VERSION "dbc-export 1 2026.26.6.5"

NS_ :

BS_:

BU_: ADSP APB APP APS APSB BB BMS CC CMP CMPD CP DAS DI DIF DIR DPB EPAS3P EPAS3S EPASTP EPASTS EPBL EPBR ESP EVSE FC GTW HCML HCMR HVP IBST ICR IDB LS OCS1P ODIN PARK PCS PCS2 PLG PM PMF PMR PNCD PTC RADC RCM RCM2 RCM3 RCU SCCM SCM SCS SDCR TAS TCU TCU2 TPMS TRCM UDS UI UIS UMC USM V2G VC VCBATT VCBATT0 VCBATT1 VCBATT2 VCCC VCFRONT VCFRONT1 VCFRONT2 VCLEFT VCRIGHT VCSEAT2L VCSEAT2R VCSEC VEH

BO_ 1290 HVP_alertLog: 8 HVP
 SG_ HVP_alertID M : 0|7@1+ (1,0) [0|127] "" Vector__XXX
 SG_ HVP_alertSet : 15|1@1+ (1,0) [0|1] "" Vector__XXX
 SG_ HVP_a005_current m5 : 16|24@1- (0.001,0) [-8388.608|8388.607] "A" Vector__XXX
 SG_ HVP_a006_current m6 : 16|24@1- (0.001,0) [-8388.608|8388.607] "A" Vector__XXX
 SG_ HVP_a007_current m7 : 16|24@1- (0.001,0) [-8388.608|8388.607] "A" Vector__XXX
 SG_ HVP_a008_temperature m8 : 16|16@1- (0.01,0) [-327.68|327.67] "C" Vector__XXX
 SG_ HVP_a008_sensorId m8 : 32|6@1+ (1,1) [1|64] "" Vector__XXX
 SG_ HVP_a008_primaryChainSensor m8 : 38|1@1+ (1,0) [0|1] "" Vector__XXX
 SG_ HVP_a009_brickVoltage m9 : 16|16@1- (0.001,0) [-32.768|32.767] "V" Vector__XXX
 SG_ HVP_a009_brickId m9 : 32|7@1+ (1,1) [1|128] "" Vector__XXX
 SG_ HVP_a009_primaryChainSensor m9 : 39|1@1+ (1,0) [0|1] "" Vector__XXX
 SG_ HVP_a010_brickVoltage m10 : 16|16@1- (0.001,0) [-32.768|32.767] "V" Vector__XXX
 SG_ HVP_a010_brickId m10 : 32|7@1+ (1,1) [1|128] "" Vector__XXX
 SG_ HVP_a010_primaryChainSensor m10 : 39|1@1+ (1,0) [0|1] "" Vector__XXX
 SG_ HVP_a012_breakLocationA m12 : 16|5@1+ (1,0) [0|31] "" Vector__XXX
 SG_ HVP_a012_bmbCommStatusTypeA m12 : 21|2@1+ (1,0) [0|3] "" Vector__XXX
 SG_ HVP_a012_breakLocationB m12 : 24|5@1+ (1,0) [0|31] "" Vector__XXX
 SG_ HVP_a012_bmbCommStatusTypeB m12 : 29|2@1+ (1,0) [0|3] "" Vector__XXX
 SG_ HVP_a013_breakLocationA m13 : 16|5@1+ (1,0) [0|31] "" Vector__XXX
 SG_ HVP_a013_bmbCommStatusTypeA m13 : 21|2@1+ (1,0) [0|3] "" Vector__XXX
 SG_ HVP_a013_breakLocationB m13 : 24|5@1+ (1,0) [0|31] "" Vector__XXX
 SG_ HVP_a013_bmbCommStatusTypeB m13 : 29|2@1+ (1,0) [0|3] "" Vector__XXX
 SG_ HVP_a013_bmbChainBreakType m13 : 32|3@1+ (1,0) [0|7] "" Vector__XXX
 SG_ HVP_a018_dcLinkVoltage m18 : 16|16@1+ (0.01,0) [0|655.35] "V" Vector__XXX
 SG_ HVP_a018_battery12V m18 : 32|12@1+ (0.1,0) [0|409.5] "V" Vector__XXX
 SG_ HVP_a018_remainingPcsPowerCycles m18 : 44|2@1+ (1,0) [0|3] "" Vector__XXX
 SG_ HVP_a018_remainingPcsRecoveriesA m18 : 46|2@1+ (1,0) [0|3] "" Vector__XXX
 SG_ HVP_a018_hvcHardwareSupportsCycl m18 : 48|1@1+ (1,0) [0|1] "" Vector__XXX
 SG_ HVP_a018_pcsHardwareOkToBePowerC m18 : 49|1@1+ (1,0) [0|1] "" Vector__XXX
 SG_ HVP_a018_gpioLogicPowerEnable m18 : 50|1@1+ (1,0) [0|1] "" Vector__XXX
 SG_ HVP_a018_gpioDcDcEnable m18 : 51|1@1+ (1,0) [0|1] "" Vector__XXX
 SG_ HVP_a018_gpioChgEnable m18 : 52|1@1+ (1,0) [0|1] "" Vector__XXX
 SG_ HVP_a020_energyReserveV m20 : 16|16@1+ (0.001,0) [0|65.534] "V" Vector__XXX
 SG_ HVP_a020_shuntCurrentAux m20 : 32|16@1- (0.1,0) [-3276.8|3276.7] "A" Vector__XXX
 SG_ HVP_a020_shuntTemperature m20 : 48|16@1- (0.01,0) [-327.68|327.67] "C" Vector__XXX
 SG_ HVP_a021_pyroStatus m21 : 16|2@1+ (1,0) [0|3] "" Vector__XXX
 SG_ HVP_a021_ErTestFailed m21 : 18|1@1+ (1,0) [0|1] "" Vector__XXX
 SG_ HVP_a021_HighSideSwitchTestFaile m21 : 19|1@1+ (1,0) [0|1] "" Vector__XXX
 SG_ HVP_a021_LowSideSwitchTestFailed m21 : 20|1@1+ (1,0) [0|1] "" Vector__XXX
 SG_ HVP_a021_RefCurrentTestFailed m21 : 21|1@1+ (1,0) [0|1] "" Vector__XXX
 SG_ HVP_a021_PyroLeakTestFailed m21 : 22|1@1+ (1,0) [0|1] "" Vector__XXX
 SG_ HVP_a021_SquibResTestFailed m21 : 23|1@1+ (1,0) [0|1] "" Vector__XXX
 SG_ HVP_a021_VstTestFailed m21 : 24|1@1+ (1,0) [0|1] "" Vector__XXX
 SG_ HVP_a021_SquibResistance m21 : 25|16@1+ (0.001,0) [0|65.534] "Ohm" Vector__XXX
 SG_ HVP_a021_OneShotSequence m21 : 41|1@1+ (1,0) [0|1] "" Vector__XXX
 SG_ HVP_a021_HighSide m21 : 42|1@1+ (1,0) [0|1] "" Vector__XXX
 SG_ HVP_a021_LowSide m21 : 43|1@1+ (1,0) [0|1] "" Vector__XXX
 SG_ HVP_a021_Aout m21 : 44|14@1+ (0.001,0) [0|16.382] "V" Vector__XXX
 SG_ HVP_a022_pyroStatus m22 : 16|2@1+ (1,0) [0|3] "" Vector__XXX
 SG_ HVP_a022_PyroLeakTestFailed m22 : 18|1@1+ (1,0) [0|1] "" Vector__XXX
 SG_ HVP_a022_OneShotSequence m22 : 19|1@1+ (1,0) [0|1] "" Vector__XXX
 SG_ HVP_a022_HighSide m22 : 20|1@1+ (1,0) [0|1] "" Vector__XXX
 SG_ HVP_a022_LowSide m22 : 21|1@1+ (1,0) [0|1] "" Vector__XXX
 SG_ HVP_a022_Aout m22 : 24|14@1+ (0.001,0) [0|16.382] "V" Vector__XXX
 SG_ HVP_a022_SquibResistance m22 : 40|16@1+ (0.001,0) [0|65.534] "Ohm" Vector__XXX
 SG_ HVP_a024_voltage m24 : 16|16@1+ (0.1,0) [0|6553.5] "V" Vector__XXX
 SG_ HVP_a025_voltage1 m25 : 16|16@1+ (0.1,0) [0|6553.5] "V" Vector__XXX
 SG_ HVP_a025_voltage2 m25 : 32|16@1+ (0.1,0) [0|6553.5] "V" Vector__XXX
 SG_ HVP_a025_packVoltage m25 : 48|16@1+ (0.1,0) [0|6553.5] "V" Vector__XXX
 SG_ HVP_a026_hvilStatus m26 : 16|4@1+ (1,0) [0|15] "" Vector__XXX
 SG_ HVP_a026_inputVoltage m26 : 24|8@1+ (0.04,0) [0|10.2] "V" Vector__XXX
 SG_ HVP_a026_outputVoltage m26 : 32|8@1+ (0.04,0) [0|10.2] "V" Vector__XXX
 SG_ HVP_a026_internalVoltage m26 : 40|8@1+ (0.04,0) [0|10.16] "V" Vector__XXX
 SG_ HVP_a026_dirVoltage m26 : 48|8@1+ (0.04,0) [0|10.16] "V" Vector__XXX
 SG_ HVP_a026_difVoltage m26 : 56|8@1+ (0.04,0) [0|10.16] "V" Vector__XXX
 SG_ HVP_a028_packVoltage m28 : 16|16@1+ (0.1,0) [0|6553.5] "V" Vector__XXX
 SG_ HVP_a028_sumOfBrickV m28 : 32|16@1+ (0.1,0) [0|6553.5] "V" Vector__XXX
 SG_ HVP_a030_packPositiveLinkV m30 : 16|16@1- (0.1,0) [-3276.8|3276.7] "V" Vector__XXX
 SG_ HVP_a030_dcPositiveLinkV m30 : 32|16@1- (0.1,0) [-3276.8|3276.7] "V" Vector__XXX
 SG_ HVP_a031_packNegativeLinkV m31 : 16|16@1- (0.1,0) [-3276.8|3276.7] "V" Vector__XXX
 SG_ HVP_a031_dcNegativeLinkV m31 : 32|16@1- (0.1,0) [-3276.8|3276.7] "V" Vector__XXX
 SG_ HVP_a033_contactorPowerV m33 : 16|16@1+ (0.1,0) [0|6553.5] "V" Vector__XXX
 SG_ HVP_a033_coilCurrent m33 : 32|16@1+ (0.1,0) [0|6553.5] "A" Vector__XXX
 SG_ HVP_a033_pwmDutyCylePositive m33 : 48|8@1+ (1,0) [0|255] "Percentage" Vector__XXX
 SG_ HVP_a033_pwmDutyCyleNegative m33 : 56|8@1+ (1,0) [0|255] "Percentage" Vector__XXX
 SG_ HVP_a035_contactorPowerV m35 : 16|16@1+ (0.1,0) [0|6553.5] "V" Vector__XXX
 SG_ HVP_a035_coilCurrent m35 : 32|16@1+ (0.1,0) [0|6553.5] "A" Vector__XXX
 SG_ HVP_a035_pwmDutyCylePositive m35 : 48|8@1+ (1,0) [0|255] "Percentage" Vector__XXX
 SG_ HVP_a035_pwmDutyCyleNegative m35 : 56|8@1+ (1,0) [0|255] "Percentage" Vector__XXX
 SG_ HVP_a036_pyroFiringHandle m36 : 16|4@1+ (1,0) [0|15] "" Vector__XXX
 SG_ HVP_a036_pyroFiringTime m36 : 24|16@1+ (1,0) [0|65535] "" Vector__XXX
 SG_ HVP_a036_pyroFiringAttempt m36 : 40|4@1+ (1,0) [0|15] "" Vector__XXX
 SG_ HVP_a037_pyroFiringHandle m37 : 16|4@1+ (1,0) [0|15] "" Vector__XXX
 SG_ HVP_a039_posContactorFailed m39 : 16|1@1+ (1,0) [0|1] "" Vector__XXX
 SG_ HVP_a039_negContactorFailed m39 : 17|1@1+ (1,0) [0|1] "" Vector__XXX
 SG_ HVP_a040_powerVoltage m40 : 16|8@1+ (0.1,0) [0|25.5] "V" Vector__XXX
 SG_ HVP_a040_coilCurrent m40 : 24|8@1+ (0.1,0) [0|25.5] "A" Vector__XXX
 SG_ HVP_a040_posCtrVoltageDrop m40 : 32|15@1- (0.1,0) [-1638.4|1638.3] "V" Vector__XXX
 SG_ HVP_a040_negCtrVoltageDrop m40 : 47|15@1- (0.1,0) [-1638.4|1638.3] "V" Vector__XXX
 SG_ HVP_a040_posCtrAuxOpen m40 : 62|1@1+ (1,0) [0|1] "" Vector__XXX
 SG_ HVP_a040_negCtrAuxOpen m40 : 63|1@1+ (1,0) [0|1] "" Vector__XXX
 SG_ HVP_a041_overCurrent m41 : 16|1@1+ (1,0) [0|1] "" Vector__XXX
 SG_ HVP_a041_overChargeCurrent m41 : 17|1@1+ (1,0) [0|1] "" Vector__XXX
 SG_ HVP_a041_overDischargeCurrent m41 : 18|1@1+ (1,0) [0|1] "" Vector__XXX
 SG_ HVP_a041_overVoltage m41 : 19|1@1+ (1,0) [0|1] "" Vector__XXX
 SG_ HVP_a041_overTemperature m41 : 20|1@1+ (1,0) [0|1] "" Vector__XXX
 SG_ HVP_a041_underVoltage m41 : 21|1@1+ (1,0) [0|1] "" Vector__XXX
 SG_ HVP_a041_crashEvent m41 : 22|1@1+ (1,0) [0|1] "" Vector__XXX
 SG_ HVP_a041_packContactorHw m41 : 23|1@1+ (1,0) [0|1] "" Vector__XXX
 SG_ HVP_a041_notAllowedtoEnergize m41 : 24|1@1+ (1,0) [0|1] "" Vector__XXX
 SG_ HVP_a041_bmbMia m41 : 25|1@1+ (1,0) [0|1] "" Vector__XXX
 SG_ HVP_a041_hvilFault m41 : 26|1@1+ (1,0) [0|1] "" Vector__XXX
 SG_ HVP_a041_contactorStateWelded m41 : 27|1@1+ (1,0) [0|1] "" Vector__XXX
 SG_ HVP_a041_shuntHwMia m41 : 28|1@1+ (1,0) [0|1] "" Vector__XXX
 SG_ HVP_a041_shuntCurrentMia m41 : 29|1@1+ (1,0) [0|1] "" Vector__XXX
 SG_ HVP_a041_packVoltageMismatch m41 : 30|1@1+ (1,0) [0|1] "" Vector__XXX
 SG_ HVP_a041_gpoRequestActive m41 : 31|1@1+ (1,0) [0|1] "" Vector__XXX
 SG_ HVP_a041_fcContactorClosing m41 : 32|1@1+ (1,0) [0|1] "" Vector__XXX
 SG_ HVP_a041_fcContactorOpening m41 : 33|1@1+ (1,0) [0|1] "" Vector__XXX
 SG_ HVP_a041_resetRequestRequired m41 : 34|1@1+ (1,0) [0|1] "" Vector__XXX
 SG_ HVP_a041_pyroFault m41 : 35|1@1+ (1,0) [0|1] "" Vector__XXX
 SG_ HVP_a041_dcLinkOverVoltage m41 : 36|1@1+ (1,0) [0|1] "" Vector__XXX
 SG_ HVP_a042_overCurrent m42 : 16|1@1+ (1,0) [0|1] "" Vector__XXX
 SG_ HVP_a042_overChargeCurrent m42 : 17|1@1+ (1,0) [0|1] "" Vector__XXX
 SG_ HVP_a042_overDischargeCurrent m42 : 18|1@1+ (1,0) [0|1] "" Vector__XXX
 SG_ HVP_a042_overVoltage m42 : 19|1@1+ (1,0) [0|1] "" Vector__XXX
 SG_ HVP_a042_overTemperature m42 : 20|1@1+ (1,0) [0|1] "" Vector__XXX
 SG_ HVP_a042_crashEvent m42 : 21|1@1+ (1,0) [0|1] "" Vector__XXX
 SG_ HVP_a042_fcContactorHw m42 : 22|1@1+ (1,0) [0|1] "" Vector__XXX
 SG_ HVP_a042_notAllowedtoEnergize m42 : 23|1@1+ (1,0) [0|1] "" Vector__XXX
 SG_ HVP_a042_bmsHvsMia m42 : 24|1@1+ (1,0) [0|1] "" Vector__XXX
 SG_ HVP_a042_cpMia m42 : 25|1@1+ (1,0) [0|1] "" Vector__XXX
 SG_ HVP_a042_cpFault m42 : 26|1@1+ (1,0) [0|1] "" Vector__XXX
 SG_ HVP_a042_supply12V m42 : 27|1@1+ (1,0) [0|1] "" Vector__XXX
 SG_ HVP_a042_supplyVer m42 : 28|1@1+ (1,0) [0|1] "" Vector__XXX
 SG_ HVP_a042_packVoltageMismatch m42 : 29|1@1+ (1,0) [0|1] "" Vector__XXX
 SG_ HVP_a042_hvilFault m42 : 30|1@1+ (1,0) [0|1] "" Vector__XXX
 SG_ HVP_a042_contactorStateWelded m42 : 31|1@1+ (1,0) [0|1] "" Vector__XXX
 SG_ HVP_a042_shuntHwMia m42 : 32|1@1+ (1,0) [0|1] "" Vector__XXX
 SG_ HVP_a042_shuntCurrentMia m42 : 33|1@1+ (1,0) [0|1] "" Vector__XXX
 SG_ HVP_a042_packContactorClosing m42 : 34|1@1+ (1,0) [0|1] "" Vector__XXX
 SG_ HVP_a042_packContactorOpening m42 : 35|1@1+ (1,0) [0|1] "" Vector__XXX
 SG_ HVP_a042_resetRequestRequired m42 : 36|1@1+ (1,0) [0|1] "" Vector__XXX
 SG_ HVP_a042_cpVersionMismatch m42 : 37|1@1+ (1,0) [0|1] "" Vector__XXX
 SG_ HVP_a043_overCurrent m43 : 16|1@1+ (1,0) [0|1] "" Vector__XXX
 SG_ HVP_a043_overChargeCurrent m43 : 17|1@1+ (1,0) [0|1] "" Vector__XXX
 SG_ HVP_a043_overDischargeCurrent m43 : 18|1@1+ (1,0) [0|1] "" Vector__XXX
 SG_ HVP_a043_overVoltage m43 : 19|1@1+ (1,0) [0|1] "" Vector__XXX
 SG_ HVP_a043_overTemperature m43 : 20|1@1+ (1,0) [0|1] "" Vector__XXX
 SG_ HVP_a043_underVoltage m43 : 21|1@1+ (1,0) [0|1] "" Vector__XXX
 SG_ HVP_a043_crashEvent m43 : 22|1@1+ (1,0) [0|1] "" Vector__XXX
 SG_ HVP_a043_packContactorHw m43 : 23|1@1+ (1,0) [0|1] "" Vector__XXX
 SG_ HVP_a043_notAllowedtoEnergize m43 : 24|1@1+ (1,0) [0|1] "" Vector__XXX
 SG_ HVP_a043_bmbMia m43 : 25|1@1+ (1,0) [0|1] "" Vector__XXX
 SG_ HVP_a043_contactorOpened m43 : 26|1@1+ (1,0) [0|1] "" Vector__XXX
 SG_ HVP_a044_overCurrent m44 : 16|1@1+ (1,0) [0|1] "" Vector__XXX
 SG_ HVP_a044_overChargeCurrent m44 : 17|1@1+ (1,0) [0|1] "" Vector__XXX
 SG_ HVP_a044_overDischargeCurrent m44 : 18|1@1+ (1,0) [0|1] "" Vector__XXX
 SG_ HVP_a044_overVoltage m44 : 19|1@1+ (1,0) [0|1] "" Vector__XXX
 SG_ HVP_a044_overTemperature m44 : 20|1@1+ (1,0) [0|1] "" Vector__XXX
 SG_ HVP_a044_crashEvent m44 : 21|1@1+ (1,0) [0|1] "" Vector__XXX
 SG_ HVP_a044_fcContactorHw m44 : 22|1@1+ (1,0) [0|1] "" Vector__XXX
 SG_ HVP_a044_notAllowedtoEnergize m44 : 23|1@1+ (1,0) [0|1] "" Vector__XXX
 SG_ HVP_a044_bmsHvsMia m44 : 24|1@1+ (1,0) [0|1] "" Vector__XXX
 SG_ HVP_a044_cpMia m44 : 25|1@1+ (1,0) [0|1] "" Vector__XXX
 SG_ HVP_a044_cpFault m44 : 26|1@1+ (1,0) [0|1] "" Vector__XXX
 SG_ HVP_a044_supply12V m44 : 27|1@1+ (1,0) [0|1] "" Vector__XXX
 SG_ HVP_a044_supplyVer m44 : 28|1@1+ (1,0) [0|1] "" Vector__XXX
 SG_ HVP_a044_packVoltageMismatch m44 : 29|1@1+ (1,0) [0|1] "" Vector__XXX
 SG_ HVP_a044_contactorOpened m44 : 30|1@1+ (1,0) [0|1] "" Vector__XXX
 SG_ HVP_a044_cpVersionMismatch m44 : 31|1@1+ (1,0) [0|1] "" Vector__XXX
 SG_ HVP_a045_dcLinkVoltage m45 : 16|16@1+ (0.1,0) [0|6553.5] "V" Vector__XXX
 SG_ HVP_a046_shuntCurrent m46 : 16|16@1- (0.1,0) [-3276.8|3276.7] "A" Vector__XXX
 SG_ HVP_a046_shuntTemperature m46 : 32|16@1- (0.01,0) [-327.68|327.67] "C" Vector__XXX
 SG_ HVP_a046_asicTemperature m46 : 48|16@1- (0.01,0) [-327.68|327.67] "C" Vector__XXX
 SG_ HVP_a047_shuntCurrent m47 : 16|16@1- (0.1,0) [-3276.8|3276.7] "A" Vector__XXX
 SG_ HVP_a047_auxCurrent m47 : 32|16@1- (0.1,0) [-3276.8|3276.7] "A" Vector__XXX
 SG_ HVP_a049_contactorPowerV m49 : 16|16@1+ (0.1,0) [0|6553.5] "V" Vector__XXX
 SG_ HVP_a049_coilCurrent m49 : 32|16@1+ (0.1,0) [0|6553.5] "A" Vector__XXX
 SG_ HVP_a049_posCtrState m49 : 48|3@1+ (1,0) [1|7] "" Vector__XXX
 SG_ HVP_a049_negCtrState m49 : 51|3@1+ (1,0) [1|7] "" Vector__XXX
 SG_ HVP_a050_contactorPowerV m50 : 16|16@1+ (0.1,0) [0|6553.5] "V" Vector__XXX
 SG_ HVP_a050_coilCurrent m50 : 32|16@1+ (0.1,0) [0|6553.5] "A" Vector__XXX
 SG_ HVP_a050_posCtrState m50 : 48|3@1+ (1,0) [1|7] "" Vector__XXX
 SG_ HVP_a050_negCtrState m50 : 51|3@1+ (1,0) [1|7] "" Vector__XXX
 SG_ HVP_a051_shuntTemperature m51 : 16|16@1- (0.01,0) [-327.68|327.67] "C" Vector__XXX
 SG_ HVP_a051_shuntCurrent m51 : 32|16@1- (0.1,0) [-3276.8|3276.7] "A" Vector__XXX
 SG_ HVP_a051_energyReserveV m51 : 48|16@1+ (0.001,0) [0|65.534] "V" Vector__XXX
 SG_ HVP_a053_packVoltage m53 : 16|16@1+ (0.01,0) [0|655.35] "V" Vector__XXX
 SG_ HVP_a053_dcLinkVoltage m53 : 32|16@1+ (0.01,0) [0|655.35] "V" Vector__XXX
 SG_ HVP_a056_diagnosis m56 : 16|2@1+ (1,0) [1|3] "" Vector__XXX
 SG_ HVP_a056_shuntCurrent m56 : 24|16@1- (0.1,0) [-3276.8|3276.7] "A" Vector__XXX
 SG_ HVP_a056_posPackContactorState m56 : 40|3@1+ (1,0) [1|7] "" Vector__XXX
 SG_ HVP_a056_negPackContactorState m56 : 43|3@1+ (1,0) [1|7] "" Vector__XXX
 SG_ HVP_a056_posFcContactorState m56 : 48|3@1+ (1,0) [1|7] "" Vector__XXX
 SG_ HVP_a056_negFcContactorState m56 : 51|3@1+ (1,0) [1|7] "" Vector__XXX
 SG_ HVP_a058_VrefSample m58 : 16|16@1+ (0.0001,0) [0|6.5535] "V" Vector__XXX
 SG_ HVP_a058_bmbDeviceId m58 : 32|4@1+ (1,1) [1|16] "" Vector__XXX
 SG_ HVP_a058_VrefStatus m58 : 36|2@1+ (1,0) [0|3] "" Vector__XXX
 SG_ HVP_a058_VrefType m58 : 38|2@1+ (1,0) [0|3] "" Vector__XXX
 SG_ HVP_a060_stackVoltage m60 : 16|16@1+ (0.00128,0) [0|83.8848] "V" Vector__XXX
 SG_ HVP_a060_sumBrickVoltage m60 : 32|16@1+ (0.00128,0) [0|83.8848] "V" Vector__XXX
 SG_ HVP_a060_stackId m60 : 48|8@1+ (1,1) [1|256] "" Vector__XXX
 SG_ HVP_a062_bmbDeviceMask m62 : 16|16@1+ (1,0) [0|65535] "" Vector__XXX
 SG_ HVP_a067_hvilTypeFromHvp m67 : 16|2@1+ (1,0) [0|3] "" Vector__XXX
 SG_ HVP_a067_hvilTypeFromGateway m67 : 18|2@1+ (1,0) [0|3] "" Vector__XXX
 SG_ HVP_a067_hvilTypeIsFromCal m67 : 20|1@1+ (1,0) [0|1] "" Vector__XXX
 SG_ HVP_a068_shuntTemperature m68 : 16|16@1- (0.01,0) [-327.68|327.67] "C" Vector__XXX
 SG_ HVP_a068_shuntCurrent m68 : 32|16@1- (0.1,0) [-3276.8|3276.7] "A" Vector__XXX
 SG_ HVP_a068_energyReserveV m68 : 48|16@1+ (0.001,0) [0|65.534] "V" Vector__XXX

BO_ 938 HVP_alertMatrix: 8 HVP
 SG_ HVP_matrixIndex M : 0|4@1+ (1,0) [0|15] "" Vector__XXX
 SG_ HVP_w001_WatchdogReset m0 : 4|1@1+ (1,0) [0|1] "" Vector__XXX
 SG_ HVP_w002_UnusedAlert2 m0 : 5|1@1+ (1,0) [0|1] "" Vector__XXX
 SG_ HVP_w003_SwAssertion m0 : 6|1@1+ (1,0) [0|1] "" Vector__XXX
 SG_ HVP_w004_CrashEvent m0 : 7|1@1+ (1,0) [0|1] "" Vector__XXX
 SG_ HVP_w005_OverDchgCurrentFault m0 : 8|1@1+ (1,0) [0|1] "" Vector__XXX
 SG_ HVP_w006_OverChargeCurrentFault m0 : 9|1@1+ (1,0) [0|1] "" Vector__XXX
 SG_ HVP_w007_OverCurrentFault m0 : 10|1@1+ (1,0) [0|1] "" Vector__XXX
 SG_ HVP_w008_OverTemperatureFault m0 : 11|1@1+ (1,0) [0|1] "" Vector__XXX
 SG_ HVP_w009_OverVoltageFault m0 : 12|1@1+ (1,0) [0|1] "" Vector__XXX
 SG_ HVP_w010_UnderVoltageFault m0 : 13|1@1+ (1,0) [0|1] "" Vector__XXX
 SG_ HVP_w011_PrimaryBmbMiaFault m0 : 14|1@1+ (1,0) [0|1] "" Vector__XXX
 SG_ HVP_w012_BmbDataIntegrityLoss m0 : 15|1@1+ (1,0) [0|1] "" Vector__XXX
 SG_ HVP_w013_BmbCommunication m0 : 16|1@1+ (1,0) [0|1] "" Vector__XXX
 SG_ HVP_w014_BmsMiaOnHviFault m0 : 17|1@1+ (1,0) [0|1] "" Vector__XXX
 SG_ HVP_w015_CpMiaFault m0 : 18|1@1+ (1,0) [0|1] "" Vector__XXX
 SG_ HVP_w016_PcsMiaFault m0 : 19|1@1+ (1,0) [0|1] "" Vector__XXX
 SG_ HVP_w017_GtwMiaFault m0 : 20|1@1+ (1,0) [0|1] "" Vector__XXX
 SG_ HVP_w018_powerCyclingPcs m0 : 21|1@1+ (1,0) [0|1] "" Vector__XXX
 SG_ HVP_w019_CpFault m0 : 22|1@1+ (1,0) [0|1] "" Vector__XXX
 SG_ HVP_w020_ShuntHwMiaFault m0 : 23|1@1+ (1,0) [0|1] "" Vector__XXX
 SG_ HVP_w021_PyroMiaFault m0 : 24|1@1+ (1,0) [0|1] "" Vector__XXX
 SG_ HVP_w022_PyroMiaWarning m0 : 25|1@1+ (1,0) [0|1] "" Vector__XXX
 SG_ HVP_w023_BmbResetRecovery m0 : 26|1@1+ (1,0) [0|1] "" Vector__XXX
 SG_ HVP_w024_Supply12vFault m0 : 27|1@1+ (1,0) [0|1] "" Vector__XXX
 SG_ HVP_w025_VerSupplyFault m0 : 28|1@1+ (1,0) [0|1] "" Vector__XXX
 SG_ HVP_w026_HvilFault m0 : 29|1@1+ (1,0) [0|1] "" Vector__XXX
 SG_ HVP_w027_BmsMiaOnHvsFault m0 : 30|1@1+ (1,0) [0|1] "" Vector__XXX
 SG_ HVP_w028_PackVoltMismatchFault m0 : 31|1@1+ (1,0) [0|1] "" Vector__XXX
 SG_ HVP_w029_EnsMiaFault m0 : 32|1@1+ (1,0) [0|1] "" Vector__XXX
 SG_ HVP_w030_PackPosCtrArcFault m0 : 33|1@1+ (1,0) [0|1] "" Vector__XXX
 SG_ HVP_w031_packNegCtrArcFault m0 : 34|1@1+ (1,0) [0|1] "" Vector__XXX
 SG_ HVP_w032_ShuntHwAndBmsMiaFault m0 : 35|1@1+ (1,0) [0|1] "" Vector__XXX
 SG_ HVP_w033_fcContHwFault m0 : 36|1@1+ (1,0) [0|1] "" Vector__XXX
 SG_ HVP_w034_cpMismatchFault m0 : 37|1@1+ (1,0) [0|1] "" Vector__XXX
 SG_ HVP_w035_packContHwFault m0 : 38|1@1+ (1,0) [0|1] "" Vector__XXX
 SG_ HVP_w036_pyroFuseBlown m0 : 39|1@1+ (1,0) [0|1] "" Vector__XXX
 SG_ HVP_w037_pyroFuseFailedToBlow m0 : 40|1@1+ (1,0) [0|1] "" Vector__XXX
 SG_ HVP_w038_CpilFault m0 : 41|1@1+ (1,0) [0|1] "" Vector__XXX
 SG_ HVP_w039_PackContactorFellOpen m0 : 42|1@1+ (1,0) [0|1] "" Vector__XXX
 SG_ HVP_w040_FcContactorFellOpen m0 : 43|1@1+ (1,0) [0|1] "" Vector__XXX
 SG_ HVP_w041_packCtrCloseBlocked m0 : 44|1@1+ (1,0) [0|1] "" Vector__XXX
 SG_ HVP_w042_fcCtrCloseBlocked m0 : 45|1@1+ (1,0) [0|1] "" Vector__XXX
 SG_ HVP_w043_packContactorForceOpen m0 : 46|1@1+ (1,0) [0|1] "" Vector__XXX
 SG_ HVP_w044_fcContactorForceOpen m0 : 47|1@1+ (1,0) [0|1] "" Vector__XXX
 SG_ HVP_w045_dcLinkOverVoltage m0 : 48|1@1+ (1,0) [0|1] "" Vector__XXX
 SG_ HVP_w046_shuntOverTemperature m0 : 49|1@1+ (1,0) [0|1] "" Vector__XXX
 SG_ HVP_w047_passivePyroDeploy m0 : 50|1@1+ (1,0) [0|1] "" Vector__XXX
 SG_ HVP_w048_swUnsupportedBmbAsicTyp m0 : 51|1@1+ (1,0) [0|1] "" Vector__XXX
 SG_ HVP_w049_packCtrCloseFailed m0 : 52|1@1+ (1,0) [0|1] "" Vector__XXX
 SG_ HVP_w050_fcCtrCloseFailed m0 : 53|1@1+ (1,0) [0|1] "" Vector__XXX
 SG_ HVP_w051_shuntThermistorMia m0 : 54|1@1+ (1,0) [0|1] "" Vector__XXX
 SG_ HVP_w052_BmbStatusRegError m0 : 55|1@1+ (1,0) [0|1] "" Vector__XXX
 SG_ HVP_w053_hvVoltageSensorRational m0 : 56|1@1+ (1,0) [0|1] "" Vector__XXX
 SG_ HVP_w054_swMissingConfigBlock m0 : 57|1@1+ (1,0) [0|1] "" Vector__XXX
 SG_ HVP_w055_swMissingPartNumber m0 : 58|1@1+ (1,0) [0|1] "" Vector__XXX
 SG_ HVP_w056_contactorFailedToOpen m0 : 59|1@1+ (1,0) [0|1] "" Vector__XXX
 SG_ HVP_w057_BatmanDiagnosticsError m0 : 60|1@1+ (1,0) [0|1] "" Vector__XXX
 SG_ HVP_w058_BmbVrefBad m0 : 61|1@1+ (1,0) [0|1] "" Vector__XXX
 SG_ HVP_w059_BmbVrefWarning m0 : 62|1@1+ (1,0) [0|1] "" Vector__XXX
 SG_ HVP_w060_StackVoltageSense m0 : 63|1@1+ (1,0) [0|1] "" Vector__XXX
 SG_ HVP_w061_ShuntCurrentRationality m1 : 4|1@1+ (1,0) [0|1] "" Vector__XXX
 SG_ HVP_w062_BmbOtpConfigError m1 : 5|1@1+ (1,0) [0|1] "" Vector__XXX
 SG_ HVP_w063_BmbBrickVRationality m1 : 6|1@1+ (1,0) [0|1] "" Vector__XXX
 SG_ HVP_w064_BmbAuxVRationality m1 : 7|1@1+ (1,0) [0|1] "" Vector__XXX
 SG_ HVP_w065_FastOpenVshDetected m1 : 8|1@1+ (1,0) [0|1] "" Vector__XXX
 SG_ HVP_w067_HvilCalNodeMismatch m1 : 10|1@1+ (1,0) [0|1] "" Vector__XXX
 SG_ HVP_w068_shuntUnexpectedThermist m1 : 11|1@1+ (1,0) [0|1] "" Vector__XXX
 SG_ HVP_w069_hviCanFrameRxDropped m1 : 12|1@1+ (1,0) [0|1] "" Vector__XXX
 SG_ HVP_w070_hvsCanFrameRxDropped m1 : 13|1@1+ (1,0) [0|1] "" Vector__XXX
 SG_ HVP_w071_PassivePyroVrefRational m1 : 14|1@1+ (1,0) [0|1] "" Vector__XXX

BO_ 522 HVP_contactorState: 6 HVP
 SG_ HVP_packContNegativeState : 0|3@1+ (1,0) [1|7] "" Vector__XXX
 SG_ HVP_packContPositiveState : 3|3@1+ (1,0) [1|7] "" Vector__XXX
 SG_ HVP_fcContPositiveAuxOpen : 6|1@1+ (1,0) [0|1] "" Vector__XXX
 SG_ HVP_fcContNegativeAuxOpen : 7|1@1+ (1,0) [0|1] "" Vector__XXX
 SG_ HVP_packContactorSetState : 8|4@1+ (1,0) [1|15] "" Vector__XXX
 SG_ HVP_fcContNegativeState : 12|3@1+ (1,0) [1|7] "" Vector__XXX
 SG_ HVP_contactorsBlocked : 15|1@1+ (1,0) [0|1] "" Vector__XXX
 SG_ HVP_fcContPositiveState : 16|3@1+ (1,0) [1|7] "" Vector__XXX
 SG_ HVP_fcContactorSetState : 19|4@1+ (1,0) [1|15] "" Vector__XXX
 SG_ HVP_fcCtrsRequestStatus : 24|2@1+ (1,0) [0|3] "" Vector__XXX
 SG_ HVP_fcCtrsResetRequestRequired : 26|1@1+ (1,0) [0|1] "" Vector__XXX
 SG_ HVP_fcCtrsOpenNowRequested : 27|1@1+ (1,0) [0|1] "" Vector__XXX
 SG_ HVP_fcCtrsOpenRequested : 28|1@1+ (1,0) [0|1] "" Vector__XXX
 SG_ HVP_fcCtrsClosingAllowed : 29|1@1+ (1,0) [0|1] "" Vector__XXX
 SG_ HVP_packCtrsRequestStatus : 30|2@1+ (1,0) [0|3] "" Vector__XXX
 SG_ HVP_packCtrsResetRequestRequired : 32|1@1+ (1,0) [0|1] "" Vector__XXX
 SG_ HVP_packCtrsOpenNowRequested : 33|1@1+ (1,0) [0|1] "" Vector__XXX
 SG_ HVP_packCtrsOpenRequested : 34|1@1+ (1,0) [0|1] "" Vector__XXX
 SG_ HVP_packCtrsClosingAllowed : 35|1@1+ (1,0) [0|1] "" Vector__XXX
 SG_ HVP_dcLinkAllowedToEnergize : 36|1@1+ (1,0) [0|1] "" Vector__XXX
 SG_ HVP_pyroTestInProgress : 37|1@1+ (1,0) [0|1] "" Vector__XXX
 SG_ HVP_hvilDiag : 40|4@1+ (1,0) [0|15] "" Vector__XXX
 SG_ HVP_fcLinkAllowedToEnergize : 44|2@1+ (1,0) [0|3] "" Vector__XXX

BO_ 1962 HVP_debugMessage: 8 HVP
 SG_ HVP_debugMessageMultiplexer M : 0|4@1+ (1,0) [0|15] "" Vector__XXX
 SG_ HVP_ecuLogUploadRequest m1 : 4|2@1+ (1,0) [0|3] "" Vector__XXX
 SG_ HVP_dcLinkVoltage m1 : 8|16@1- (0.1,0) [-3276.8|3276.7] "V" Vector__XXX
 SG_ HVP_packVoltage m1 : 24|16@1- (0.1,0) [-3276.8|3276.7] "V" Vector__XXX
 SG_ HVP_fcLinkVoltage m1 : 40|16@1- (0.1,0) [-3276.8|3276.7] "V" Vector__XXX
 SG_ HVP_10HzTask_stackUsage m1 : 56|7@1+ (1,0) [0|100] "%" Vector__XXX
 SG_ HVP_packContVoltage m2 : 4|12@1+ (0.1,0) [0|30] "V" Vector__XXX
 SG_ HVP_packNegativeV m2 : 16|16@1- (0.1,0) [-550|550] "V" Vector__XXX
 SG_ HVP_packPositiveV m2 : 32|16@1- (0.1,0) [-550|550] "V" Vector__XXX
 SG_ HVP_pyroAnalog m2 : 48|12@1+ (0.1,0) [0|3] "V" Vector__XXX
 SG_ HVP_shuntSetTCRCoeffA m2 : 60|1@1+ (1,0) [0|1] "" Vector__XXX
 SG_ HVP_shuntSetTCRCoeffB m2 : 61|1@1+ (1,0) [0|1] "" Vector__XXX
 SG_ HVP_shuntSetTCRCoeffC m2 : 62|1@1+ (1,0) [0|1] "" Vector__XXX
 SG_ HVP_shuntSetTCRCoeffD m2 : 63|1@1+ (1,0) [0|1] "" Vector__XXX
 SG_ HVP_fcContCoilCurrent m4 : 4|12@1+ (0.1,0) [0|7.5] "A" Vector__XXX
 SG_ HVP_fcContVoltage m4 : 16|12@1+ (0.1,0) [0|30] "V" Vector__XXX
 SG_ HVP_hvilInVoltage m4 : 28|12@1+ (0.1,0) [0|30] "V" Vector__XXX
 SG_ HVP_hvilOutVoltage m4 : 40|12@1+ (0.1,0) [0|30] "V" Vector__XXX
 SG_ HVP_shuntGainInvalidCountDbg m4 : 56|8@1+ (1,0) [0|255] "counts" Vector__XXX
 SG_ HVP_passivePyroRefVoltageMax m5 : 4|10@1+ (0.001,0.7) [0.7|1.722] "V" Vector__XXX
 SG_ HVP_passivePyroRefVoltageMin m5 : 14|10@1+ (0.001,0.7) [0.7|1.722] "V" Vector__XXX
 SG_ HVP_packContCoilCurrent m5 : 24|12@1+ (0.1,0) [0|7.5] "A" Vector__XXX
 SG_ HVP_battery12V m5 : 36|12@1+ (0.1,0) [0|30] "V" Vector__XXX
 SG_ HVP_fcLinkPositiveV m5 : 48|16@1- (0.1,0) [-550|550] "V" Vector__XXX

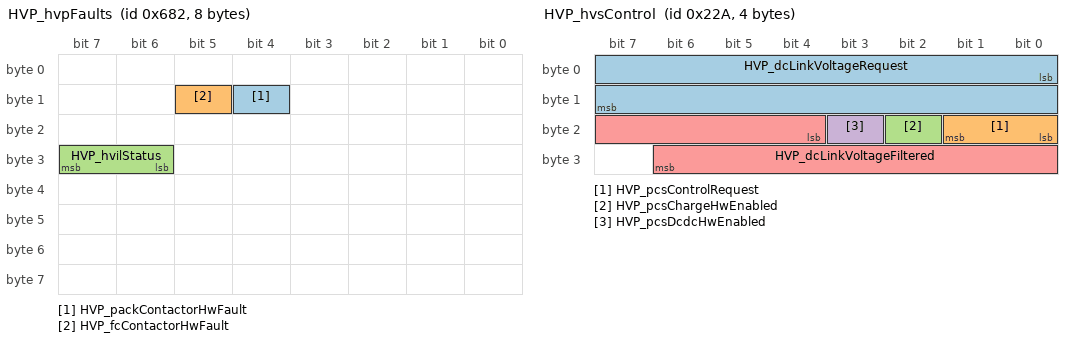
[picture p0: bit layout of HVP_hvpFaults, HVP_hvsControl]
BO_ 1666 HVP_hvpFaults: 8 HVP
 SG_ HVP_packContactorHwFault : 12|1@1+ (1,0) [0|1] "" Vector__XXX
 SG_ HVP_fcContactorHwFault : 13|1@1+ (1,0) [0|1] "" Vector__XXX
 SG_ HVP_hvilStatus : 30|2@1+ (1,0) [0|2] "" Vector__XXX

BO_ 554 HVP_hvsControl: 4 HVP
 SG_ HVP_dcLinkVoltageRequest : 0|16@1- (0.1,0) [-550|550] "V" Vector__XXX
 SG_ HVP_pcsControlRequest : 16|2@1+ (1,0) [0|3] "" Vector__XXX
 SG_ HVP_pcsChargeHwEnabled : 18|1@1+ (1,0) [0|1] "" Vector__XXX
 SG_ HVP_pcsDcdcHwEnabled : 19|1@1+ (1,0) [0|1] "" Vector__XXX
 SG_ HVP_dcLinkVoltageFiltered : 20|11@1- (1,0) [-550|550] "V" Vector__XXX

BO_ 2029 HVP_info: 8 HVP
 SG_ HVP_infoIndex M : 0|8@1+ (1,0) [0|255] "" Vector__XXX
 SG_ HVP_buildType m10 : 8|3@1+ (1,0) [0|7] "" Vector__XXX
 SG_ HVP_buildConfigId m10 : 16|16@1+ (1,0) [0|65535] "" Vector__XXX
 SG_ HVP_hardwareId m10 : 32|16@1+ (1,0) [0|65535] "" Vector__XXX
 SG_ HVP_componentId m10 : 48|16@1+ (1,0) [0|65535] "" Vector__XXX
 SG_ HVP_pcbaId m11 : 16|8@1+ (1,0) [0|255] "" Vector__XXX
 SG_ HVP_assemblyId m11 : 24|8@1+ (1,0) [0|255] "" Vector__XXX
 SG_ HVP_usageId m11 : 32|16@1+ (1,0) [0|65535] "" Vector__XXX
 SG_ HVP_subUsageId m11 : 48|16@1+ (1,0) [0|65535] "" Vector__XXX
 SG_ HVP_platformType m13 : 8|8@1+ (1,0) [0|255] "" Vector__XXX
 SG_ HVP_appCrc m13 : 32|32@1+ (1,0) [0|4294967295] "" Vector__XXX
 SG_ HVP_appGitHash m17 : 8|56@1+ (1,0) [0|7.20575940379e+16] "" Vector__XXX
 SG_ HVP_bootGitHash m18 : 8|56@1+ (1,0) [0|7.20575940379e+16] "" Vector__XXX
 SG_ HVP_bootUdsProtoVersion m20 : 8|8@1+ (1,0) [0|255] "" Vector__XXX
 SG_ HVP_bootCrc m20 : 32|32@1+ (1,0) [0|4294967295] "" Vector__XXX

BO_ 1914 HVP_log1hz: 8 HVP
 SG_ HVP_log1HzIndex M : 0|3@1+ (1,0) [0|7] "" Vector__XXX
 SG_ HVP_bmbAsicType m0 : 3|2@1+ (1,0) [0|3] "" Vector__XXX
 SG_ HVP_shuntCurrentAuxLog m0 : 8|24@1- (0.001,0) [-8388.607|8388.607] "A" Vector__XXX
 SG_ HVP_pyroSquibResistance m0 : 32|16@1+ (0.001,0) [0|65.534] "Ohm" Vector__XXX
 SG_ HVP_shuntAsicChipXCoordinate m0 : 48|8@1+ (1,0) [0|255] "" Vector__XXX
 SG_ HVP_shuntAsicChipYCoordinate m0 : 56|8@1+ (1,0) [0|255] "" Vector__XXX
 SG_ HVP_hvilCalType m1 : 3|2@1+ (1,0) [0|3] "" Vector__XXX
 SG_ HVP_gpioPcsDcdcPwmEnable m1 : 5|1@1+ (1,0) [0|1] "" Vector__XXX
 SG_ HVP_gpioPcsChargePwmEnable m1 : 6|1@1+ (1,0) [0|1] "" Vector__XXX
 SG_ HVP_gpioPcsEnable m1 : 7|1@1+ (1,0) [0|1] "" Vector__XXX
 SG_ HVP_shuntAsicChipWaferNumber m1 : 8|8@1+ (1,0) [0|255] "" Vector__XXX
 SG_ HVP_energyReserveMin m1 : 16|16@1- (0.001,0) [-32.768|32.767] "V" Vector__XXX
 SG_ HVP_energyReserveMax m1 : 32|16@1- (0.001,0) [-32.768|32.767] "V" Vector__XXX
 SG_ HVP_energyReserveAvg m1 : 48|16@1- (0.001,0) [-32.768|32.767] "V" Vector__XXX

BO_ 1553 HVP_udsResponse: 8 HVP
 SG_ HVP_udsResponseData : 7|64@0+ (1,0) [0|1.84467440737e+19] "" Vector__XXX

BO_ 861 IBST_alertMatrix: 8 IBST
 SG_ IBST_matrixIndex M : 0|4@1+ (1,0) [0|15] "" Vector__XXX
 SG_ IBST_a001_microSupplyError m0 : 4|1@1+ (1,0) [0|1] "" Vector__XXX
 SG_ IBST_a002_HWBISTError m0 : 5|1@1+ (1,0) [0|1] "" Vector__XXX
 SG_ IBST_a003_RAMFault m0 : 6|1@1+ (1,0) [0|1] "" Vector__XXX
 SG_ IBST_a004_flashFault m0 : 7|1@1+ (1,0) [0|1] "" Vector__XXX
 SG_ IBST_a005_microSafetyFault m0 : 8|1@1+ (1,0) [0|1] "" Vector__XXX
 SG_ IBST_a006_microSafetyLogicFault m0 : 9|1@1+ (1,0) [0|1] "" Vector__XXX
 SG_ IBST_a007_RBCPUException m0 : 10|1@1+ (1,0) [0|1] "" Vector__XXX
 SG_ IBST_a008_stackOverUnderFlow m0 : 11|1@1+ (1,0) [0|1] "" Vector__XXX
 SG_ IBST_a009_systemErrorHook m0 : 12|1@1+ (1,0) [0|1] "" Vector__XXX
 SG_ IBST_a010_OSErrorHook m0 : 13|1@1+ (1,0) [0|1] "" Vector__XXX
 SG_ IBST_a011_systemTaskOverRun m0 : 14|1@1+ (1,0) [0|1] "" Vector__XXX
 SG_ IBST_a012_OSTaskSchemeError m0 : 15|1@1+ (1,0) [0|1] "" Vector__XXX
 SG_ IBST_a013_systemTaskJitter m0 : 16|1@1+ (1,0) [0|1] "" Vector__XXX
 SG_ IBST_a014_DMATransferError m0 : 17|1@1+ (1,0) [0|1] "" Vector__XXX
 SG_ IBST_a015_asicOscillatorError m0 : 18|1@1+ (1,0) [0|1] "" Vector__XXX
 SG_ IBST_a016_RBBLMShaftShiftError m0 : 19|1@1+ (1,0) [0|1] "" Vector__XXX
 SG_ IBST_a017_assertionFault m0 : 20|1@1+ (1,0) [0|1] "" Vector__XXX
 SG_ IBST_a018_unsupportedHW m0 : 21|1@1+ (1,0) [0|1] "" Vector__XXX
 SG_ IBST_a019_supplyASICInitFault m0 : 22|1@1+ (1,0) [0|1] "" Vector__XXX
 SG_ IBST_a020_VPREU5VOutOfRange m0 : 23|1@1+ (1,0) [0|1] "" Vector__XXX
 SG_ IBST_a021_IREFOutOfRange m0 : 24|1@1+ (1,0) [0|1] "" Vector__XXX
 SG_ IBST_a022_U5VTestFault m0 : 25|1@1+ (1,0) [0|1] "" Vector__XXX
 SG_ IBST_a023_U5VOutOfRange m0 : 26|1@1+ (1,0) [0|1] "" Vector__XXX
 SG_ IBST_a024_chargePumpFault m0 : 27|1@1+ (1,0) [0|1] "" Vector__XXX
 SG_ IBST_a025_ecuClockTestFault m0 : 28|1@1+ (1,0) [0|1] "" Vector__XXX
 SG_ IBST_a026_ecuBistCmdTestFault m0 : 29|1@1+ (1,0) [0|1] "" Vector__XXX
 SG_ IBST_a027_ecuFastWdTestFault m0 : 30|1@1+ (1,0) [0|1] "" Vector__XXX
 SG_ IBST_a028_ecuBistFaultCtrFault m0 : 31|1@1+ (1,0) [0|1] "" Vector__XXX
 SG_ IBST_a029_ecuErrpinCounterFault m0 : 32|1@1+ (1,0) [0|1] "" Vector__XXX
 SG_ IBST_a030_ecuEnableElLowFault m0 : 33|1@1+ (1,0) [0|1] "" Vector__XXX
 SG_ IBST_a031_decoupleBitTestFault m0 : 34|1@1+ (1,0) [0|1] "" Vector__XXX
 SG_ IBST_a032_ecuEnableElHighFault m0 : 35|1@1+ (1,0) [0|1] "" Vector__XXX
 SG_ IBST_a033_ecuWdStartuptestFault m0 : 36|1@1+ (1,0) [0|1] "" Vector__XXX
 SG_ IBST_a034_ecuEnableHyHighFault m0 : 37|1@1+ (1,0) [0|1] "" Vector__XXX
 SG_ IBST_a035_ecuEnableHyLowFault m0 : 38|1@1+ (1,0) [0|1] "" Vector__XXX
 SG_ IBST_a036_MRGPathTestFault m0 : 39|1@1+ (1,0) [0|1] "" Vector__XXX
 SG_ IBST_a037_ecuWdSContinuousError m0 : 40|1@1+ (1,0) [0|1] "" Vector__XXX
 SG_ IBST_a038_ecuEnContinuousError m0 : 41|1@1+ (1,0) [0|1] "" Vector__XXX
 SG_ IBST_a039_GTMRefFrequencyError m0 : 42|1@1+ (1,0) [0|1] "" Vector__XXX
 SG_ IBST_a040_GTMTbuMonError m0 : 43|1@1+ (1,0) [0|1] "" Vector__XXX
 SG_ IBST_a041_micAsicClkInError m0 : 44|1@1+ (1,0) [0|1] "" Vector__XXX
 SG_ IBST_a042_micAsicInitTestError m0 : 45|1@1+ (1,0) [0|1] "" Vector__XXX
 SG_ IBST_a043_micSpiTransferError m0 : 46|1@1+ (1,0) [0|1] "" Vector__XXX
 SG_ IBST_a044_NvMEepromWIP m0 : 47|1@1+ (1,0) [0|1] "" Vector__XXX
 SG_ IBST_a045_WdhAsicWdErrorCntStuck m0 : 48|1@1+ (1,0) [0|1] "" Vector__XXX
 SG_ IBST_a046_WdhAsicWdErrorCntLimit m0 : 49|1@1+ (1,0) [0|1] "" Vector__XXX
 SG_ IBST_a047_WdhAsicWdCmdMissing m0 : 50|1@1+ (1,0) [0|1] "" Vector__XXX
 SG_ IBST_a048_WdhSwBistConCnt m0 : 51|1@1+ (1,0) [0|1] "" Vector__XXX
 SG_ IBST_a049_WdhTaskMonConCnt m0 : 52|1@1+ (1,0) [0|1] "" Vector__XXX
 SG_ IBST_a050_VPreExternalFeeding m0 : 53|1@1+ (1,0) [0|1] "" Vector__XXX
 SG_ IBST_a051_ecuBandgap m0 : 54|1@1+ (1,0) [0|1] "" Vector__XXX
 SG_ IBST_a052_AdcPinTest m0 : 55|1@1+ (1,0) [0|1] "" Vector__XXX
 SG_ IBST_a053_AdcSelftestC5P m0 : 56|1@1+ (1,0) [0|1] "" Vector__XXX
 SG_ IBST_a054_AdcPeripheralFault m0 : 57|1@1+ (1,0) [0|1] "" Vector__XXX
 SG_ IBST_a055_UB6SupplyPathFault m0 : 58|1@1+ (1,0) [0|1] "" Vector__XXX
 SG_ IBST_a056_UB6PlausiMonFault m0 : 59|1@1+ (1,0) [0|1] "" Vector__XXX
 SG_ IBST_a057_microRegisterFault m0 : 60|1@1+ (1,0) [0|1] "" Vector__XXX
 SG_ IBST_a058_NvMWriteCycleExceed m0 : 61|1@1+ (1,0) [0|1] "" Vector__XXX
 SG_ IBST_a059_NvMEepromSize m0 : 62|1@1+ (1,0) [0|1] "" Vector__XXX
 SG_ IBST_a060_NvMMigrationFault m0 : 63|1@1+ (1,0) [0|1] "" Vector__XXX
 SG_ IBST_a061_AswSystemTimeOut m1 : 4|1@1+ (1,0) [0|1] "" Vector__XXX
 SG_ IBST_a062_MICB6TransferError m1 : 5|1@1+ (1,0) [0|1] "" Vector__XXX
 SG_ IBST_a063_tempSens2ShortToSupply m1 : 6|1@1+ (1,0) [0|1] "" Vector__XXX
 SG_ IBST_a064_tempSens1ShortToGround m1 : 7|1@1+ (1,0) [0|1] "" Vector__XXX
 SG_ IBST_a065_tempSens2ShortToGround m1 : 8|1@1+ (1,0) [0|1] "" Vector__XXX
 SG_ IBST_a066_tempSens1ShortToSupply m1 : 9|1@1+ (1,0) [0|1] "" Vector__XXX
 SG_ IBST_a067_tempSensImplausVoltage m1 : 10|1@1+ (1,0) [0|1] "" Vector__XXX
 SG_ IBST_a068_chargePumpUndervoltage m1 : 11|1@1+ (1,0) [0|1] "" Vector__XXX
 SG_ IBST_a069_greasingRoutineFault m1 : 12|1@1+ (1,0) [0|1] "" Vector__XXX
 SG_ IBST_a070_notShutDownNvMWrite m1 : 13|1@1+ (1,0) [0|1] "" Vector__XXX
 SG_ IBST_a071_notShutDownNvMRead m1 : 14|1@1+ (1,0) [0|1] "" Vector__XXX
 SG_ IBST_a072_notShutDownRight m1 : 15|1@1+ (1,0) [0|1] "" Vector__XXX
 SG_ IBST_a073_jumpInAdjustNvMRead m1 : 16|1@1+ (1,0) [0|1] "" Vector__XXX
 SG_ IBST_a074_FindIdleDataNvMWrite m1 : 17|1@1+ (1,0) [0|1] "" Vector__XXX
 SG_ IBST_a075_FindIdleRoutineFault m1 : 18|1@1+ (1,0) [0|1] "" Vector__XXX
 SG_ IBST_a076_masterCylLengthRead m1 : 19|1@1+ (1,0) [0|1] "" Vector__XXX
 SG_ IBST_a077_runOutMotorSaturated m1 : 20|1@1+ (1,0) [0|1] "" Vector__XXX
 SG_ IBST_a078_wearOffsetCompNVMRead m1 : 21|1@1+ (1,0) [0|1] "" Vector__XXX
 SG_ IBST_a079_motorTempHighLevel1 m1 : 22|1@1+ (1,0) [0|1] "" Vector__XXX
 SG_ IBST_a080_motorTempHighLevel2 m1 : 23|1@1+ (1,0) [0|1] "" Vector__XXX
 SG_ IBST_a081_travelDeviation m1 : 24|1@1+ (1,0) [0|1] "" Vector__XXX
 SG_ IBST_a082_motorSpeedDeviation m1 : 25|1@1+ (1,0) [0|1] "" Vector__XXX
 SG_ IBST_a083_spindlePositionTooHigh m1 : 26|1@1+ (1,0) [0|1] "" Vector__XXX
 SG_ IBST_a084_CANTransceiverHWFault m1 : 27|1@1+ (1,0) [0|1] "" Vector__XXX
 SG_ IBST_a085_supplyUndervoltageLvl3 m1 : 28|1@1+ (1,0) [0|1] "" Vector__XXX
 SG_ IBST_a086_supplyOvervoltageLvl3 m1 : 29|1@1+ (1,0) [0|1] "" Vector__XXX
 SG_ IBST_a087_rotorSinOutOfRangeLow m1 : 30|1@1+ (1,0) [0|1] "" Vector__XXX
 SG_ IBST_a088_rotorCosOutOfRangeLow m1 : 31|1@1+ (1,0) [0|1] "" Vector__XXX
 SG_ IBST_a089_rotorSinOutOfRangeHigh m1 : 32|1@1+ (1,0) [0|1] "" Vector__XXX
 SG_ IBST_a090_rotorCosOutOfRangeHigh m1 : 33|1@1+ (1,0) [0|1] "" Vector__XXX
 SG_ IBST_a091_SMMOneRequestsInit m1 : 34|1@1+ (1,0) [0|1] "" Vector__XXX
 SG_ IBST_a092_systemStartTimeOut m1 : 35|1@1+ (1,0) [0|1] "" Vector__XXX
 SG_ IBST_a093_UEXSOvertemperature m1 : 36|1@1+ (1,0) [0|1] "" Vector__XXX
 SG_ IBST_a094_XPASSEchoTimeDeviation m1 : 37|1@1+ (1,0) [0|1] "" Vector__XXX
 SG_ IBST_a095_XPASSTimeOut m1 : 38|1@1+ (1,0) [0|1] "" Vector__XXX
 SG_ IBST_a096_bridgeDriverMonError m1 : 39|1@1+ (1,0) [0|1] "" Vector__XXX
 SG_ IBST_a097_bridgeDriverError m1 : 40|1@1+ (1,0) [0|1] "" Vector__XXX
 SG_ IBST_a098_bridgeShortedPhase m1 : 41|1@1+ (1,0) [0|1] "" Vector__XXX
 SG_ IBST_a099_bridgeSwitchInitError m1 : 42|1@1+ (1,0) [0|1] "" Vector__XXX
 SG_ IBST_a100_current2OffsetHigh m1 : 43|1@1+ (1,0) [0|1] "" Vector__XXX
 SG_ IBST_a101_current2OffsetLow m1 : 44|1@1+ (1,0) [0|1] "" Vector__XXX
 SG_ IBST_a102_current1OffsetHigh m1 : 45|1@1+ (1,0) [0|1] "" Vector__XXX
 SG_ IBST_a103_current1OffsetLow m1 : 46|1@1+ (1,0) [0|1] "" Vector__XXX
 SG_ IBST_a104_bridgeDriverShort m1 : 47|1@1+ (1,0) [0|1] "" Vector__XXX
 SG_ IBST_a105_LiPSUndervoltage m1 : 48|1@1+ (1,0) [0|1] "" Vector__XXX
 SG_ IBST_a106_LiPS5VSupply m1 : 49|1@1+ (1,0) [0|1] "" Vector__XXX
 SG_ IBST_a107_LiPS2PwmLineHigh m1 : 50|1@1+ (1,0) [0|1] "" Vector__XXX
 SG_ IBST_a108_LiPS2PwmLineLow m1 : 51|1@1+ (1,0) [0|1] "" Vector__XXX
 SG_ IBST_a109_LiPS2PwmTransmission m1 : 52|1@1+ (1,0) [0|1] "" Vector__XXX
 SG_ IBST_a110_LiPS1SentLineHigh m1 : 53|1@1+ (1,0) [0|1] "" Vector__XXX
 SG_ IBST_a111_LiPS1SentLineLow m1 : 54|1@1+ (1,0) [0|1] "" Vector__XXX
 SG_ IBST_a112_LiPS1SentTransmission m1 : 55|1@1+ (1,0) [0|1] "" Vector__XXX
 SG_ IBST_a113_LiPS1SentSensor m1 : 56|1@1+ (1,0) [0|1] "" Vector__XXX
 SG_ IBST_a114_partyBusOff m1 : 57|1@1+ (1,0) [0|1] "" Vector__XXX
 SG_ IBST_a115_chassisBusOff m1 : 58|1@1+ (1,0) [0|1] "" Vector__XXX
 SG_ IBST_a116_supplyUndervoltageLvl2 m1 : 59|1@1+ (1,0) [0|1] "" Vector__XXX
 SG_ IBST_a117_supplyOvervoltageLvl2 m1 : 60|1@1+ (1,0) [0|1] "" Vector__XXX
 SG_ IBST_a118_RPSNvMReadFault m1 : 61|1@1+ (1,0) [0|1] "" Vector__XXX
 SG_ IBST_a119_RPSWrongCalibData m1 : 62|1@1+ (1,0) [0|1] "" Vector__XXX
 SG_ IBST_a120_RPSVectorRangeHigh m1 : 63|1@1+ (1,0) [0|1] "" Vector__XXX
 SG_ IBST_a121_RPSVectorRangeLow m2 : 4|1@1+ (1,0) [0|1] "" Vector__XXX
 SG_ IBST_a122_RPSVectorOscillating m2 : 5|1@1+ (1,0) [0|1] "" Vector__XXX
 SG_ IBST_a123_bridgeDriverUnavail m2 : 6|1@1+ (1,0) [0|1] "" Vector__XXX
 SG_ IBST_a124_OBDCurrent1OORHigh m2 : 7|1@1+ (1,0) [0|1] "" Vector__XXX
 SG_ IBST_a125_OBDCurrent2OORHigh m2 : 8|1@1+ (1,0) [0|1] "" Vector__XXX
 SG_ IBST_a126_OBDCurrent1OORLow m2 : 9|1@1+ (1,0) [0|1] "" Vector__XXX
 SG_ IBST_a127_OBDCurrent2OORLow m2 : 10|1@1+ (1,0) [0|1] "" Vector__XXX
 SG_ IBST_a128_BLMMuxerTimeoutError m2 : 11|1@1+ (1,0) [0|1] "" Vector__XXX
 SG_ IBST_a129_loadDumpOnFSLTest m2 : 12|1@1+ (1,0) [0|1] "" Vector__XXX
 SG_ IBST_a130_DTSFunctionalRangeLow m2 : 13|1@1+ (1,0) [0|1] "" Vector__XXX
 SG_ IBST_a131_DTSFunctionalRangeHigh m2 : 14|1@1+ (1,0) [0|1] "" Vector__XXX
 SG_ IBST_a132_DTSPlausiCheck1vs2 m2 : 15|1@1+ (1,0) [0|1] "" Vector__XXX
 SG_ IBST_a133_DTSOffsetTooLow m2 : 16|1@1+ (1,0) [0|1] "" Vector__XXX
 SG_ IBST_a134_DTSOffsetTooHigh m2 : 17|1@1+ (1,0) [0|1] "" Vector__XXX
 SG_ IBST_a135_ESPparty1DLC m2 : 18|1@1+ (1,0) [0|1] "" Vector__XXX
 SG_ IBST_a136_ESPparty1Timeout m2 : 19|1@1+ (1,0) [0|1] "" Vector__XXX
 SG_ IBST_a137_ESPparty1Checksum m2 : 20|1@1+ (1,0) [0|1] "" Vector__XXX
 SG_ IBST_a138_ESPparty1Counter m2 : 21|1@1+ (1,0) [0|1] "" Vector__XXX
 SG_ IBST_a139_ESPparty2DLC m2 : 22|1@1+ (1,0) [0|1] "" Vector__XXX
 SG_ IBST_a140_ESPparty2Timeout m2 : 23|1@1+ (1,0) [0|1] "" Vector__XXX
 SG_ IBST_a141_ESPparty2Checksum m2 : 24|1@1+ (1,0) [0|1] "" Vector__XXX
 SG_ IBST_a142_ESPparty2Counter m2 : 25|1@1+ (1,0) [0|1] "" Vector__XXX
 SG_ IBST_a143_ESPparty3DLC m2 : 26|1@1+ (1,0) [0|1] "" Vector__XXX
 SG_ IBST_a144_ESPparty3Timeout m2 : 27|1@1+ (1,0) [0|1] "" Vector__XXX
 SG_ IBST_a145_ESPparty3Checksum m2 : 28|1@1+ (1,0) [0|1] "" Vector__XXX
 SG_ IBST_a146_ESPparty3Counter m2 : 29|1@1+ (1,0) [0|1] "" Vector__XXX
 SG_ IBST_a147_PSCMotorSizeReadFault m2 : 30|1@1+ (1,0) [0|1] "" Vector__XXX
 SG_ IBST_a148_MLIGainMechReadFault m2 : 31|1@1+ (1,0) [0|1] "" Vector__XXX
 SG_ IBST_a149_MLITMCAreaReadFault m2 : 32|1@1+ (1,0) [0|1] "" Vector__XXX
 SG_ IBST_a150_motorTestFault m2 : 33|1@1+ (1,0) [0|1] "" Vector__XXX
 SG_ IBST_a151_PSCGearRatioReadFault m2 : 34|1@1+ (1,0) [0|1] "" Vector__XXX
 SG_ IBST_a152_PSCVoltageImplausible m2 : 35|1@1+ (1,0) [0|1] "" Vector__XXX
 SG_ IBST_a153_unused m2 : 36|1@1+ (1,0) [0|1] "" Vector__XXX
 SG_ IBST_a154_unused m2 : 37|1@1+ (1,0) [0|1] "" Vector__XXX
 SG_ IBST_a155_supplyUndervoltageLvl1 m2 : 38|1@1+ (1,0) [0|1] "" Vector__XXX
 SG_ IBST_a156_supplyOvervoltageLvl1 m2 : 39|1@1+ (1,0) [0|1] "" Vector__XXX
 SG_ IBST_a157_masterCylPressInvalid m2 : 40|1@1+ (1,0) [0|1] "" Vector__XXX
 SG_ IBST_a158_DTSOffsHighSuspicious m2 : 41|1@1+ (1,0) [0|1] "" Vector__XXX
 SG_ IBST_a159_FindIdleNvMReadError m2 : 42|1@1+ (1,0) [0|1] "" Vector__XXX
 SG_ IBST_a160_DTSIDTimeOut m2 : 43|1@1+ (1,0) [0|1] "" Vector__XXX
 SG_ IBST_a161_powerPackMismatch m2 : 44|1@1+ (1,0) [0|1] "" Vector__XXX
 SG_ IBST_a162_idlePosNotDetected m2 : 45|1@1+ (1,0) [0|1] "" Vector__XXX
 SG_ IBST_a163_ESPpEstMaxInvalid m2 : 46|1@1+ (1,0) [0|1] "" Vector__XXX
 SG_ IBST_a164_ESPVehicleSpeedInvalid m2 : 47|1@1+ (1,0) [0|1] "" Vector__XXX
 SG_ IBST_a165_ESPpForceBlendInvalid m2 : 48|1@1+ (1,0) [0|1] "" Vector__XXX
 SG_ IBST_a166_ESPpMcVirtualInvalid m2 : 49|1@1+ (1,0) [0|1] "" Vector__XXX
 SG_ IBST_a167_ESPqTargetExterInvalid m2 : 50|1@1+ (1,0) [0|1] "" Vector__XXX
 SG_ IBST_a168_CANOvervoltage m2 : 51|1@1+ (1,0) [0|1] "" Vector__XXX
 SG_ IBST_a169_CANUndervoltage m2 : 52|1@1+ (1,0) [0|1] "" Vector__XXX
 SG_ IBST_a170_LVPowerStateTimeout m2 : 53|1@1+ (1,0) [0|1] "" Vector__XXX
 SG_ IBST_a171_LVPowerStateChecksum m2 : 54|1@1+ (1,0) [0|1] "" Vector__XXX
 SG_ IBST_a172_LVPowerStateDLC m2 : 55|1@1+ (1,0) [0|1] "" Vector__XXX
 SG_ IBST_a173_LVPowerStateCounter m2 : 56|1@1+ (1,0) [0|1] "" Vector__XXX
 SG_ IBST_a174_LVOffStateInvalid m2 : 57|1@1+ (1,0) [0|1] "" Vector__XXX
 SG_ IBST_a175_LVGoingDownInvalid m2 : 58|1@1+ (1,0) [0|1] "" Vector__XXX
 SG_ IBST_a176_blockedPedalDetected m2 : 59|1@1+ (1,0) [0|1] "" Vector__XXX
 SG_ IBST_a177_EPBLsystemStatusMIA m2 : 60|1@1+ (1,0) [0|1] "" Vector__XXX
 SG_ IBST_a178_EPBRsystemStatusMIA m2 : 61|1@1+ (1,0) [0|1] "" Vector__XXX
 SG_ IBST_a179_VCLEFTepbmStatusMIA m2 : 62|1@1+ (1,0) [0|1] "" Vector__XXX
 SG_ IBST_a180_VCRIGHTepbmStatusMIA m2 : 63|1@1+ (1,0) [0|1] "" Vector__XXX
 SG_ IBST_a181_DIchassisControlDLC m3 : 4|1@1+ (1,0) [0|1] "" Vector__XXX
 SG_ IBST_a182_DIchassisControlTimeou m3 : 5|1@1+ (1,0) [0|1] "" Vector__XXX
 SG_ IBST_a183_DIchassisControlChecks m3 : 6|1@1+ (1,0) [0|1] "" Vector__XXX
 SG_ IBST_a184_DIchassisControlCounte m3 : 7|1@1+ (1,0) [0|1] "" Vector__XXX
 SG_ IBST_a185_rightBusOff m3 : 8|1@1+ (1,0) [0|1] "" Vector__XXX
 SG_ IBST_a186_rightBusPassive m3 : 9|1@1+ (1,0) [0|1] "" Vector__XXX
 SG_ IBST_a187_brakeBusOff m3 : 10|1@1+ (1,0) [0|1] "" Vector__XXX
 SG_ IBST_a188_brakeBusPassive m3 : 11|1@1+ (1,0) [0|1] "" Vector__XXX
 SG_ IBST_a189_rightVCLVPowerStateTim m3 : 12|1@1+ (1,0) [0|1] "" Vector__XXX
 SG_ IBST_a190_rightVCLVPowerStateDLC m3 : 13|1@1+ (1,0) [0|1] "" Vector__XXX
 SG_ IBST_a191_rightVCLVPowerStateChe m3 : 14|1@1+ (1,0) [0|1] "" Vector__XXX
 SG_ IBST_a192_rightVCLVPowerStateCou m3 : 15|1@1+ (1,0) [0|1] "" Vector__XXX
 SG_ IBST_a193_leftVCLVPowerStateTime m3 : 16|1@1+ (1,0) [0|1] "" Vector__XXX
 SG_ IBST_a194_leftVCLVPowerStateChec m3 : 17|1@1+ (1,0) [0|1] "" Vector__XXX
 SG_ IBST_a195_leftVCLVPowerStateDLC m3 : 18|1@1+ (1,0) [0|1] "" Vector__XXX
 SG_ IBST_a196_leftVCLVPowerStateCoun m3 : 19|1@1+ (1,0) [0|1] "" Vector__XXX
 SG_ IBST_a197_brakeLatencyReductionA m3 : 20|1@1+ (1,0) [0|1] "" Vector__XXX
 SG_ IBST_a198_aesActive m3 : 21|1@1+ (1,0) [0|1] "" Vector__XXX
 SG_ IBST_a199_undefinedAlertDetected m3 : 22|1@1+ (1,0) [0|1] "" Vector__XXX
 SG_ IBST_a200_aesFault m3 : 23|1@1+ (1,0) [0|1] "" Vector__XXX
 SG_ IBST_a201_EGGREAR1wheelSpeedsRea m3 : 24|1@1+ (1,0) [0|1] "" Vector__XXX
 SG_ IBST_a202_EGGREAR1wheelSpeedsRea m3 : 25|1@1+ (1,0) [0|1] "" Vector__XXX
 SG_ IBST_a203_EGGREAR1wheelSpeedsRea m3 : 26|1@1+ (1,0) [0|1] "" Vector__XXX
 SG_ IBST_a204_EGGREAR1wheelSpeedsRea m3 : 27|1@1+ (1,0) [0|1] "" Vector__XXX
 SG_ IBST_a205_EGGRIGHT1wheelSpeedsFr m3 : 28|1@1+ (1,0) [0|1] "" Vector__XXX
 SG_ IBST_a206_EGGRIGHT1wheelSpeedsFr m3 : 29|1@1+ (1,0) [0|1] "" Vector__XXX
 SG_ IBST_a207_EGGRIGHT1wheelSpeedsFr m3 : 30|1@1+ (1,0) [0|1] "" Vector__XXX
 SG_ IBST_a208_EGGRIGHT1wheelSpeedsFr m3 : 31|1@1+ (1,0) [0|1] "" Vector__XXX
 SG_ IBST_a209_reducedBrakePowerActiv m3 : 32|1@1+ (1,0) [0|1] "" Vector__XXX
 SG_ IBST_a210_reducedBrakePowerNotAv m3 : 33|1@1+ (1,0) [0|1] "" Vector__XXX
 SG_ IBST_a211_DETReportError m3 : 34|1@1+ (1,0) [0|1] "" Vector__XXX
 SG_ IBST_a212_infoFailureWrongCUBASH m3 : 35|1@1+ (1,0) [0|1] "" Vector__XXX
 SG_ IBST_a213_PDURouterinitializatio m3 : 36|1@1+ (1,0) [0|1] "" Vector__XXX
 SG_ IBST_a214_LossOfPDUInstanceDetec m3 : 37|1@1+ (1,0) [0|1] "" Vector__XXX
 SG_ IBST_a215_UnsupportedSeriesHWDet m3 : 38|1@1+ (1,0) [0|1] "" Vector__XXX
 SG_ IBST_a216_AsicMalfunctionDetecte m3 : 39|1@1+ (1,0) [0|1] "" Vector__XXX
 SG_ IBST_a217_AsicTrimmingNotComplet m3 : 40|1@1+ (1,0) [0|1] "" Vector__XXX
 SG_ IBST_a218_uCSafetyNotificationGR m3 : 41|1@1+ (1,0) [0|1] "" Vector__XXX
 SG_ IBST_a219_uCSafetyNotification m3 : 42|1@1+ (1,0) [0|1] "" Vector__XXX
 SG_ IBST_a220_ASICOvercurrentOnGPIO2 m3 : 43|1@1+ (1,0) [0|1] "" Vector__XXX
 SG_ IBST_a221_ASICOvercurrentOnGPIO2 m3 : 44|1@1+ (1,0) [0|1] "" Vector__XXX
 SG_ IBST_a222_ASICOvercurrentOnGPIO5 m3 : 45|1@1+ (1,0) [0|1] "" Vector__XXX
 SG_ IBST_a223_ASICOvercurrentOnGPIO5 m3 : 46|1@1+ (1,0) [0|1] "" Vector__XXX
 SG_ IBST_a224_ASICOvercurrentOnGPIO5 m3 : 47|1@1+ (1,0) [0|1] "" Vector__XXX
 SG_ IBST_a225_ASICOvercurrentOnGPIO5 m3 : 48|1@1+ (1,0) [0|1] "" Vector__XXX
 SG_ IBST_a226_ASICOvercurrentOnWRHS m3 : 49|1@1+ (1,0) [0|1] "" Vector__XXX
 SG_ IBST_a227_wakeRequestMismatchDet m3 : 50|1@1+ (1,0) [0|1] "" Vector__XXX
 SG_ IBST_a228_BlockedPedalDetectedDu m3 : 51|1@1+ (1,0) [0|1] "" Vector__XXX
 SG_ IBST_a229_BlockedPedalDetected m3 : 52|1@1+ (1,0) [0|1] "" Vector__XXX
 SG_ IBST_a230_DTS2FunctionalRangeLow m3 : 53|1@1+ (1,0) [0|1] "" Vector__XXX
 SG_ IBST_a231_DTS2FunctionalRangeLow m3 : 54|1@1+ (1,0) [0|1] "" Vector__XXX
 SG_ IBST_a232_PostAssemblyRoutineFai m3 : 55|1@1+ (1,0) [0|1] "" Vector__XXX
 SG_ IBST_a233_ReferenceRunAbortByECU m3 : 56|1@1+ (1,0) [0|1] "" Vector__XXX
 SG_ IBST_a234_LiPSOutOfRangeHigh m3 : 57|1@1+ (1,0) [0|1] "" Vector__XXX
 SG_ IBST_a235_LiPSOutOfRangeLow m3 : 58|1@1+ (1,0) [0|1] "" Vector__XXX
 SG_ IBST_a246_DASredundantBrakingCon m4 : 9|1@1+ (1,0) [0|1] "" Vector__XXX
 SG_ IBST_a247_DASredundantBrakingCon m4 : 10|1@1+ (1,0) [0|1] "" Vector__XXX
 SG_ IBST_a248_DASredundantBrakingCon m4 : 11|1@1+ (1,0) [0|1] "" Vector__XXX
 SG_ IBST_a249_DASredundantBrakingCon m4 : 12|1@1+ (1,0) [0|1] "" Vector__XXX
 SG_ IBST_a250_DASredundantBrakingCon m4 : 13|1@1+ (1,0) [0|1] "" Vector__XXX
 SG_ IBST_a251_DASredundantBrakingCon m4 : 14|1@1+ (1,0) [0|1] "" Vector__XXX
 SG_ IBST_a252_DASredundantBrakingCon m4 : 15|1@1+ (1,0) [0|1] "" Vector__XXX
 SG_ IBST_a253_DASredundantBrakingCon m4 : 16|1@1+ (1,0) [0|1] "" Vector__XXX
 SG_ IBST_a254_DIlocStatus2Checksum m4 : 17|1@1+ (1,0) [0|1] "" Vector__XXX
 SG_ IBST_a255_DIlocStatus2Counter m4 : 18|1@1+ (1,0) [0|1] "" Vector__XXX
 SG_ IBST_a256_DIlocStatus2DLC m4 : 19|1@1+ (1,0) [0|1] "" Vector__XXX
 SG_ IBST_a257_DIlocStatus2Timeout m4 : 20|1@1+ (1,0) [0|1] "" Vector__XXX
 SG_ IBST_a258_standaloneEBRActive m4 : 21|1@1+ (1,0) [0|1] "" Vector__XXX
 SG_ IBST_a259_EMCMain11Checksum m4 : 22|1@1+ (1,0) [0|1] "" Vector__XXX
 SG_ IBST_a260_EMCMain11Counter m4 : 23|1@1+ (1,0) [0|1] "" Vector__XXX
 SG_ IBST_a261_EMCMain11DLC m4 : 24|1@1+ (1,0) [0|1] "" Vector__XXX
 SG_ IBST_a262_EMCMain11Timeout m4 : 25|1@1+ (1,0) [0|1] "" Vector__XXX
 SG_ IBST_a263_EMCMain21Checksum m4 : 26|1@1+ (1,0) [0|1] "" Vector__XXX
 SG_ IBST_a264_EMCMain21Counter m4 : 27|1@1+ (1,0) [0|1] "" Vector__XXX
 SG_ IBST_a265_EMCMain21DLC m4 : 28|1@1+ (1,0) [0|1] "" Vector__XXX
 SG_ IBST_a266_EMCMain21Timeout m4 : 29|1@1+ (1,0) [0|1] "" Vector__XXX

BO_ 813 IBST_info: 8 IBST
 SG_ IBST_infoIndex M : 0|8@1+ (1,0) [0|255] "" Vector__XXX
 SG_ IBST_infoBuildType m10 : 8|8@1+ (1,0) [0|255] "" Vector__XXX
 SG_ IBST_infoComponentID m10 : 55|16@0+ (1,0) [0|65535] "" Vector__XXX
 SG_ IBST_infoPcbaID m11 : 16|8@1+ (1,0) [0|255] "" Vector__XXX
 SG_ IBST_infoAssemblyID m11 : 24|8@1+ (1,0) [0|255] "" Vector__XXX
 SG_ IBST_infoUsageID m11 : 32|16@1+ (1,0) [0|65535] "" Vector__XXX
 SG_ IBST_infoSubUsageID m11 : 48|16@1+ (1,0) [0|65535] "" Vector__XXX
 SG_ IBST_infoApplicationCRC m13 : 32|32@1+ (1,0) [0|4294967295] "" Vector__XXX
 SG_ IBST_infoBootUdsProtoVersion m20 : 8|8@1+ (1,0) [0|255] "" Vector__XXX
 SG_ IBST_infoBootloaderCRC m20 : 32|32@1+ (1,0) [0|4294967295] "" Vector__XXX
 SG_ IBST_infoVariantCRC m22 : 32|32@1+ (1,0) [0|4294967295] "" Vector__XXX

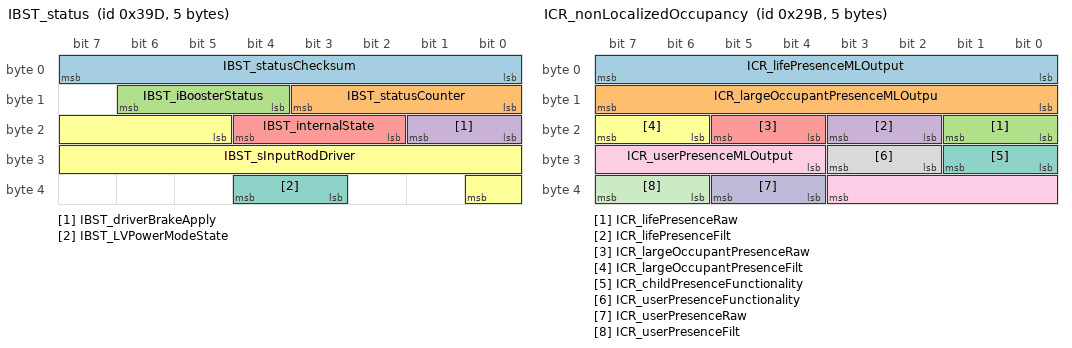
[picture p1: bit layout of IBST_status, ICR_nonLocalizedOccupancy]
BO_ 925 IBST_status: 5 IBST
 SG_ IBST_statusChecksum : 0|8@1+ (1,0) [0|255] "" Vector__XXX
 SG_ IBST_statusCounter : 8|4@1+ (1,0) [0|15] "" Vector__XXX
 SG_ IBST_iBoosterStatus : 12|3@1+ (1,0) [0|7] "" Vector__XXX
 SG_ IBST_driverBrakeApply : 16|2@1+ (1,0) [0|3] "" Vector__XXX
 SG_ IBST_internalState : 18|3@1+ (1,0) [0|7] "" Vector__XXX
 SG_ IBST_sInputRodDriver : 21|12@1+ (0.015625,-5) [-5|47] "mm" Vector__XXX
 SG_ IBST_LVPowerModeState : 35|2@1+ (1,0) [0|3] "" Vector__XXX

BO_ 1629 IBST_udsResponse: 8 IBST
 SG_ IBST_udsResponseData : 7|64@0+ (1,0) [0|1.84467440737e+19] "" Vector__XXX

BO_ 1208 ICR_alertLog: 8 ICR
 SG_ ICR_alertID M : 0|8@1+ (1,0) [0|255] "" Vector__XXX
 SG_ ICR_alertState : 15|1@1+ (1,0) [0|1] "" Vector__XXX
 SG_ ICR_a001_watchdogTaskAppDPM m1 : 16|1@1+ (1,0) [0|1] "" Vector__XXX
 SG_ ICR_a001_watchdogTaskMMWControl m1 : 17|1@1+ (1,0) [0|1] "" Vector__XXX
 SG_ ICR_a001_watchdogTaskSentinelInt m1 : 18|1@1+ (1,0) [0|1] "" Vector__XXX
 SG_ ICR_a001_watchdogTaskSentinelMod m1 : 19|1@1+ (1,0) [0|1] "" Vector__XXX
 SG_ ICR_a001_watchdogTaskComTXRAD m1 : 20|1@1+ (1,0) [0|1] "" Vector__XXX
 SG_ ICR_a001_watchdogTaskComRX m1 : 21|1@1+ (1,0) [0|1] "" Vector__XXX
 SG_ ICR_a001_watchdogTaskComTXVEH m1 : 22|1@1+ (1,0) [0|1] "" Vector__XXX
 SG_ ICR_a001_watchdogTaskComUDS m1 : 23|1@1+ (1,0) [0|1] "" Vector__XXX
 SG_ ICR_a001_watchdogTaskCommonError m1 : 24|1@1+ (1,0) [0|1] "" Vector__XXX
 SG_ ICR_a001_watchdogTaskUARTLog m1 : 25|1@1+ (1,0) [0|1] "" Vector__XXX
 SG_ ICR_a001_watchdogTaskDataDump m1 : 26|1@1+ (1,0) [0|1] "" Vector__XXX
 SG_ ICR_a001_watchdogRTOSAppRun10MS m1 : 27|1@1+ (1,0) [0|1] "" Vector__XXX
 SG_ ICR_a001_watchdogRTOSAppRun1MS m1 : 28|1@1+ (1,0) [0|1] "" Vector__XXX
 SG_ ICR_a001_InternalWatchdog m1 : 29|1@1+ (1,0) [0|1] "" Vector__XXX
 SG_ ICR_a015_NVMMMemOverflow m15 : 16|1@1+ (1,0) [0|1] "" Vector__XXX
 SG_ ICR_a015_NVMMFilesystemError m15 : 17|1@1+ (1,0) [0|1] "" Vector__XXX
 SG_ ICR_a015_NVMMRecordIDError m15 : 18|1@1+ (1,0) [0|1] "" Vector__XXX
 SG_ ICR_a059_voltageDrop m59 : 16|12@1+ (0.005443676,0) [0|22.29185322] "V" Vector__XXX
 SG_ ICR_a059_resistanceEstimate m59 : 28|12@1+ (0.00244,0) [0|9.9918] "Ohms" Vector__XXX
 SG_ ICR_a059_current m59 : 40|12@1+ (0.05,0) [0|204.75] "A" Vector__XXX
 SG_ ICR_a063_switchChannel m63 : 16|8@1+ (1,0) [0|255] "" Vector__XXX
 SG_ ICR_a063_switchType m63 : 24|8@1+ (1,0) [0|255] "" Vector__XXX
 SG_ ICR_a063_ADCVoltage m63 : 32|8@1+ (0.025,0) [0|6.375] "V" Vector__XXX
 SG_ ICR_a063_disconnected m63 : 40|1@1+ (1,0) [0|1] "" Vector__XXX
 SG_ ICR_a063_indeterminate m63 : 41|1@1+ (1,0) [0|1] "" Vector__XXX
 SG_ ICR_a063_stuckActive m63 : 42|1@1+ (1,0) [0|1] "" Vector__XXX
 SG_ ICR_a063_faulted m63 : 43|1@1+ (1,0) [0|1] "" Vector__XXX
 SG_ ICR_a133_nearClutter m133 : 16|8@1- (0.2,0) [-25.6|25.4] "dB" Vector__XXX
 SG_ ICR_a133_farClutter m133 : 24|8@1- (0.2,0) [-25.6|25.4] "dB" Vector__XXX
 SG_ ICR_a137_nearClutter m137 : 16|8@1- (0.2,0) [-25.6|25.4] "dB" Vector__XXX
 SG_ ICR_a137_farClutter m137 : 24|8@1- (0.2,0) [-25.6|25.4] "dB" Vector__XXX
 SG_ ICR_a139_nearClutter m139 : 16|8@1- (0.2,0) [-25.6|25.4] "dB" Vector__XXX
 SG_ ICR_a139_farClutter m139 : 24|8@1- (0.2,0) [-25.6|25.4] "dB" Vector__XXX
 SG_ ICR_a141_pmicQualityExcursion m141 : 16|1@1+ (1,0) [0|1] "" Vector__XXX
 SG_ ICR_a141_calDataNotCalibratedOrP m141 : 17|1@1+ (1,0) [0|1] "" Vector__XXX
 SG_ ICR_a141_calDataValRXPhaseAboveM m141 : 18|1@1+ (1,0) [0|1] "" Vector__XXX
 SG_ ICR_a141_calDataValRXPhaseMissin m141 : 19|1@1+ (1,0) [0|1] "" Vector__XXX
 SG_ ICR_a141_calDataValRangeBiasAbov m141 : 20|1@1+ (1,0) [0|1] "" Vector__XXX

BO_ 2028 ICR_alertMatrix: 8 ICR
 SG_ ICR_matrixIndex M : 0|4@1+ (1,0) [0|15] "" Vector__XXX
 SG_ ICR_a001_WatchdogReset m0 : 4|1@1+ (1,0) [0|1] "" Vector__XXX
 SG_ ICR_a002_PowerLossReset m0 : 5|1@1+ (1,0) [0|1] "" Vector__XXX
 SG_ ICR_a003_SWAssertion m0 : 6|1@1+ (1,0) [0|1] "" Vector__XXX
 SG_ ICR_a005_CANTXError m0 : 8|1@1+ (1,0) [0|1] "" Vector__XXX
 SG_ ICR_a006_CANTX_cyclicError m0 : 9|1@1+ (1,0) [0|1] "" Vector__XXX
 SG_ ICR_a012_CPUReset m0 : 15|1@1+ (1,0) [0|1] "" Vector__XXX
 SG_ ICR_a013_AlertManagerFault m0 : 16|1@1+ (1,0) [0|1] "" Vector__XXX
 SG_ ICR_a015_NVMMError m0 : 18|1@1+ (1,0) [0|1] "" Vector__XXX
 SG_ ICR_a016_NVMMRecordError m0 : 19|1@1+ (1,0) [0|1] "" Vector__XXX
 SG_ ICR_a021_TaskSchedulerError m0 : 24|1@1+ (1,0) [0|1] "" Vector__XXX
 SG_ ICR_a022_TaskInitError m0 : 25|1@1+ (1,0) [0|1] "" Vector__XXX
 SG_ ICR_a029_CoreDump m0 : 32|1@1+ (1,0) [0|1] "" Vector__XXX
 SG_ ICR_a030_ECULogUploadRequest m0 : 33|1@1+ (1,0) [0|1] "" Vector__XXX
 SG_ ICR_a031_UDSActive m0 : 34|1@1+ (1,0) [0|1] "" Vector__XXX
 SG_ ICR_a041_HighCPULoad m0 : 44|1@1+ (1,0) [0|1] "" Vector__XXX
 SG_ ICR_a042_HighStackUsage m0 : 45|1@1+ (1,0) [0|1] "" Vector__XXX
 SG_ ICR_a043_Task1msError m0 : 46|1@1+ (1,0) [0|1] "" Vector__XXX
 SG_ ICR_a044_Task10msError m0 : 47|1@1+ (1,0) [0|1] "" Vector__XXX
 SG_ ICR_a045_Task100msError m0 : 48|1@1+ (1,0) [0|1] "" Vector__XXX
 SG_ ICR_a046_Task1000msError m0 : 49|1@1+ (1,0) [0|1] "" Vector__XXX
 SG_ ICR_a058_inputRHighSyncDebug m0 : 61|1@1+ (1,0) [0|1] "" Vector__XXX
 SG_ ICR_a059_inputResistanceHigh m0 : 62|1@1+ (1,0) [0|1] "" Vector__XXX
 SG_ ICR_a060_engineeringBuild m0 : 63|1@1+ (1,0) [0|1] "" Vector__XXX
 SG_ ICR_a061_XCPConnected m1 : 4|1@1+ (1,0) [0|1] "" Vector__XXX
 SG_ ICR_a062_XCPWasConnected m1 : 5|1@1+ (1,0) [0|1] "" Vector__XXX
 SG_ ICR_a063_SwitchFault m1 : 6|1@1+ (1,0) [0|1] "" Vector__XXX
 SG_ ICR_a064_busSleepReqTimeout m1 : 7|1@1+ (1,0) [0|1] "" Vector__XXX
 SG_ ICR_a133_radarBlocked m2 : 16|1@1+ (1,0) [0|1] "" Vector__XXX
 SG_ ICR_a134_radarPgood m2 : 17|1@1+ (1,0) [0|1] "" Vector__XXX
 SG_ ICR_a135_radarTxBallBreak m2 : 18|1@1+ (1,0) [0|1] "" Vector__XXX
 SG_ ICR_a136_radarHighTemperature m2 : 19|1@1+ (1,0) [0|1] "" Vector__XXX
 SG_ ICR_a137_radarBlocked m2 : 20|1@1+ (1,0) [0|1] "" Vector__XXX
 SG_ ICR_a138_DriverSideMismatch m2 : 21|1@1+ (1,0) [0|1] "" Vector__XXX
 SG_ ICR_a139_AbnormalBlockageDetecte m2 : 22|1@1+ (1,0) [0|1] "" Vector__XXX
 SG_ ICR_a140_OccupancyExceptionEncou m2 : 23|1@1+ (1,0) [0|1] "" Vector__XXX
 SG_ ICR_a141_RequiresReplacement m2 : 24|1@1+ (1,0) [0|1] "" Vector__XXX
 SG_ ICR_a142_ModeOverrideActive m2 : 25|1@1+ (1,0) [0|1] "" Vector__XXX
 SG_ ICR_a143_DSPCoreSkipped m2 : 26|1@1+ (1,0) [0|1] "" Vector__XXX
 SG_ ICR_a144_OccupancyNotificationAl m2 : 27|1@1+ (1,0) [0|1] "" Vector__XXX

BO_ 941 ICR_info: 8 ICR
 SG_ ICR_infoIndex M : 0|8@1+ (1,0) [0|255] "" Vector__XXX
 SG_ ICR_infoBuildType m10 : 8|3@1+ (1,0) [0|7] "" Vector__XXX
 SG_ ICR_infoPcbaId m11 : 32|8@1+ (1,0) [0|255] "" Vector__XXX
 SG_ ICR_infoAssemblyId m11 : 40|8@1+ (1,0) [0|255] "" Vector__XXX
 SG_ ICR_infoUsageId m11 : 48|16@1+ (1,0) [0|65535] "" Vector__XXX
 SG_ ICR_infoAppCrc m13 : 8|32@1+ (1,0) [0|4294967295] "" Vector__XXX
 SG_ ICR_infoBoardPartNumber17 m25 : 8|56@1+ (1,0) [0|7.20575940379e+16] "" Vector__XXX
 SG_ ICR_infoBoardPartNumber814 m26 : 8|56@1+ (1,0) [0|7.20575940379e+16] "" Vector__XXX
 SG_ ICR_infoBoardPartNumber1520 m27 : 8|48@1+ (1,0) [0|281474976710655] "" Vector__XXX

BO_ 667 ICR_nonLocalizedOccupancy: 5 ICR
 SG_ ICR_lifePresenceMLOutput : 0|8@1+ (0.004,0) [0|1.016] "points" Vector__XXX
 SG_ ICR_largeOccupantPresenceMLOutpu : 8|8@1+ (0.004,0) [0|1.016] "points" Vector__XXX
 SG_ ICR_lifePresenceRaw : 16|2@1+ (1,0) [1|3] "" Vector__XXX
 SG_ ICR_lifePresenceFilt : 18|2@1+ (1,0) [1|3] "" Vector__XXX
 SG_ ICR_largeOccupantPresenceRaw : 20|2@1+ (1,0) [0|2] "" Vector__XXX
 SG_ ICR_largeOccupantPresenceFilt : 22|2@1+ (1,0) [0|2] "" Vector__XXX
 SG_ ICR_childPresenceFunctionality : 24|2@1+ (1,0) [0|3] "" Vector__XXX
 SG_ ICR_userPresenceFunctionality : 26|2@1+ (1,0) [0|3] "" Vector__XXX
 SG_ ICR_userPresenceMLOutput : 28|8@1+ (0.004,0) [0|1.016] "points" Vector__XXX
 SG_ ICR_userPresenceRaw : 36|2@1+ (1,0) [0|2] "" Vector__XXX
 SG_ ICR_userPresenceFilt : 38|2@1+ (1,0) [0|2] "" Vector__XXX

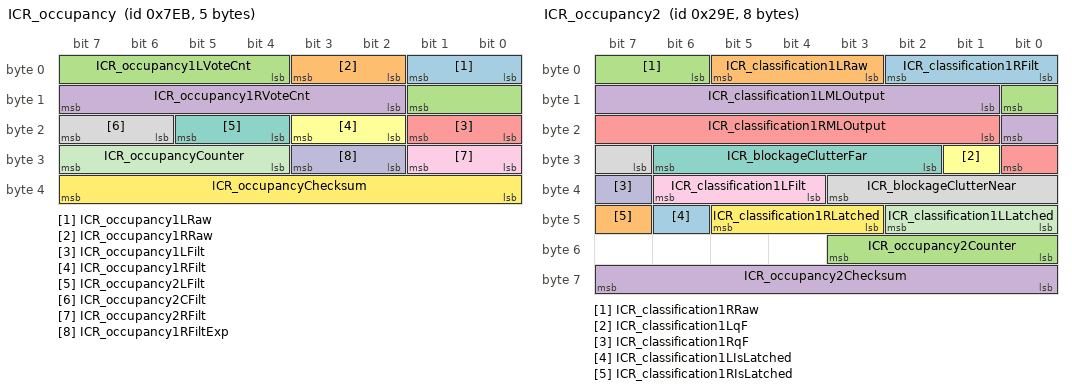
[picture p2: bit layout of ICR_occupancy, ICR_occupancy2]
BO_ 2027 ICR_occupancy: 5 ICR
 SG_ ICR_occupancy1LRaw : 0|2@1+ (1,0) [0|2] "" Vector__XXX
 SG_ ICR_occupancy1RRaw : 2|2@1+ (1,0) [0|2] "" Vector__XXX
 SG_ ICR_occupancy1LVoteCnt : 4|6@1- (1,0) [-32|31] "" Vector__XXX
 SG_ ICR_occupancy1RVoteCnt : 10|6@1- (1,0) [-32|31] "" Vector__XXX
 SG_ ICR_occupancy1LFilt : 16|2@1+ (1,0) [0|2] "" Vector__XXX
 SG_ ICR_occupancy1RFilt : 18|2@1+ (1,0) [0|2] "" Vector__XXX
 SG_ ICR_occupancy2LFilt : 20|2@1+ (1,0) [0|2] "" Vector__XXX
 SG_ ICR_occupancy2CFilt : 22|2@1+ (1,0) [0|2] "" Vector__XXX
 SG_ ICR_occupancy2RFilt : 24|2@1+ (1,0) [0|2] "" Vector__XXX
 SG_ ICR_occupancy1RFiltExp : 26|2@1+ (1,0) [0|2] "" Vector__XXX
 SG_ ICR_occupancyCounter : 28|4@1+ (1,0) [0|15] "" Vector__XXX
 SG_ ICR_occupancyChecksum : 32|8@1+ (1,0) [0|255] "" Vector__XXX

BO_ 670 ICR_occupancy2: 8 ICR
 SG_ ICR_classification1RFilt : 0|3@1+ (1,0) [1|7] "" Vector__XXX
 SG_ ICR_classification1LRaw : 3|3@1+ (1,0) [1|7] "" Vector__XXX
 SG_ ICR_classification1RRaw : 6|3@1+ (1,0) [1|7] "" Vector__XXX
 SG_ ICR_classification1LMLOutput : 9|8@1+ (0.004,0) [0|1.016] "points" Vector__XXX
 SG_ ICR_classification1RMLOutput : 17|8@1+ (0.004,0) [0|1.016] "points" Vector__XXX
 SG_ ICR_classification1LqF : 25|1@1+ (1,0) [0|1] "" Vector__XXX
 SG_ ICR_blockageClutterFar : 26|5@1- (0.5,-1.5) [-9|6] "dB" Vector__XXX
 SG_ ICR_blockageClutterNear : 31|5@1- (0.5,-1.5) [-9|6] "dB" Vector__XXX
 SG_ ICR_classification1LFilt : 36|3@1+ (1,0) [1|7] "" Vector__XXX
 SG_ ICR_classification1RqF : 39|1@1+ (1,0) [0|1] "" Vector__XXX
 SG_ ICR_classification1LLatched : 40|3@1+ (1,0) [1|7] "" Vector__XXX
 SG_ ICR_classification1RLatched : 43|3@1+ (1,0) [1|7] "" Vector__XXX
 SG_ ICR_classification1LIsLatched : 46|1@1+ (1,0) [0|1] "" Vector__XXX
 SG_ ICR_classification1RIsLatched : 47|1@1+ (1,0) [0|1] "" Vector__XXX
 SG_ ICR_occupancy2Counter : 48|4@1+ (1,0) [0|15] "" Vector__XXX
 SG_ ICR_occupancy2Checksum : 56|8@1+ (1,0) [0|255] "" Vector__XXX

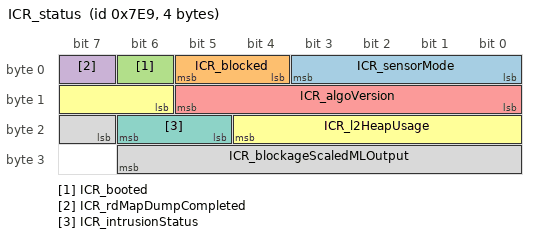
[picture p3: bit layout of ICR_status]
BO_ 2025 ICR_status: 4 ICR
 SG_ ICR_sensorMode : 0|4@1+ (1,0) [0|15] "" Vector__XXX
 SG_ ICR_blocked : 4|2@1+ (1,0) [1|3] "" Vector__XXX
 SG_ ICR_booted : 6|1@1+ (1,0) [0|1] "" Vector__XXX
 SG_ ICR_rdMapDumpCompleted : 7|1@1+ (1,0) [0|1] "" Vector__XXX
 SG_ ICR_algoVersion : 8|6@1+ (1,0) [0|63] "" Vector__XXX
 SG_ ICR_l2HeapUsage : 14|7@1+ (1,0) [0|127] "PCT" Vector__XXX
 SG_ ICR_intrusionStatus : 21|2@1+ (1,0) [0|3] "" Vector__XXX
 SG_ ICR_blockageScaledMLOutput : 23|8@1+ (0.004,0) [0|1.02] "points" Vector__XXX

BO_ 1624 ICR_udsResponse: 8 ICR
 SG_ ICR_udsResponseData : 7|64@0+ (1,0) [0|1.84467440737e+19] "" Vector__XXX

BO_TX_BU_ 1290 : HVP;
BO_TX_BU_ 938 : HVP;
BO_TX_BU_ 522 : HVP;
BO_TX_BU_ 1962 : HVP;
BO_TX_BU_ 1666 : HVP;
BO_TX_BU_ 554 : HVP;
BO_TX_BU_ 2029 : HVP;
BO_TX_BU_ 1914 : HVP;
BO_TX_BU_ 1553 : HVP;
BO_TX_BU_ 861 : IBST;
BO_TX_BU_ 813 : IBST;
BO_TX_BU_ 925 : IBST;
BO_TX_BU_ 1629 : IBST;
BO_TX_BU_ 1208 : ICR;
BO_TX_BU_ 2028 : ICR;
BO_TX_BU_ 941 : ICR;
BO_TX_BU_ 667 : ICR;
BO_TX_BU_ 2027 : ICR;
BO_TX_BU_ 670 : ICR;
BO_TX_BU_ 2025 : ICR;
BO_TX_BU_ 1624 : ICR;
CM_ BO_ 1290 "High-voltage processor (pack contactor and isolation controller) message: alert log";
CM_ SG_ 1290 HVP_alertID "High-voltage processor (pack contactor and isolation controller): alert ID";
CM_ SG_ 1290 HVP_alertSet "High-voltage processor (pack contactor and isolation controller): alert set";
CM_ SG_ 1290 HVP_a005_current "High-voltage processor (pack contactor and isolation controller): a005 current";
CM_ SG_ 1290 HVP_a006_current "High-voltage processor (pack contactor and isolation controller): a006 current";
CM_ SG_ 1290 HVP_a007_current "High-voltage processor (pack contactor and isolation controller): a007 current";
CM_ SG_ 1290 HVP_a008_temperature "High-voltage processor (pack contactor and isolation controller): a008 temperature";
CM_ SG_ 1290 HVP_a008_sensorId "High-voltage processor (pack contactor and isolation controller): a008 sensor id";
CM_ SG_ 1290 HVP_a008_primaryChainSensor "High-voltage processor (pack contactor and isolation controller): a008 primary chain sensor";
CM_ SG_ 1290 HVP_a009_brickVoltage "High-voltage processor (pack contactor and isolation controller): a009 brick voltage";
CM_ SG_ 1290 HVP_a009_brickId "High-voltage processor (pack contactor and isolation controller): a009 brick id";
CM_ SG_ 1290 HVP_a009_primaryChainSensor "High-voltage processor (pack contactor and isolation controller): a009 primary chain sensor";
CM_ SG_ 1290 HVP_a010_brickVoltage "High-voltage processor (pack contactor and isolation controller): a010 brick voltage";
CM_ SG_ 1290 HVP_a010_brickId "High-voltage processor (pack contactor and isolation controller): a010 brick id";
CM_ SG_ 1290 HVP_a010_primaryChainSensor "High-voltage processor (pack contactor and isolation controller): a010 primary chain sensor";
CM_ SG_ 1290 HVP_a012_breakLocationA "High-voltage processor (pack contactor and isolation controller): a012 break location a";
CM_ SG_ 1290 HVP_a012_bmbCommStatusTypeA "High-voltage processor (pack contactor and isolation controller): a012 bmb comm status type a";
CM_ SG_ 1290 HVP_a012_breakLocationB "High-voltage processor (pack contactor and isolation controller): a012 break location b";
CM_ SG_ 1290 HVP_a012_bmbCommStatusTypeB "High-voltage processor (pack contactor and isolation controller): a012 bmb comm status type b";
CM_ SG_ 1290 HVP_a013_breakLocationA "High-voltage processor (pack contactor and isolation controller): a013 break location a";
CM_ SG_ 1290 HVP_a013_bmbCommStatusTypeA "High-voltage processor (pack contactor and isolation controller): a013 bmb comm status type a";
CM_ SG_ 1290 HVP_a013_breakLocationB "High-voltage processor (pack contactor and isolation controller): a013 break location b";
CM_ SG_ 1290 HVP_a013_bmbCommStatusTypeB "High-voltage processor (pack contactor and isolation controller): a013 bmb comm status type b";
CM_ SG_ 1290 HVP_a013_bmbChainBreakType "High-voltage processor (pack contactor and isolation controller): a013 bmb chain break type";
CM_ SG_ 1290 HVP_a018_dcLinkVoltage "High-voltage processor (pack contactor and isolation controller): a018 dc link voltage";
CM_ SG_ 1290 HVP_a018_battery12V "High-voltage processor (pack contactor and isolation controller): a018 battery12 v";
CM_ SG_ 1290 HVP_a018_remainingPcsPowerCycles "High-voltage processor (pack contactor and isolation controller): a018 remaining pcs power cycles allowed";
CM_ SG_ 1290 HVP_a018_remainingPcsRecoveriesA "High-voltage processor (pack contactor and isolation controller): a018 remaining pcs recoveries allowed";
CM_ SG_ 1290 HVP_a018_hvcHardwareSupportsCycl "High-voltage processor (pack contactor and isolation controller): a018 hvc hardware supports cycling";
CM_ SG_ 1290 HVP_a018_pcsHardwareOkToBePowerC "High-voltage processor (pack contactor and isolation controller): a018 pcs hardware ok to be power cycled";
CM_ SG_ 1290 HVP_a018_gpioLogicPowerEnable "High-voltage processor (pack contactor and isolation controller): a018 gpio logic power enable";
CM_ SG_ 1290 HVP_a018_gpioDcDcEnable "High-voltage processor (pack contactor and isolation controller): a018 gpio dc dc enable";
CM_ SG_ 1290 HVP_a018_gpioChgEnable "High-voltage processor (pack contactor and isolation controller): a018 gpio chg enable";
CM_ SG_ 1290 HVP_a020_energyReserveV "High-voltage processor (pack contactor and isolation controller): a020 energy reserve v; raw 65535 = signal not available (SNA)";
CM_ SG_ 1290 HVP_a020_shuntCurrentAux "High-voltage processor (pack contactor and isolation controller): a020 shunt current aux; raw 32768 = signal not available (SNA)";
CM_ SG_ 1290 HVP_a020_shuntTemperature "High-voltage processor (pack contactor and isolation controller): a020 shunt temperature; raw 32768 = signal not available (SNA)";
CM_ SG_ 1290 HVP_a021_pyroStatus "High-voltage processor (pack contactor and isolation controller): a021 pyro status";
CM_ SG_ 1290 HVP_a021_ErTestFailed "High-voltage processor (pack contactor and isolation controller): a021 er test failed";
CM_ SG_ 1290 HVP_a021_HighSideSwitchTestFaile "High-voltage processor (pack contactor and isolation controller): a021 high side switch test failed";
CM_ SG_ 1290 HVP_a021_LowSideSwitchTestFailed "High-voltage processor (pack contactor and isolation controller): a021 low side switch test failed";
CM_ SG_ 1290 HVP_a021_RefCurrentTestFailed "High-voltage processor (pack contactor and isolation controller): a021 ref current test failed";
CM_ SG_ 1290 HVP_a021_PyroLeakTestFailed "High-voltage processor (pack contactor and isolation controller): a021 pyro leak test failed";
CM_ SG_ 1290 HVP_a021_SquibResTestFailed "High-voltage processor (pack contactor and isolation controller): a021 squib res test failed";
CM_ SG_ 1290 HVP_a021_VstTestFailed "High-voltage processor (pack contactor and isolation controller): a021 vst test failed";
CM_ SG_ 1290 HVP_a021_SquibResistance "High-voltage processor (pack contactor and isolation controller): a021 squib resistance; raw 65535 = signal not available (SNA)";
CM_ SG_ 1290 HVP_a021_OneShotSequence "High-voltage processor (pack contactor and isolation controller): a021 one shot sequence";
CM_ SG_ 1290 HVP_a021_HighSide "High-voltage processor (pack contactor and isolation controller): a021 high side";
CM_ SG_ 1290 HVP_a021_LowSide "High-voltage processor (pack contactor and isolation controller): a021 low side";
CM_ SG_ 1290 HVP_a021_Aout "High-voltage processor (pack contactor and isolation controller): a021 aout; raw 16383 = signal not available (SNA)";
CM_ SG_ 1290 HVP_a022_pyroStatus "High-voltage processor (pack contactor and isolation controller): a022 pyro status";
CM_ SG_ 1290 HVP_a022_PyroLeakTestFailed "High-voltage processor (pack contactor and isolation controller): a022 pyro leak test failed";
CM_ SG_ 1290 HVP_a022_OneShotSequence "High-voltage processor (pack contactor and isolation controller): a022 one shot sequence";
CM_ SG_ 1290 HVP_a022_HighSide "High-voltage processor (pack contactor and isolation controller): a022 high side";
CM_ SG_ 1290 HVP_a022_LowSide "High-voltage processor (pack contactor and isolation controller): a022 low side";
CM_ SG_ 1290 HVP_a022_Aout "High-voltage processor (pack contactor and isolation controller): a022 aout; raw 16383 = signal not available (SNA)";
CM_ SG_ 1290 HVP_a022_SquibResistance "High-voltage processor (pack contactor and isolation controller): a022 squib resistance; raw 65535 = signal not available (SNA)";
CM_ SG_ 1290 HVP_a024_voltage "High-voltage processor (pack contactor and isolation controller): a024 voltage";
CM_ SG_ 1290 HVP_a025_voltage1 "High-voltage processor (pack contactor and isolation controller): a025 voltage1";
CM_ SG_ 1290 HVP_a025_voltage2 "High-voltage processor (pack contactor and isolation controller): a025 voltage2";
CM_ SG_ 1290 HVP_a025_packVoltage "High-voltage processor (pack contactor and isolation controller): a025 pack voltage";
CM_ SG_ 1290 HVP_a026_hvilStatus "High-voltage processor (pack contactor and isolation controller): a026 hvil status; raw 14 = signal not available (SNA)";
CM_ SG_ 1290 HVP_a026_inputVoltage "High-voltage processor (pack contactor and isolation controller): a026 input voltage";
CM_ SG_ 1290 HVP_a026_outputVoltage "High-voltage processor (pack contactor and isolation controller): a026 output voltage";
CM_ SG_ 1290 HVP_a026_internalVoltage "High-voltage processor (pack contactor and isolation controller): a026 internal voltage; raw 255 = signal not available (SNA)";
CM_ SG_ 1290 HVP_a026_dirVoltage "High-voltage processor (pack contactor and isolation controller): a026 dir voltage; raw 255 = signal not available (SNA)";
CM_ SG_ 1290 HVP_a026_difVoltage "High-voltage processor (pack contactor and isolation controller): a026 dif voltage; raw 255 = signal not available (SNA)";
CM_ SG_ 1290 HVP_a028_packVoltage "High-voltage processor (pack contactor and isolation controller): a028 pack voltage";
CM_ SG_ 1290 HVP_a028_sumOfBrickV "High-voltage processor (pack contactor and isolation controller): a028 sum of brick v";
CM_ SG_ 1290 HVP_a030_packPositiveLinkV "High-voltage processor (pack contactor and isolation controller): a030 pack positive link v";
CM_ SG_ 1290 HVP_a030_dcPositiveLinkV "High-voltage processor (pack contactor and isolation controller): a030 dc positive link v";
CM_ SG_ 1290 HVP_a031_packNegativeLinkV "High-voltage processor (pack contactor and isolation controller): a031 pack negative link v";
CM_ SG_ 1290 HVP_a031_dcNegativeLinkV "High-voltage processor (pack contactor and isolation controller): a031 dc negative link v";
CM_ SG_ 1290 HVP_a033_contactorPowerV "High-voltage processor (pack contactor and isolation controller): a033 contactor power v";
CM_ SG_ 1290 HVP_a033_coilCurrent "High-voltage processor (pack contactor and isolation controller): a033 coil current";
CM_ SG_ 1290 HVP_a033_pwmDutyCylePositive "High-voltage processor (pack contactor and isolation controller): a033 pwm duty cyle positive";
CM_ SG_ 1290 HVP_a033_pwmDutyCyleNegative "High-voltage processor (pack contactor and isolation controller): a033 pwm duty cyle negative";
CM_ SG_ 1290 HVP_a035_contactorPowerV "High-voltage processor (pack contactor and isolation controller): a035 contactor power v";
CM_ SG_ 1290 HVP_a035_coilCurrent "High-voltage processor (pack contactor and isolation controller): a035 coil current";
CM_ SG_ 1290 HVP_a035_pwmDutyCylePositive "High-voltage processor (pack contactor and isolation controller): a035 pwm duty cyle positive";
CM_ SG_ 1290 HVP_a035_pwmDutyCyleNegative "High-voltage processor (pack contactor and isolation controller): a035 pwm duty cyle negative";
CM_ SG_ 1290 HVP_a036_pyroFiringHandle "High-voltage processor (pack contactor and isolation controller): a036 pyro firing handle";
CM_ SG_ 1290 HVP_a036_pyroFiringTime "High-voltage processor (pack contactor and isolation controller): a036 pyro firing time";
CM_ SG_ 1290 HVP_a036_pyroFiringAttempt "High-voltage processor (pack contactor and isolation controller): a036 pyro firing attempt";
CM_ SG_ 1290 HVP_a037_pyroFiringHandle "High-voltage processor (pack contactor and isolation controller): a037 pyro firing handle";
CM_ SG_ 1290 HVP_a039_posContactorFailed "High-voltage processor (pack contactor and isolation controller): a039 pos contactor failed";
CM_ SG_ 1290 HVP_a039_negContactorFailed "High-voltage processor (pack contactor and isolation controller): a039 neg contactor failed";
CM_ SG_ 1290 HVP_a040_powerVoltage "High-voltage processor (pack contactor and isolation controller): a040 power voltage";
CM_ SG_ 1290 HVP_a040_coilCurrent "High-voltage processor (pack contactor and isolation controller): a040 coil current";
CM_ SG_ 1290 HVP_a040_posCtrVoltageDrop "High-voltage processor (pack contactor and isolation controller): a040 pos ctr voltage drop";
CM_ SG_ 1290 HVP_a040_negCtrVoltageDrop "High-voltage processor (pack contactor and isolation controller): a040 neg ctr voltage drop";
CM_ SG_ 1290 HVP_a040_posCtrAuxOpen "High-voltage processor (pack contactor and isolation controller): a040 pos ctr aux open";
CM_ SG_ 1290 HVP_a040_negCtrAuxOpen "High-voltage processor (pack contactor and isolation controller): a040 neg ctr aux open";
CM_ SG_ 1290 HVP_a041_overCurrent "High-voltage processor (pack contactor and isolation controller): a041 over current";
CM_ SG_ 1290 HVP_a041_overChargeCurrent "High-voltage processor (pack contactor and isolation controller): a041 over charge current";
CM_ SG_ 1290 HVP_a041_overDischargeCurrent "High-voltage processor (pack contactor and isolation controller): a041 over discharge current";
CM_ SG_ 1290 HVP_a041_overVoltage "High-voltage processor (pack contactor and isolation controller): a041 over voltage";
CM_ SG_ 1290 HVP_a041_overTemperature "High-voltage processor (pack contactor and isolation controller): a041 over temperature";
CM_ SG_ 1290 HVP_a041_underVoltage "High-voltage processor (pack contactor and isolation controller): a041 under voltage";
CM_ SG_ 1290 HVP_a041_crashEvent "High-voltage processor (pack contactor and isolation controller): a041 crash event";
CM_ SG_ 1290 HVP_a041_packContactorHw "High-voltage processor (pack contactor and isolation controller): a041 pack contactor hw";
CM_ SG_ 1290 HVP_a041_notAllowedtoEnergize "High-voltage processor (pack contactor and isolation controller): a041 not allowedto energize";
CM_ SG_ 1290 HVP_a041_bmbMia "High-voltage processor (pack contactor and isolation controller): a041 bmb mia";
CM_ SG_ 1290 HVP_a041_hvilFault "High-voltage processor (pack contactor and isolation controller): a041 hvil fault";
CM_ SG_ 1290 HVP_a041_contactorStateWelded "High-voltage processor (pack contactor and isolation controller): a041 contactor state welded";
CM_ SG_ 1290 HVP_a041_shuntHwMia "High-voltage processor (pack contactor and isolation controller): a041 shunt hw mia";
CM_ SG_ 1290 HVP_a041_shuntCurrentMia "High-voltage processor (pack contactor and isolation controller): a041 shunt current mia";
CM_ SG_ 1290 HVP_a041_packVoltageMismatch "High-voltage processor (pack contactor and isolation controller): a041 pack voltage mismatch";
CM_ SG_ 1290 HVP_a041_gpoRequestActive "High-voltage processor (pack contactor and isolation controller): a041 gpo request active";
CM_ SG_ 1290 HVP_a041_fcContactorClosing "High-voltage processor (pack contactor and isolation controller): a041 fc contactor closing";
CM_ SG_ 1290 HVP_a041_fcContactorOpening "High-voltage processor (pack contactor and isolation controller): a041 fc contactor opening";
CM_ SG_ 1290 HVP_a041_resetRequestRequired "High-voltage processor (pack contactor and isolation controller): a041 reset request required";
CM_ SG_ 1290 HVP_a041_pyroFault "High-voltage processor (pack contactor and isolation controller): a041 pyro fault";
CM_ SG_ 1290 HVP_a041_dcLinkOverVoltage "High-voltage processor (pack contactor and isolation controller): a041 dc link over voltage";
CM_ SG_ 1290 HVP_a042_overCurrent "High-voltage processor (pack contactor and isolation controller): a042 over current";
CM_ SG_ 1290 HVP_a042_overChargeCurrent "High-voltage processor (pack contactor and isolation controller): a042 over charge current";
CM_ SG_ 1290 HVP_a042_overDischargeCurrent "High-voltage processor (pack contactor and isolation controller): a042 over discharge current";
CM_ SG_ 1290 HVP_a042_overVoltage "High-voltage processor (pack contactor and isolation controller): a042 over voltage";
CM_ SG_ 1290 HVP_a042_overTemperature "High-voltage processor (pack contactor and isolation controller): a042 over temperature";
CM_ SG_ 1290 HVP_a042_crashEvent "High-voltage processor (pack contactor and isolation controller): a042 crash event";
CM_ SG_ 1290 HVP_a042_fcContactorHw "High-voltage processor (pack contactor and isolation controller): a042 fc contactor hw";
CM_ SG_ 1290 HVP_a042_notAllowedtoEnergize "High-voltage processor (pack contactor and isolation controller): a042 not allowedto energize";
CM_ SG_ 1290 HVP_a042_bmsHvsMia "High-voltage processor (pack contactor and isolation controller): a042 bms hvs mia";
CM_ SG_ 1290 HVP_a042_cpMia "High-voltage processor (pack contactor and isolation controller): a042 cp mia";
CM_ SG_ 1290 HVP_a042_cpFault "High-voltage processor (pack contactor and isolation controller): a042 cp fault";
CM_ SG_ 1290 HVP_a042_supply12V "High-voltage processor (pack contactor and isolation controller): a042 supply12 v";
CM_ SG_ 1290 HVP_a042_supplyVer "High-voltage processor (pack contactor and isolation controller): a042 supply ver";
CM_ SG_ 1290 HVP_a042_packVoltageMismatch "High-voltage processor (pack contactor and isolation controller): a042 pack voltage mismatch";
CM_ SG_ 1290 HVP_a042_hvilFault "High-voltage processor (pack contactor and isolation controller): a042 hvil fault";
CM_ SG_ 1290 HVP_a042_contactorStateWelded "High-voltage processor (pack contactor and isolation controller): a042 contactor state welded";
CM_ SG_ 1290 HVP_a042_shuntHwMia "High-voltage processor (pack contactor and isolation controller): a042 shunt hw mia";
CM_ SG_ 1290 HVP_a042_shuntCurrentMia "High-voltage processor (pack contactor and isolation controller): a042 shunt current mia";
CM_ SG_ 1290 HVP_a042_packContactorClosing "High-voltage processor (pack contactor and isolation controller): a042 pack contactor closing";
CM_ SG_ 1290 HVP_a042_packContactorOpening "High-voltage processor (pack contactor and isolation controller): a042 pack contactor opening";
CM_ SG_ 1290 HVP_a042_resetRequestRequired "High-voltage processor (pack contactor and isolation controller): a042 reset request required";
CM_ SG_ 1290 HVP_a042_cpVersionMismatch "High-voltage processor (pack contactor and isolation controller): a042 cp version mismatch";
CM_ SG_ 1290 HVP_a043_overCurrent "High-voltage processor (pack contactor and isolation controller): a043 over current";
CM_ SG_ 1290 HVP_a043_overChargeCurrent "High-voltage processor (pack contactor and isolation controller): a043 over charge current";
CM_ SG_ 1290 HVP_a043_overDischargeCurrent "High-voltage processor (pack contactor and isolation controller): a043 over discharge current";
CM_ SG_ 1290 HVP_a043_overVoltage "High-voltage processor (pack contactor and isolation controller): a043 over voltage";
CM_ SG_ 1290 HVP_a043_overTemperature "High-voltage processor (pack contactor and isolation controller): a043 over temperature";
CM_ SG_ 1290 HVP_a043_underVoltage "High-voltage processor (pack contactor and isolation controller): a043 under voltage";
CM_ SG_ 1290 HVP_a043_crashEvent "High-voltage processor (pack contactor and isolation controller): a043 crash event";
CM_ SG_ 1290 HVP_a043_packContactorHw "High-voltage processor (pack contactor and isolation controller): a043 pack contactor hw";
CM_ SG_ 1290 HVP_a043_notAllowedtoEnergize "High-voltage processor (pack contactor and isolation controller): a043 not allowedto energize";
CM_ SG_ 1290 HVP_a043_bmbMia "High-voltage processor (pack contactor and isolation controller): a043 bmb mia";
CM_ SG_ 1290 HVP_a043_contactorOpened "High-voltage processor (pack contactor and isolation controller): a043 contactor opened";
CM_ SG_ 1290 HVP_a044_overCurrent "High-voltage processor (pack contactor and isolation controller): a044 over current";
CM_ SG_ 1290 HVP_a044_overChargeCurrent "High-voltage processor (pack contactor and isolation controller): a044 over charge current";
CM_ SG_ 1290 HVP_a044_overDischargeCurrent "High-voltage processor (pack contactor and isolation controller): a044 over discharge current";
CM_ SG_ 1290 HVP_a044_overVoltage "High-voltage processor (pack contactor and isolation controller): a044 over voltage";
CM_ SG_ 1290 HVP_a044_overTemperature "High-voltage processor (pack contactor and isolation controller): a044 over temperature";
CM_ SG_ 1290 HVP_a044_crashEvent "High-voltage processor (pack contactor and isolation controller): a044 crash event";
CM_ SG_ 1290 HVP_a044_fcContactorHw "High-voltage processor (pack contactor and isolation controller): a044 fc contactor hw";
CM_ SG_ 1290 HVP_a044_notAllowedtoEnergize "High-voltage processor (pack contactor and isolation controller): a044 not allowedto energize";
CM_ SG_ 1290 HVP_a044_bmsHvsMia "High-voltage processor (pack contactor and isolation controller): a044 bms hvs mia";
CM_ SG_ 1290 HVP_a044_cpMia "High-voltage processor (pack contactor and isolation controller): a044 cp mia";
CM_ SG_ 1290 HVP_a044_cpFault "High-voltage processor (pack contactor and isolation controller): a044 cp fault";
CM_ SG_ 1290 HVP_a044_supply12V "High-voltage processor (pack contactor and isolation controller): a044 supply12 v";
CM_ SG_ 1290 HVP_a044_supplyVer "High-voltage processor (pack contactor and isolation controller): a044 supply ver";
CM_ SG_ 1290 HVP_a044_packVoltageMismatch "High-voltage processor (pack contactor and isolation controller): a044 pack voltage mismatch";
CM_ SG_ 1290 HVP_a044_contactorOpened "High-voltage processor (pack contactor and isolation controller): a044 contactor opened";
CM_ SG_ 1290 HVP_a044_cpVersionMismatch "High-voltage processor (pack contactor and isolation controller): a044 cp version mismatch";
CM_ SG_ 1290 HVP_a045_dcLinkVoltage "High-voltage processor (pack contactor and isolation controller): a045 dc link voltage";
CM_ SG_ 1290 HVP_a046_shuntCurrent "High-voltage processor (pack contactor and isolation controller): a046 shunt current";
CM_ SG_ 1290 HVP_a046_shuntTemperature "High-voltage processor (pack contactor and isolation controller): a046 shunt temperature";
CM_ SG_ 1290 HVP_a046_asicTemperature "High-voltage processor (pack contactor and isolation controller): a046 asic temperature";
CM_ SG_ 1290 HVP_a047_shuntCurrent "High-voltage processor (pack contactor and isolation controller): a047 shunt current";
CM_ SG_ 1290 HVP_a047_auxCurrent "High-voltage processor (pack contactor and isolation controller): a047 aux current";
CM_ SG_ 1290 HVP_a049_contactorPowerV "High-voltage processor (pack contactor and isolation controller): a049 contactor power v";
CM_ SG_ 1290 HVP_a049_coilCurrent "High-voltage processor (pack contactor and isolation controller): a049 coil current";
CM_ SG_ 1290 HVP_a049_posCtrState "High-voltage processor (pack contactor and isolation controller): a049 pos ctr state; raw 0 = signal not available (SNA)";
CM_ SG_ 1290 HVP_a049_negCtrState "High-voltage processor (pack contactor and isolation controller): a049 neg ctr state; raw 0 = signal not available (SNA)";
CM_ SG_ 1290 HVP_a050_contactorPowerV "High-voltage processor (pack contactor and isolation controller): a050 contactor power v";
CM_ SG_ 1290 HVP_a050_coilCurrent "High-voltage processor (pack contactor and isolation controller): a050 coil current";
CM_ SG_ 1290 HVP_a050_posCtrState "High-voltage processor (pack contactor and isolation controller): a050 pos ctr state; raw 0 = signal not available (SNA)";
CM_ SG_ 1290 HVP_a050_negCtrState "High-voltage processor (pack contactor and isolation controller): a050 neg ctr state; raw 0 = signal not available (SNA)";
CM_ SG_ 1290 HVP_a051_shuntTemperature "High-voltage processor (pack contactor and isolation controller): a051 shunt temperature; raw 32768 = signal not available (SNA)";
CM_ SG_ 1290 HVP_a051_shuntCurrent "High-voltage processor (pack contactor and isolation controller): a051 shunt current; raw 32768 = signal not available (SNA)";
CM_ SG_ 1290 HVP_a051_energyReserveV "High-voltage processor (pack contactor and isolation controller): a051 energy reserve v; raw 65535 = signal not available (SNA)";
CM_ SG_ 1290 HVP_a053_packVoltage "High-voltage processor (pack contactor and isolation controller): a053 pack voltage";
CM_ SG_ 1290 HVP_a053_dcLinkVoltage "High-voltage processor (pack contactor and isolation controller): a053 dc link voltage";
CM_ SG_ 1290 HVP_a056_diagnosis "High-voltage processor (pack contactor and isolation controller): a056 diagnosis; raw 0 = signal not available (SNA)";
CM_ SG_ 1290 HVP_a056_shuntCurrent "High-voltage processor (pack contactor and isolation controller): a056 shunt current";
CM_ SG_ 1290 HVP_a056_posPackContactorState "High-voltage processor (pack contactor and isolation controller): a056 pos pack contactor state; raw 0 = signal not available (SNA)";
CM_ SG_ 1290 HVP_a056_negPackContactorState "High-voltage processor (pack contactor and isolation controller): a056 neg pack contactor state; raw 0 = signal not available (SNA)";
CM_ SG_ 1290 HVP_a056_posFcContactorState "High-voltage processor (pack contactor and isolation controller): a056 pos fc contactor state; raw 0 = signal not available (SNA)";
CM_ SG_ 1290 HVP_a056_negFcContactorState "High-voltage processor (pack contactor and isolation controller): a056 neg fc contactor state; raw 0 = signal not available (SNA)";
CM_ SG_ 1290 HVP_a058_VrefSample "High-voltage processor (pack contactor and isolation controller): a058 vref sample";
CM_ SG_ 1290 HVP_a058_bmbDeviceId "High-voltage processor (pack contactor and isolation controller): a058 bmb device id";
CM_ SG_ 1290 HVP_a058_VrefStatus "High-voltage processor (pack contactor and isolation controller): a058 vref status";
CM_ SG_ 1290 HVP_a058_VrefType "High-voltage processor (pack contactor and isolation controller): a058 vref type";
CM_ SG_ 1290 HVP_a060_stackVoltage "High-voltage processor (pack contactor and isolation controller): a060 stack voltage";
CM_ SG_ 1290 HVP_a060_sumBrickVoltage "High-voltage processor (pack contactor and isolation controller): a060 sum brick voltage";
CM_ SG_ 1290 HVP_a060_stackId "High-voltage processor (pack contactor and isolation controller): a060 stack id";
CM_ SG_ 1290 HVP_a062_bmbDeviceMask "High-voltage processor (pack contactor and isolation controller): a062 bmb device mask";
CM_ SG_ 1290 HVP_a067_hvilTypeFromHvp "High-voltage processor (pack contactor and isolation controller): a067 hvil type from hvp";
CM_ SG_ 1290 HVP_a067_hvilTypeFromGateway "High-voltage processor (pack contactor and isolation controller): a067 hvil type from gateway";
CM_ SG_ 1290 HVP_a067_hvilTypeIsFromCal "High-voltage processor (pack contactor and isolation controller): a067 hvil type is from cal";
CM_ SG_ 1290 HVP_a068_shuntTemperature "High-voltage processor (pack contactor and isolation controller): a068 shunt temperature; raw 32768 = signal not available (SNA)";
CM_ SG_ 1290 HVP_a068_shuntCurrent "High-voltage processor (pack contactor and isolation controller): a068 shunt current; raw 32768 = signal not available (SNA)";
CM_ SG_ 1290 HVP_a068_energyReserveV "High-voltage processor (pack contactor and isolation controller): a068 energy reserve v; raw 65535 = signal not available (SNA)";
CM_ BO_ 938 "High-voltage processor (pack contactor and isolation controller) message: alert matrix";
CM_ SG_ 938 HVP_matrixIndex "High-voltage processor (pack contactor and isolation controller): matrix index";
CM_ SG_ 938 HVP_w001_WatchdogReset "High-voltage processor (pack contactor and isolation controller): w001 watchdog reset";
CM_ SG_ 938 HVP_w002_UnusedAlert2 "High-voltage processor (pack contactor and isolation controller): w002 unused alert2";
CM_ SG_ 938 HVP_w003_SwAssertion "High-voltage processor (pack contactor and isolation controller): w003 sw assertion";
CM_ SG_ 938 HVP_w004_CrashEvent "High-voltage processor (pack contactor and isolation controller): w004 crash event";
CM_ SG_ 938 HVP_w005_OverDchgCurrentFault "High-voltage processor (pack contactor and isolation controller): w005 over dchg current fault";
CM_ SG_ 938 HVP_w006_OverChargeCurrentFault "High-voltage processor (pack contactor and isolation controller): w006 over charge current fault";
CM_ SG_ 938 HVP_w007_OverCurrentFault "High-voltage processor (pack contactor and isolation controller): w007 over current fault";
CM_ SG_ 938 HVP_w008_OverTemperatureFault "High-voltage processor (pack contactor and isolation controller): w008 over temperature fault";
CM_ SG_ 938 HVP_w009_OverVoltageFault "High-voltage processor (pack contactor and isolation controller): w009 over voltage fault";
CM_ SG_ 938 HVP_w010_UnderVoltageFault "High-voltage processor (pack contactor and isolation controller): w010 under voltage fault";
CM_ SG_ 938 HVP_w011_PrimaryBmbMiaFault "High-voltage processor (pack contactor and isolation controller): w011 primary bmb mia fault";
CM_ SG_ 938 HVP_w012_BmbDataIntegrityLoss "High-voltage processor (pack contactor and isolation controller): w012 bmb data integrity loss";
CM_ SG_ 938 HVP_w013_BmbCommunication "High-voltage processor (pack contactor and isolation controller): w013 bmb communication";
CM_ SG_ 938 HVP_w014_BmsMiaOnHviFault "High-voltage processor (pack contactor and isolation controller): w014 bms mia on hvi fault";
CM_ SG_ 938 HVP_w015_CpMiaFault "High-voltage processor (pack contactor and isolation controller): w015 cp mia fault";
CM_ SG_ 938 HVP_w016_PcsMiaFault "High-voltage processor (pack contactor and isolation controller): w016 pcs mia fault";
CM_ SG_ 938 HVP_w017_GtwMiaFault "High-voltage processor (pack contactor and isolation controller): w017 gtw mia fault";
CM_ SG_ 938 HVP_w018_powerCyclingPcs "High-voltage processor (pack contactor and isolation controller): w018 power cycling pcs";
CM_ SG_ 938 HVP_w019_CpFault "High-voltage processor (pack contactor and isolation controller): w019 cp fault";
CM_ SG_ 938 HVP_w020_ShuntHwMiaFault "High-voltage processor (pack contactor and isolation controller): w020 shunt hw mia fault";
CM_ SG_ 938 HVP_w021_PyroMiaFault "High-voltage processor (pack contactor and isolation controller): w021 pyro mia fault";
CM_ SG_ 938 HVP_w022_PyroMiaWarning "High-voltage processor (pack contactor and isolation controller): w022 pyro mia warning";
CM_ SG_ 938 HVP_w023_BmbResetRecovery "High-voltage processor (pack contactor and isolation controller): w023 bmb reset recovery";
CM_ SG_ 938 HVP_w024_Supply12vFault "High-voltage processor (pack contactor and isolation controller): w024 supply12v fault";
CM_ SG_ 938 HVP_w025_VerSupplyFault "High-voltage processor (pack contactor and isolation controller): w025 ver supply fault";
CM_ SG_ 938 HVP_w026_HvilFault "High-voltage processor (pack contactor and isolation controller): w026 hvil fault";
CM_ SG_ 938 HVP_w027_BmsMiaOnHvsFault "High-voltage processor (pack contactor and isolation controller): w027 bms mia on hvs fault";
CM_ SG_ 938 HVP_w028_PackVoltMismatchFault "High-voltage processor (pack contactor and isolation controller): w028 pack volt mismatch fault";
CM_ SG_ 938 HVP_w029_EnsMiaFault "High-voltage processor (pack contactor and isolation controller): w029 ens mia fault";
CM_ SG_ 938 HVP_w030_PackPosCtrArcFault "High-voltage processor (pack contactor and isolation controller): w030 pack pos ctr arc fault";
CM_ SG_ 938 HVP_w031_packNegCtrArcFault "High-voltage processor (pack contactor and isolation controller): w031 pack neg ctr arc fault";
CM_ SG_ 938 HVP_w032_ShuntHwAndBmsMiaFault "High-voltage processor (pack contactor and isolation controller): w032 shunt hw and bms mia fault";
CM_ SG_ 938 HVP_w033_fcContHwFault "High-voltage processor (pack contactor and isolation controller): w033 fc cont hw fault";
CM_ SG_ 938 HVP_w034_cpMismatchFault "High-voltage processor (pack contactor and isolation controller): w034 cp mismatch fault";
CM_ SG_ 938 HVP_w035_packContHwFault "High-voltage processor (pack contactor and isolation controller): w035 pack cont hw fault";
CM_ SG_ 938 HVP_w036_pyroFuseBlown "High-voltage processor (pack contactor and isolation controller): w036 pyro fuse blown";
CM_ SG_ 938 HVP_w037_pyroFuseFailedToBlow "High-voltage processor (pack contactor and isolation controller): w037 pyro fuse failed to blow";
CM_ SG_ 938 HVP_w038_CpilFault "High-voltage processor (pack contactor and isolation controller): w038 cpil fault";
CM_ SG_ 938 HVP_w039_PackContactorFellOpen "High-voltage processor (pack contactor and isolation controller): w039 pack contactor fell open";
CM_ SG_ 938 HVP_w040_FcContactorFellOpen "High-voltage processor (pack contactor and isolation controller): w040 fc contactor fell open";
CM_ SG_ 938 HVP_w041_packCtrCloseBlocked "High-voltage processor (pack contactor and isolation controller): w041 pack ctr close blocked";
CM_ SG_ 938 HVP_w042_fcCtrCloseBlocked "High-voltage processor (pack contactor and isolation controller): w042 fc ctr close blocked";
CM_ SG_ 938 HVP_w043_packContactorForceOpen "High-voltage processor (pack contactor and isolation controller): w043 pack contactor force open";
CM_ SG_ 938 HVP_w044_fcContactorForceOpen "High-voltage processor (pack contactor and isolation controller): w044 fc contactor force open";
CM_ SG_ 938 HVP_w045_dcLinkOverVoltage "High-voltage processor (pack contactor and isolation controller): w045 dc link over voltage";
CM_ SG_ 938 HVP_w046_shuntOverTemperature "High-voltage processor (pack contactor and isolation controller): w046 shunt over temperature";
CM_ SG_ 938 HVP_w047_passivePyroDeploy "High-voltage processor (pack contactor and isolation controller): w047 passive pyro deploy";
CM_ SG_ 938 HVP_w048_swUnsupportedBmbAsicTyp "High-voltage processor (pack contactor and isolation controller): w048 sw unsupported bmb asic type";
CM_ SG_ 938 HVP_w049_packCtrCloseFailed "High-voltage processor (pack contactor and isolation controller): w049 pack ctr close failed";
CM_ SG_ 938 HVP_w050_fcCtrCloseFailed "High-voltage processor (pack contactor and isolation controller): w050 fc ctr close failed";
CM_ SG_ 938 HVP_w051_shuntThermistorMia "High-voltage processor (pack contactor and isolation controller): w051 shunt thermistor mia";
CM_ SG_ 938 HVP_w052_BmbStatusRegError "High-voltage processor (pack contactor and isolation controller): w052 bmb status reg error";
CM_ SG_ 938 HVP_w053_hvVoltageSensorRational "High-voltage processor (pack contactor and isolation controller): w053 hv voltage sensor rationality";
CM_ SG_ 938 HVP_w054_swMissingConfigBlock "High-voltage processor (pack contactor and isolation controller): w054 sw missing config block";
CM_ SG_ 938 HVP_w055_swMissingPartNumber "High-voltage processor (pack contactor and isolation controller): w055 sw missing part number";
CM_ SG_ 938 HVP_w056_contactorFailedToOpen "High-voltage processor (pack contactor and isolation controller): w056 contactor failed to open";
CM_ SG_ 938 HVP_w057_BatmanDiagnosticsError "High-voltage processor (pack contactor and isolation controller): w057 batman diagnostics error";
CM_ SG_ 938 HVP_w058_BmbVrefBad "High-voltage processor (pack contactor and isolation controller): w058 bmb vref bad";
CM_ SG_ 938 HVP_w059_BmbVrefWarning "High-voltage processor (pack contactor and isolation controller): w059 bmb vref warning";
CM_ SG_ 938 HVP_w060_StackVoltageSense "High-voltage processor (pack contactor and isolation controller): w060 stack voltage sense";
CM_ SG_ 938 HVP_w061_ShuntCurrentRationality "High-voltage processor (pack contactor and isolation controller): w061 shunt current rationality";
CM_ SG_ 938 HVP_w062_BmbOtpConfigError "High-voltage processor (pack contactor and isolation controller): w062 bmb otp config error";
CM_ SG_ 938 HVP_w063_BmbBrickVRationality "High-voltage processor (pack contactor and isolation controller): w063 bmb brick v rationality";
CM_ SG_ 938 HVP_w064_BmbAuxVRationality "High-voltage processor (pack contactor and isolation controller): w064 bmb aux v rationality";
CM_ SG_ 938 HVP_w065_FastOpenVshDetected "High-voltage processor (pack contactor and isolation controller): w065 fast open vsh detected";
CM_ SG_ 938 HVP_w067_HvilCalNodeMismatch "High-voltage processor (pack contactor and isolation controller): w067 hvil cal node mismatch";
CM_ SG_ 938 HVP_w068_shuntUnexpectedThermist "High-voltage processor (pack contactor and isolation controller): w068 shunt unexpected thermistor";
CM_ SG_ 938 HVP_w069_hviCanFrameRxDropped "High-voltage processor (pack contactor and isolation controller): w069 hvi can frame rx dropped";
CM_ SG_ 938 HVP_w070_hvsCanFrameRxDropped "High-voltage processor (pack contactor and isolation controller): w070 hvs can frame rx dropped";
CM_ SG_ 938 HVP_w071_PassivePyroVrefRational "High-voltage processor (pack contactor and isolation controller): w071 passive pyro vref rationality";
CM_ BO_ 522 "High-voltage processor (pack contactor and isolation controller) message: contactor state";
CM_ SG_ 522 HVP_packContNegativeState "High-voltage processor (pack contactor and isolation controller): pack cont negative state; raw 0 = signal not available (SNA)";
CM_ SG_ 522 HVP_packContPositiveState "Current state of positive pack contactor; raw 0 = signal not available (SNA)";
CM_ SG_ 522 HVP_fcContPositiveAuxOpen "High-voltage processor (pack contactor and isolation controller): fc cont positive aux open";
CM_ SG_ 522 HVP_fcContNegativeAuxOpen "High-voltage processor (pack contactor and isolation controller): fc cont negative aux open";
CM_ SG_ 522 HVP_packContactorSetState "The current state of the pack contactors; raw 0 = signal not available (SNA)";
CM_ SG_ 522 HVP_fcContNegativeState "Current state of the negative FC contactor; raw 0 = signal not available (SNA)";
CM_ SG_ 522 HVP_contactorsBlocked "High-voltage processor (pack contactor and isolation controller): contactors blocked";
CM_ SG_ 522 HVP_fcContPositiveState "Current state of the positive FC contactor; raw 0 = signal not available (SNA)";
CM_ SG_ 522 HVP_fcContactorSetState "The current state of the fast charge contactors; raw 0 = signal not available (SNA)";
CM_ SG_ 522 HVP_fcCtrsRequestStatus "Current status of FC contactor request";
CM_ SG_ 522 HVP_fcCtrsResetRequestRequired "High-voltage processor (pack contactor and isolation controller): fc ctrs reset request required";
CM_ SG_ 522 HVP_fcCtrsOpenNowRequested "Flag indicated immediate-opening request of FC contactors";
CM_ SG_ 522 HVP_fcCtrsOpenRequested "Flag indicating opening request of FC contactors";
CM_ SG_ 522 HVP_fcCtrsClosingAllowed "Flag indicating closure allowance of FC contactors";
CM_ SG_ 522 HVP_packCtrsRequestStatus "Current request status of pack contactors";
CM_ SG_ 522 HVP_packCtrsResetRequestRequired "High-voltage processor (pack contactor and isolation controller): pack ctrs reset request required";
CM_ SG_ 522 HVP_packCtrsOpenNowRequested "Flag indicating immediate-opening request of pack contactors";
CM_ SG_ 522 HVP_packCtrsOpenRequested "Flag indicating opening request of pack contactors";
CM_ SG_ 522 HVP_packCtrsClosingAllowed "Flag indicating closure allowance of pack contactors";
CM_ SG_ 522 HVP_dcLinkAllowedToEnergize "Indicates there should be no HV exposure if the FC link is energized by an internal or external source";
CM_ SG_ 522 HVP_pyroTestInProgress "High-voltage processor (pack contactor and isolation controller): pyro test in progress";
CM_ SG_ 522 HVP_hvilDiag "Diagnostic status of HVIL circuit, including specific FAULT types; raw 14 = signal not available (SNA)";
CM_ SG_ 522 HVP_fcLinkAllowedToEnergize "The type of charge that is allowed to energize the FC link. Indicates that the HVP has disabled the dynamic FC weld check for DC charge, or has enabled the PCS charging hardware for AC charge";
CM_ BO_ 1962 "High-voltage processor (pack contactor and isolation controller) message: debug message";
CM_ SG_ 1962 HVP_debugMessageMultiplexer "High-voltage processor (pack contactor and isolation controller): debug message multiplexer";
CM_ SG_ 1962 HVP_ecuLogUploadRequest "High-voltage processor (pack contactor and isolation controller): ecu log upload request";
CM_ SG_ 1962 HVP_dcLinkVoltage "The HVP's measurement of the DC link voltage";
CM_ SG_ 1962 HVP_packVoltage "High-voltage processor (pack contactor and isolation controller): pack voltage";
CM_ SG_ 1962 HVP_fcLinkVoltage "Measured voltage on FC link";
CM_ SG_ 1962 HVP_10HzTask_stackUsage "High-voltage processor (pack contactor and isolation controller): 10 hz task stack usage";
CM_ SG_ 1962 HVP_packContVoltage "High-voltage processor (pack contactor and isolation controller): pack cont voltage";
CM_ SG_ 1962 HVP_packNegativeV "The HVP's common-mode measurement of PACK-HV-SENSE-NEG relative to chassis ground";
CM_ SG_ 1962 HVP_packPositiveV "The HVP's common-mode measurement of PACK-HV-SENSE-POS relative to chassis ground";
CM_ SG_ 1962 HVP_pyroAnalog "High-voltage processor (pack contactor and isolation controller): pyro analog";
CM_ SG_ 1962 HVP_shuntSetTCRCoeffA "High-voltage processor (pack contactor and isolation controller): shunt set TCR coeff a";
CM_ SG_ 1962 HVP_shuntSetTCRCoeffB "High-voltage processor (pack contactor and isolation controller): shunt set TCR coeff b";
CM_ SG_ 1962 HVP_shuntSetTCRCoeffC "High-voltage processor (pack contactor and isolation controller): shunt set TCR coeff c";
CM_ SG_ 1962 HVP_shuntSetTCRCoeffD "High-voltage processor (pack contactor and isolation controller): shunt set TCR coeff d";
CM_ SG_ 1962 HVP_fcContCoilCurrent "High-voltage processor (pack contactor and isolation controller): fc cont coil current";
CM_ SG_ 1962 HVP_fcContVoltage "High-voltage processor (pack contactor and isolation controller): fc cont voltage";
CM_ SG_ 1962 HVP_hvilInVoltage "Measured HVIL input voltage";
CM_ SG_ 1962 HVP_hvilOutVoltage "Measured HVIL output voltage";
CM_ SG_ 1962 HVP_shuntGainInvalidCountDbg "High-voltage processor (pack contactor and isolation controller): shunt gain invalid count dbg";
CM_ SG_ 1962 HVP_passivePyroRefVoltageMax "High-voltage processor (pack contactor and isolation controller): passive pyro ref voltage max; raw 1023 = signal not available (SNA)";
CM_ SG_ 1962 HVP_passivePyroRefVoltageMin "High-voltage processor (pack contactor and isolation controller): passive pyro ref voltage min; raw 1023 = signal not available (SNA)";
CM_ SG_ 1962 HVP_packContCoilCurrent "High-voltage processor (pack contactor and isolation controller): pack cont coil current";
CM_ SG_ 1962 HVP_battery12V "Monitored voltage sense of 12V battery";
CM_ SG_ 1962 HVP_fcLinkPositiveV "High-voltage processor (pack contactor and isolation controller): fc link positive v";
CM_ BO_ 1666 "High-voltage processor (pack contactor and isolation controller) message: hvp faults";
CM_ SG_ 1666 HVP_packContactorHwFault "High-voltage processor (pack contactor and isolation controller): pack contactor hw fault";
CM_ SG_ 1666 HVP_fcContactorHwFault "High-voltage processor (pack contactor and isolation controller): fc contactor hw fault";
CM_ SG_ 1666 HVP_hvilStatus "High-voltage processor (pack contactor and isolation controller): hvil status";
CM_ BO_ 554 "High-voltage processor (pack contactor and isolation controller) message: hvs control";
CM_ SG_ 554 HVP_dcLinkVoltageRequest "High-voltage processor (pack contactor and isolation controller): dc link voltage request";
CM_ SG_ 554 HVP_pcsControlRequest "The operating state that the HVP would like the PCS to be in";
CM_ SG_ 554 HVP_pcsChargeHwEnabled "The state of the PCS's charge enable line";
CM_ SG_ 554 HVP_pcsDcdcHwEnabled "The state of the PCS's DCDC enable line";
CM_ SG_ 554 HVP_dcLinkVoltageFiltered "High-voltage processor (pack contactor and isolation controller): dc link voltage filtered; raw 1498 = signal not available (SNA)";
CM_ BO_ 2029 "High-voltage processor (pack contactor and isolation controller) message: info";
CM_ SG_ 2029 HVP_infoIndex "High-voltage processor (pack contactor and isolation controller): info index";
CM_ SG_ 2029 HVP_buildType "High-voltage processor (pack contactor and isolation controller): build type";
CM_ SG_ 2029 HVP_buildConfigId "High-voltage processor (pack contactor and isolation controller): build config id";
CM_ SG_ 2029 HVP_hardwareId "High-voltage processor (pack contactor and isolation controller): hardware id";
CM_ SG_ 2029 HVP_componentId "High-voltage processor (pack contactor and isolation controller): component id";
CM_ SG_ 2029 HVP_pcbaId "High-voltage processor (pack contactor and isolation controller): pcba id";
CM_ SG_ 2029 HVP_assemblyId "HVP's assigned assembly ID";
CM_ SG_ 2029 HVP_usageId "HVP's assigned usage ID";
CM_ SG_ 2029 HVP_subUsageId "HVP's assigned subusage ID";
CM_ SG_ 2029 HVP_platformType "High-voltage processor (pack contactor and isolation controller): platform type";
CM_ SG_ 2029 HVP_appCrc "High-voltage processor (pack contactor and isolation controller): app crc";
CM_ SG_ 2029 HVP_appGitHash "High-voltage processor (pack contactor and isolation controller): app git hash";
CM_ SG_ 2029 HVP_bootGitHash "High-voltage processor (pack contactor and isolation controller): boot git hash";
CM_ SG_ 2029 HVP_bootUdsProtoVersion "High-voltage processor (pack contactor and isolation controller): boot uds proto version";
CM_ SG_ 2029 HVP_bootCrc "High-voltage processor (pack contactor and isolation controller): boot crc";
CM_ BO_ 1914 "High-voltage processor (pack contactor and isolation controller) message: log1hz";
CM_ SG_ 1914 HVP_log1HzIndex "High-voltage processor (pack contactor and isolation controller): log1 hz index";
CM_ SG_ 1914 HVP_bmbAsicType "The BMB Asic type being used by this battery pack for reading brick data";
CM_ SG_ 1914 HVP_shuntCurrentAuxLog "High-voltage processor (pack contactor and isolation controller): shunt current aux log";
CM_ SG_ 1914 HVP_pyroSquibResistance "The pyro resistance measured on attempt to close contactor or by the Pyro selftest; raw 65535 = signal not available (SNA)";
CM_ SG_ 1914 HVP_shuntAsicChipXCoordinate "High-voltage processor (pack contactor and isolation controller): shunt asic chip x coordinate";
CM_ SG_ 1914 HVP_shuntAsicChipYCoordinate "High-voltage processor (pack contactor and isolation controller): shunt asic chip y coordinate";
CM_ SG_ 1914 HVP_hvilCalType "High-voltage processor (pack contactor and isolation controller): hvil cal type";
CM_ SG_ 1914 HVP_gpioPcsDcdcPwmEnable "High-voltage processor (pack contactor and isolation controller): gpio pcs dcdc pwm enable";
CM_ SG_ 1914 HVP_gpioPcsChargePwmEnable "High-voltage processor (pack contactor and isolation controller): gpio pcs charge pwm enable";
CM_ SG_ 1914 HVP_gpioPcsEnable "HVP GPIO control for PCS logic power enable line";
CM_ SG_ 1914 HVP_shuntAsicChipWaferNumber "High-voltage processor (pack contactor and isolation controller): shunt asic chip wafer number";
CM_ SG_ 1914 HVP_energyReserveMin "a lowest energy reserve value measured over sliding window";
CM_ SG_ 1914 HVP_energyReserveMax "a highest energy reserve value measured over sliding window";
CM_ SG_ 1914 HVP_energyReserveAvg "an average energy reserve value measured over sliding window";
CM_ BO_ 1553 "High-voltage processor (pack contactor and isolation controller) message: uds response";
CM_ SG_ 1553 HVP_udsResponseData "High-voltage processor (pack contactor and isolation controller): uds response data";
CM_ BO_ 861 "Electric brake booster message: alert matrix";
CM_ SG_ 861 IBST_matrixIndex "Electric brake booster: matrix index";
CM_ SG_ 861 IBST_a001_microSupplyError "Electric brake booster: a001 micro supply error";
CM_ SG_ 861 IBST_a002_HWBISTError "Electric brake booster: a002 HWBIST error";
CM_ SG_ 861 IBST_a003_RAMFault "Electric brake booster: a003 RAM fault";
CM_ SG_ 861 IBST_a004_flashFault "Electric brake booster: a004 flash fault";
CM_ SG_ 861 IBST_a005_microSafetyFault "Electric brake booster: a005 micro safety fault";
CM_ SG_ 861 IBST_a006_microSafetyLogicFault "Electric brake booster: a006 micro safety logic fault";
CM_ SG_ 861 IBST_a007_RBCPUException "Electric brake booster: a007 RBCPU exception";
CM_ SG_ 861 IBST_a008_stackOverUnderFlow "Electric brake booster: a008 stack over under flow";
CM_ SG_ 861 IBST_a009_systemErrorHook "Electric brake booster: a009 system error hook";
CM_ SG_ 861 IBST_a010_OSErrorHook "Electric brake booster: a010 OS error hook";
CM_ SG_ 861 IBST_a011_systemTaskOverRun "Electric brake booster: a011 system task over run";
CM_ SG_ 861 IBST_a012_OSTaskSchemeError "Electric brake booster: a012 OS task scheme error";
CM_ SG_ 861 IBST_a013_systemTaskJitter "Electric brake booster: a013 system task jitter";
CM_ SG_ 861 IBST_a014_DMATransferError "Electric brake booster: a014 DMA transfer error";
CM_ SG_ 861 IBST_a015_asicOscillatorError "Electric brake booster: a015 asic oscillator error";
CM_ SG_ 861 IBST_a016_RBBLMShaftShiftError "Electric brake booster: a016 RBBLM shaft shift error";
CM_ SG_ 861 IBST_a017_assertionFault "Electric brake booster: a017 assertion fault";
CM_ SG_ 861 IBST_a018_unsupportedHW "Electric brake booster: a018 unsupported HW";
CM_ SG_ 861 IBST_a019_supplyASICInitFault "Electric brake booster: a019 supply ASIC init fault";
CM_ SG_ 861 IBST_a020_VPREU5VOutOfRange "Electric brake booster: a020 VPREU5 v out of range";
CM_ SG_ 861 IBST_a021_IREFOutOfRange "Electric brake booster: a021 IREF out of range";
CM_ SG_ 861 IBST_a022_U5VTestFault "Electric brake booster: a022 U5 v test fault";
CM_ SG_ 861 IBST_a023_U5VOutOfRange "Electric brake booster: a023 U5 v out of range";
CM_ SG_ 861 IBST_a024_chargePumpFault "Electric brake booster: a024 charge pump fault";
CM_ SG_ 861 IBST_a025_ecuClockTestFault "Electric brake booster: a025 ecu clock test fault";
CM_ SG_ 861 IBST_a026_ecuBistCmdTestFault "Electric brake booster: a026 ecu bist cmd test fault";
CM_ SG_ 861 IBST_a027_ecuFastWdTestFault "Electric brake booster: a027 ecu fast wd test fault";
CM_ SG_ 861 IBST_a028_ecuBistFaultCtrFault "Electric brake booster: a028 ecu bist fault ctr fault";
CM_ SG_ 861 IBST_a029_ecuErrpinCounterFault "Electric brake booster: a029 ecu errpin counter fault";
CM_ SG_ 861 IBST_a030_ecuEnableElLowFault "Electric brake booster: a030 ecu enable el low fault";
CM_ SG_ 861 IBST_a031_decoupleBitTestFault "Electric brake booster: a031 decouple bit test fault";
CM_ SG_ 861 IBST_a032_ecuEnableElHighFault "Electric brake booster: a032 ecu enable el high fault";
CM_ SG_ 861 IBST_a033_ecuWdStartuptestFault "Electric brake booster: a033 ecu wd startuptest fault";
CM_ SG_ 861 IBST_a034_ecuEnableHyHighFault "Electric brake booster: a034 ecu enable hy high fault";
CM_ SG_ 861 IBST_a035_ecuEnableHyLowFault "Electric brake booster: a035 ecu enable hy low fault";
CM_ SG_ 861 IBST_a036_MRGPathTestFault "Electric brake booster: a036 MRG path test fault";
CM_ SG_ 861 IBST_a037_ecuWdSContinuousError "Electric brake booster: a037 ecu wd s continuous error";
CM_ SG_ 861 IBST_a038_ecuEnContinuousError "Electric brake booster: a038 ecu en continuous error";
CM_ SG_ 861 IBST_a039_GTMRefFrequencyError "Electric brake booster: a039 GTM ref frequency error";
CM_ SG_ 861 IBST_a040_GTMTbuMonError "Electric brake booster: a040 GTM tbu mon error";
CM_ SG_ 861 IBST_a041_micAsicClkInError "Electric brake booster: a041 mic asic clk in error";
CM_ SG_ 861 IBST_a042_micAsicInitTestError "Electric brake booster: a042 mic asic init test error";
CM_ SG_ 861 IBST_a043_micSpiTransferError "Electric brake booster: a043 mic spi transfer error";
CM_ SG_ 861 IBST_a044_NvMEepromWIP "Electric brake booster: a044 nv m eeprom WIP";
CM_ SG_ 861 IBST_a045_WdhAsicWdErrorCntStuck "Electric brake booster: a045 wdh asic wd error cnt stuck";
CM_ SG_ 861 IBST_a046_WdhAsicWdErrorCntLimit "Electric brake booster: a046 wdh asic wd error cnt limit";
CM_ SG_ 861 IBST_a047_WdhAsicWdCmdMissing "Electric brake booster: a047 wdh asic wd cmd missing";
CM_ SG_ 861 IBST_a048_WdhSwBistConCnt "Electric brake booster: a048 wdh sw bist con cnt";
CM_ SG_ 861 IBST_a049_WdhTaskMonConCnt "Electric brake booster: a049 wdh task mon con cnt";
CM_ SG_ 861 IBST_a050_VPreExternalFeeding "Electric brake booster: a050 v pre external feeding";
CM_ SG_ 861 IBST_a051_ecuBandgap "Electric brake booster: a051 ecu bandgap";
CM_ SG_ 861 IBST_a052_AdcPinTest "Electric brake booster: a052 adc pin test";
CM_ SG_ 861 IBST_a053_AdcSelftestC5P "Electric brake booster: a053 adc selftest C5 p";
CM_ SG_ 861 IBST_a054_AdcPeripheralFault "Electric brake booster: a054 adc peripheral fault";
CM_ SG_ 861 IBST_a055_UB6SupplyPathFault "Electric brake booster: a055 UB6 supply path fault";
CM_ SG_ 861 IBST_a056_UB6PlausiMonFault "Electric brake booster: a056 UB6 plausi mon fault";
CM_ SG_ 861 IBST_a057_microRegisterFault "Electric brake booster: a057 micro register fault";
CM_ SG_ 861 IBST_a058_NvMWriteCycleExceed "Electric brake booster: a058 nv m write cycle exceed";
CM_ SG_ 861 IBST_a059_NvMEepromSize "Electric brake booster: a059 nv m eeprom size";
CM_ SG_ 861 IBST_a060_NvMMigrationFault "Electric brake booster: a060 nv m migration fault";
CM_ SG_ 861 IBST_a061_AswSystemTimeOut "Electric brake booster: a061 asw system time out";
CM_ SG_ 861 IBST_a062_MICB6TransferError "Electric brake booster: a062 MICB6 transfer error";
CM_ SG_ 861 IBST_a063_tempSens2ShortToSupply "Electric brake booster: a063 temp sens2 short to supply";
CM_ SG_ 861 IBST_a064_tempSens1ShortToGround "Electric brake booster: a064 temp sens1 short to ground";
CM_ SG_ 861 IBST_a065_tempSens2ShortToGround "Electric brake booster: a065 temp sens2 short to ground";
CM_ SG_ 861 IBST_a066_tempSens1ShortToSupply "Electric brake booster: a066 temp sens1 short to supply";
CM_ SG_ 861 IBST_a067_tempSensImplausVoltage "Electric brake booster: a067 temp sens implaus voltage";
CM_ SG_ 861 IBST_a068_chargePumpUndervoltage "Electric brake booster: a068 charge pump undervoltage";
CM_ SG_ 861 IBST_a069_greasingRoutineFault "Electric brake booster: a069 greasing routine fault";
CM_ SG_ 861 IBST_a070_notShutDownNvMWrite "Electric brake booster: a070 not shut down nv m write";
CM_ SG_ 861 IBST_a071_notShutDownNvMRead "Electric brake booster: a071 not shut down nv m read";
CM_ SG_ 861 IBST_a072_notShutDownRight "Electric brake booster: a072 not shut down right";
CM_ SG_ 861 IBST_a073_jumpInAdjustNvMRead "Electric brake booster: a073 jump in adjust nv m read";
CM_ SG_ 861 IBST_a074_FindIdleDataNvMWrite "Electric brake booster: a074 find idle data nv m write";
CM_ SG_ 861 IBST_a075_FindIdleRoutineFault "Electric brake booster: a075 find idle routine fault";
CM_ SG_ 861 IBST_a076_masterCylLengthRead "Electric brake booster: a076 master cyl length read";
CM_ SG_ 861 IBST_a077_runOutMotorSaturated "Electric brake booster: a077 run out motor saturated";
CM_ SG_ 861 IBST_a078_wearOffsetCompNVMRead "Electric brake booster: a078 wear offset comp NVM read";
CM_ SG_ 861 IBST_a079_motorTempHighLevel1 "Electric brake booster: a079 motor temp high level1";
CM_ SG_ 861 IBST_a080_motorTempHighLevel2 "Electric brake booster: a080 motor temp high level2";
CM_ SG_ 861 IBST_a081_travelDeviation "Electric brake booster: a081 travel deviation";
CM_ SG_ 861 IBST_a082_motorSpeedDeviation "Electric brake booster: a082 motor speed deviation";
CM_ SG_ 861 IBST_a083_spindlePositionTooHigh "Electric brake booster: a083 spindle position too high";
CM_ SG_ 861 IBST_a084_CANTransceiverHWFault "Electric brake booster: a084 CAN transceiver HW fault";
CM_ SG_ 861 IBST_a085_supplyUndervoltageLvl3 "Electric brake booster: a085 supply undervoltage lvl3";
CM_ SG_ 861 IBST_a086_supplyOvervoltageLvl3 "Electric brake booster: a086 supply overvoltage lvl3";
CM_ SG_ 861 IBST_a087_rotorSinOutOfRangeLow "Electric brake booster: a087 rotor sin out of range low";
CM_ SG_ 861 IBST_a088_rotorCosOutOfRangeLow "Electric brake booster: a088 rotor cos out of range low";
CM_ SG_ 861 IBST_a089_rotorSinOutOfRangeHigh "Electric brake booster: a089 rotor sin out of range high";
CM_ SG_ 861 IBST_a090_rotorCosOutOfRangeHigh "Electric brake booster: a090 rotor cos out of range high";
CM_ SG_ 861 IBST_a091_SMMOneRequestsInit "Electric brake booster: a091 SMM one requests init";
CM_ SG_ 861 IBST_a092_systemStartTimeOut "Electric brake booster: a092 system start time out";
CM_ SG_ 861 IBST_a093_UEXSOvertemperature "Electric brake booster: a093 UEXS overtemperature";
CM_ SG_ 861 IBST_a094_XPASSEchoTimeDeviation "Electric brake booster: a094 XPASS echo time deviation";
CM_ SG_ 861 IBST_a095_XPASSTimeOut "Electric brake booster: a095 XPASS time out";
CM_ SG_ 861 IBST_a096_bridgeDriverMonError "Electric brake booster: a096 bridge driver mon error";
CM_ SG_ 861 IBST_a097_bridgeDriverError "Electric brake booster: a097 bridge driver error";
CM_ SG_ 861 IBST_a098_bridgeShortedPhase "Electric brake booster: a098 bridge shorted phase";
CM_ SG_ 861 IBST_a099_bridgeSwitchInitError "Electric brake booster: a099 bridge switch init error";
CM_ SG_ 861 IBST_a100_current2OffsetHigh "Electric brake booster: a100 current2 offset high";
CM_ SG_ 861 IBST_a101_current2OffsetLow "Electric brake booster: a101 current2 offset low";
CM_ SG_ 861 IBST_a102_current1OffsetHigh "Electric brake booster: a102 current1 offset high";
CM_ SG_ 861 IBST_a103_current1OffsetLow "Electric brake booster: a103 current1 offset low";
CM_ SG_ 861 IBST_a104_bridgeDriverShort "Electric brake booster: a104 bridge driver short";
CM_ SG_ 861 IBST_a105_LiPSUndervoltage "Electric brake booster: a105 li PS undervoltage";
CM_ SG_ 861 IBST_a106_LiPS5VSupply "Electric brake booster: a106 li PS5 v supply";
CM_ SG_ 861 IBST_a107_LiPS2PwmLineHigh "Electric brake booster: a107 li PS2 pwm line high";
CM_ SG_ 861 IBST_a108_LiPS2PwmLineLow "Electric brake booster: a108 li PS2 pwm line low";
CM_ SG_ 861 IBST_a109_LiPS2PwmTransmission "Electric brake booster: a109 li PS2 pwm transmission";
CM_ SG_ 861 IBST_a110_LiPS1SentLineHigh "Electric brake booster: a110 li PS1 sent line high";
CM_ SG_ 861 IBST_a111_LiPS1SentLineLow "Electric brake booster: a111 li PS1 sent line low";
CM_ SG_ 861 IBST_a112_LiPS1SentTransmission "Electric brake booster: a112 li PS1 sent transmission";
CM_ SG_ 861 IBST_a113_LiPS1SentSensor "Electric brake booster: a113 li PS1 sent sensor";
CM_ SG_ 861 IBST_a114_partyBusOff "Electric brake booster: a114 party bus off";
CM_ SG_ 861 IBST_a115_chassisBusOff "Electric brake booster: a115 chassis bus off";
CM_ SG_ 861 IBST_a116_supplyUndervoltageLvl2 "Electric brake booster: a116 supply undervoltage lvl2";
CM_ SG_ 861 IBST_a117_supplyOvervoltageLvl2 "Electric brake booster: a117 supply overvoltage lvl2";
CM_ SG_ 861 IBST_a118_RPSNvMReadFault "Electric brake booster: a118 RPS nv m read fault";
CM_ SG_ 861 IBST_a119_RPSWrongCalibData "Electric brake booster: a119 RPS wrong calib data";
CM_ SG_ 861 IBST_a120_RPSVectorRangeHigh "Electric brake booster: a120 RPS vector range high";
CM_ SG_ 861 IBST_a121_RPSVectorRangeLow "Electric brake booster: a121 RPS vector range low";
CM_ SG_ 861 IBST_a122_RPSVectorOscillating "Electric brake booster: a122 RPS vector oscillating";
CM_ SG_ 861 IBST_a123_bridgeDriverUnavail "Electric brake booster: a123 bridge driver unavail";
CM_ SG_ 861 IBST_a124_OBDCurrent1OORHigh "Electric brake booster: a124 OBD current1 OOR high";
CM_ SG_ 861 IBST_a125_OBDCurrent2OORHigh "Electric brake booster: a125 OBD current2 OOR high";
CM_ SG_ 861 IBST_a126_OBDCurrent1OORLow "Electric brake booster: a126 OBD current1 OOR low";
CM_ SG_ 861 IBST_a127_OBDCurrent2OORLow "Electric brake booster: a127 OBD current2 OOR low";
CM_ SG_ 861 IBST_a128_BLMMuxerTimeoutError "Electric brake booster: a128 BLM muxer timeout error";
CM_ SG_ 861 IBST_a129_loadDumpOnFSLTest "Electric brake booster: a129 load dump on FSL test";
CM_ SG_ 861 IBST_a130_DTSFunctionalRangeLow "Electric brake booster: a130 DTS functional range low";
CM_ SG_ 861 IBST_a131_DTSFunctionalRangeHigh "Electric brake booster: a131 DTS functional range high";
CM_ SG_ 861 IBST_a132_DTSPlausiCheck1vs2 "Electric brake booster: a132 DTS plausi check1vs2";
CM_ SG_ 861 IBST_a133_DTSOffsetTooLow "Electric brake booster: a133 DTS offset too low";
CM_ SG_ 861 IBST_a134_DTSOffsetTooHigh "Electric brake booster: a134 DTS offset too high";
CM_ SG_ 861 IBST_a135_ESPparty1DLC "Electric brake booster: a135 ES pparty1 DLC";
CM_ SG_ 861 IBST_a136_ESPparty1Timeout "Electric brake booster: a136 ES pparty1 timeout";
CM_ SG_ 861 IBST_a137_ESPparty1Checksum "Electric brake booster: a137 ES pparty1 checksum";
CM_ SG_ 861 IBST_a138_ESPparty1Counter "Electric brake booster: a138 ES pparty1 counter";
CM_ SG_ 861 IBST_a139_ESPparty2DLC "Electric brake booster: a139 ES pparty2 DLC";
CM_ SG_ 861 IBST_a140_ESPparty2Timeout "Electric brake booster: a140 ES pparty2 timeout";
CM_ SG_ 861 IBST_a141_ESPparty2Checksum "Electric brake booster: a141 ES pparty2 checksum";
CM_ SG_ 861 IBST_a142_ESPparty2Counter "Electric brake booster: a142 ES pparty2 counter";
CM_ SG_ 861 IBST_a143_ESPparty3DLC "Electric brake booster: a143 ES pparty3 DLC";
CM_ SG_ 861 IBST_a144_ESPparty3Timeout "Electric brake booster: a144 ES pparty3 timeout";
CM_ SG_ 861 IBST_a145_ESPparty3Checksum "Electric brake booster: a145 ES pparty3 checksum";
CM_ SG_ 861 IBST_a146_ESPparty3Counter "Electric brake booster: a146 ES pparty3 counter";
CM_ SG_ 861 IBST_a147_PSCMotorSizeReadFault "Electric brake booster: a147 PSC motor size read fault";
CM_ SG_ 861 IBST_a148_MLIGainMechReadFault "Electric brake booster: a148 MLI gain mech read fault";
CM_ SG_ 861 IBST_a149_MLITMCAreaReadFault "Electric brake booster: a149 MLITMC area read fault";
CM_ SG_ 861 IBST_a150_motorTestFault "Electric brake booster: a150 motor test fault";
CM_ SG_ 861 IBST_a151_PSCGearRatioReadFault "Electric brake booster: a151 PSC gear ratio read fault";
CM_ SG_ 861 IBST_a152_PSCVoltageImplausible "Electric brake booster: a152 PSC voltage implausible";
CM_ SG_ 861 IBST_a153_unused "Electric brake booster: a153 unused";
CM_ SG_ 861 IBST_a154_unused "Electric brake booster: a154 unused";
CM_ SG_ 861 IBST_a155_supplyUndervoltageLvl1 "Electric brake booster: a155 supply undervoltage lvl1";
CM_ SG_ 861 IBST_a156_supplyOvervoltageLvl1 "Electric brake booster: a156 supply overvoltage lvl1";
CM_ SG_ 861 IBST_a157_masterCylPressInvalid "Electric brake booster: a157 master cyl press invalid";
CM_ SG_ 861 IBST_a158_DTSOffsHighSuspicious "Electric brake booster: a158 DTS offs high suspicious";
CM_ SG_ 861 IBST_a159_FindIdleNvMReadError "Electric brake booster: a159 find idle nv m read error";
CM_ SG_ 861 IBST_a160_DTSIDTimeOut "Electric brake booster: a160 DTSID time out";
CM_ SG_ 861 IBST_a161_powerPackMismatch "Electric brake booster: a161 power pack mismatch";
CM_ SG_ 861 IBST_a162_idlePosNotDetected "Electric brake booster: a162 idle pos not detected";
CM_ SG_ 861 IBST_a163_ESPpEstMaxInvalid "Electric brake booster: a163 ES pp est max invalid";
CM_ SG_ 861 IBST_a164_ESPVehicleSpeedInvalid "Electric brake booster: a164 ESP vehicle speed invalid";
CM_ SG_ 861 IBST_a165_ESPpForceBlendInvalid "Electric brake booster: a165 ES pp force blend invalid";
CM_ SG_ 861 IBST_a166_ESPpMcVirtualInvalid "Electric brake booster: a166 ES pp mc virtual invalid";
CM_ SG_ 861 IBST_a167_ESPqTargetExterInvalid "Electric brake booster: a167 ES pq target exter invalid";
CM_ SG_ 861 IBST_a168_CANOvervoltage "Electric brake booster: a168 CAN overvoltage";
CM_ SG_ 861 IBST_a169_CANUndervoltage "Electric brake booster: a169 CAN undervoltage";
CM_ SG_ 861 IBST_a170_LVPowerStateTimeout "Electric brake booster: a170 LV power state timeout";
CM_ SG_ 861 IBST_a171_LVPowerStateChecksum "Electric brake booster: a171 LV power state checksum";
CM_ SG_ 861 IBST_a172_LVPowerStateDLC "Electric brake booster: a172 LV power state DLC";
CM_ SG_ 861 IBST_a173_LVPowerStateCounter "Electric brake booster: a173 LV power state counter";
CM_ SG_ 861 IBST_a174_LVOffStateInvalid "Electric brake booster: a174 LV off state invalid";
CM_ SG_ 861 IBST_a175_LVGoingDownInvalid "Electric brake booster: a175 LV going down invalid";
CM_ SG_ 861 IBST_a176_blockedPedalDetected "Electric brake booster: a176 blocked pedal detected";
CM_ SG_ 861 IBST_a177_EPBLsystemStatusMIA "Electric brake booster: a177 EPB lsystem status MIA";
CM_ SG_ 861 IBST_a178_EPBRsystemStatusMIA "Electric brake booster: a178 EPB rsystem status MIA";
CM_ SG_ 861 IBST_a179_VCLEFTepbmStatusMIA "Electric brake booster: a179 VCLEF tepbm status MIA";
CM_ SG_ 861 IBST_a180_VCRIGHTepbmStatusMIA "Electric brake booster: a180 VCRIGH tepbm status MIA";
CM_ SG_ 861 IBST_a181_DIchassisControlDLC "Electric brake booster: a181 d ichassis control DLC";
CM_ SG_ 861 IBST_a182_DIchassisControlTimeou "Electric brake booster: a182 d ichassis control timeout";
CM_ SG_ 861 IBST_a183_DIchassisControlChecks "Electric brake booster: a183 d ichassis control checksum";
CM_ SG_ 861 IBST_a184_DIchassisControlCounte "Electric brake booster: a184 d ichassis control counter";
CM_ SG_ 861 IBST_a185_rightBusOff "Electric brake booster: a185 right bus off";
CM_ SG_ 861 IBST_a186_rightBusPassive "Electric brake booster: a186 right bus passive";
CM_ SG_ 861 IBST_a187_brakeBusOff "Electric brake booster: a187 brake bus off";
CM_ SG_ 861 IBST_a188_brakeBusPassive "Electric brake booster: a188 brake bus passive";
CM_ SG_ 861 IBST_a189_rightVCLVPowerStateTim "Electric brake booster: a189 right VCLV power state timeout";
CM_ SG_ 861 IBST_a190_rightVCLVPowerStateDLC "Electric brake booster: a190 right VCLV power state DLC";
CM_ SG_ 861 IBST_a191_rightVCLVPowerStateChe "Electric brake booster: a191 right VCLV power state checksum";
CM_ SG_ 861 IBST_a192_rightVCLVPowerStateCou "Electric brake booster: a192 right VCLV power state counter";
CM_ SG_ 861 IBST_a193_leftVCLVPowerStateTime "Electric brake booster: a193 left VCLV power state timeout";
CM_ SG_ 861 IBST_a194_leftVCLVPowerStateChec "Electric brake booster: a194 left VCLV power state checksum";
CM_ SG_ 861 IBST_a195_leftVCLVPowerStateDLC "Electric brake booster: a195 left VCLV power state DLC";
CM_ SG_ 861 IBST_a196_leftVCLVPowerStateCoun "Electric brake booster: a196 left VCLV power state counter";
CM_ SG_ 861 IBST_a197_brakeLatencyReductionA "Electric brake booster: a197 brake latency reduction active";
CM_ SG_ 861 IBST_a198_aesActive "Electric brake booster: a198 aes active";
CM_ SG_ 861 IBST_a199_undefinedAlertDetected "Electric brake booster: a199 undefined alert detected";
CM_ SG_ 861 IBST_a200_aesFault "Electric brake booster: a200 aes fault";
CM_ SG_ 861 IBST_a201_EGGREAR1wheelSpeedsRea "Electric brake booster: a201 eggrear1wheel speeds rear time out";
CM_ SG_ 861 IBST_a202_EGGREAR1wheelSpeedsRea "Electric brake booster: a202 eggrear1wheel speeds rear checksum";
CM_ SG_ 861 IBST_a203_EGGREAR1wheelSpeedsRea "Electric brake booster: a203 eggrear1wheel speeds rear DLC";
CM_ SG_ 861 IBST_a204_EGGREAR1wheelSpeedsRea "Electric brake booster: a204 eggrear1wheel speeds rear counter";
CM_ SG_ 861 IBST_a205_EGGRIGHT1wheelSpeedsFr "Electric brake booster: a205 eggright1wheel speeds front time out";
CM_ SG_ 861 IBST_a206_EGGRIGHT1wheelSpeedsFr "Electric brake booster: a206 eggright1wheel speeds front checksum";
CM_ SG_ 861 IBST_a207_EGGRIGHT1wheelSpeedsFr "Electric brake booster: a207 eggright1wheel speeds front DLC";
CM_ SG_ 861 IBST_a208_EGGRIGHT1wheelSpeedsFr "Electric brake booster: a208 eggright1wheel speeds front counter";
CM_ SG_ 861 IBST_a209_reducedBrakePowerActiv "Electric brake booster: a209 reduced brake power active";
CM_ SG_ 861 IBST_a210_reducedBrakePowerNotAv "Electric brake booster: a210 reduced brake power not available";
CM_ SG_ 861 IBST_a211_DETReportError "Electric brake booster: a211 DET report error";
CM_ SG_ 861 IBST_a212_infoFailureWrongCUBASH "Electric brake booster: a212 info failure wrong CUBAS handling detected";
CM_ SG_ 861 IBST_a213_PDURouterinitializatio "Electric brake booster: a213 PDU routerinitialization failed";
CM_ SG_ 861 IBST_a214_LossOfPDUInstanceDetec "Electric brake booster: a214 loss of PDU instance detected";
CM_ SG_ 861 IBST_a215_UnsupportedSeriesHWDet "Electric brake booster: a215 unsupported series HW detected";
CM_ SG_ 861 IBST_a216_AsicMalfunctionDetecte "Electric brake booster: a216 asic malfunction detected";
CM_ SG_ 861 IBST_a217_AsicTrimmingNotComplet "Electric brake booster: a217 asic trimming not completed";
CM_ SG_ 861 IBST_a218_uCSafetyNotificationGR "Electric brake booster: a218 u c safety notification GRAM";
CM_ SG_ 861 IBST_a219_uCSafetyNotification "Electric brake booster: a219 u c safety notification";
CM_ SG_ 861 IBST_a220_ASICOvercurrentOnGPIO2 "Electric brake booster: a220 ASIC overcurrent on GPIO250 2";
CM_ SG_ 861 IBST_a221_ASICOvercurrentOnGPIO2 "Electric brake booster: a221 ASIC overcurrent on GPIO250 1";
CM_ SG_ 861 IBST_a222_ASICOvercurrentOnGPIO5 "Electric brake booster: a222 ASIC overcurrent on GPIO50 4";
CM_ SG_ 861 IBST_a223_ASICOvercurrentOnGPIO5 "Electric brake booster: a223 ASIC overcurrent on GPIO50 3";
CM_ SG_ 861 IBST_a224_ASICOvercurrentOnGPIO5 "Electric brake booster: a224 ASIC overcurrent on GPIO50 2";
CM_ SG_ 861 IBST_a225_ASICOvercurrentOnGPIO5 "Electric brake booster: a225 ASIC overcurrent on GPIO50 1";
CM_ SG_ 861 IBST_a226_ASICOvercurrentOnWRHS "Electric brake booster: a226 ASIC overcurrent on WRHS";
CM_ SG_ 861 IBST_a227_wakeRequestMismatchDet "Electric brake booster: a227 wake request mismatch detected";
CM_ SG_ 861 IBST_a228_BlockedPedalDetectedDu "Electric brake booster: a228 blocked pedal detected during HAD";
CM_ SG_ 861 IBST_a229_BlockedPedalDetected "Electric brake booster: a229 blocked pedal detected";
CM_ SG_ 861 IBST_a230_DTS2FunctionalRangeLow "Electric brake booster: a230 DTS2 functional range low";
CM_ SG_ 861 IBST_a231_DTS2FunctionalRangeLow "Electric brake booster: a231 DTS2 functional range low";
CM_ SG_ 861 IBST_a232_PostAssemblyRoutineFai "Electric brake booster: a232 post assembly routine failed";
CM_ SG_ 861 IBST_a233_ReferenceRunAbortByECU "Electric brake booster: a233 reference run abort by ECU reset";
CM_ SG_ 861 IBST_a234_LiPSOutOfRangeHigh "Electric brake booster: a234 li PS out of range high";
CM_ SG_ 861 IBST_a235_LiPSOutOfRangeLow "Electric brake booster: a235 li PS out of range low";
CM_ SG_ 861 IBST_a246_DASredundantBrakingCon "Electric brake booster: a246 DA sredundant braking control party checksum";
CM_ SG_ 861 IBST_a247_DASredundantBrakingCon "Electric brake booster: a247 DA sredundant braking control party counter";
CM_ SG_ 861 IBST_a248_DASredundantBrakingCon "Electric brake booster: a248 DA sredundant braking control party DLC";
CM_ SG_ 861 IBST_a249_DASredundantBrakingCon "Electric brake booster: a249 DA sredundant braking control party timeout";
CM_ SG_ 861 IBST_a250_DASredundantBrakingCon "Electric brake booster: a250 DA sredundant braking control chassis checksum";
CM_ SG_ 861 IBST_a251_DASredundantBrakingCon "Electric brake booster: a251 DA sredundant braking control chassis counter";
CM_ SG_ 861 IBST_a252_DASredundantBrakingCon "Electric brake booster: a252 DA sredundant braking control chassis DLC";
CM_ SG_ 861 IBST_a253_DASredundantBrakingCon "Electric brake booster: a253 DA sredundant braking control chassis timeout";
CM_ SG_ 861 IBST_a254_DIlocStatus2Checksum "Electric brake booster: a254 d iloc status2 checksum";
CM_ SG_ 861 IBST_a255_DIlocStatus2Counter "Electric brake booster: a255 d iloc status2 counter";
CM_ SG_ 861 IBST_a256_DIlocStatus2DLC "Electric brake booster: a256 d iloc status2 DLC";
CM_ SG_ 861 IBST_a257_DIlocStatus2Timeout "Electric brake booster: a257 d iloc status2 timeout";
CM_ SG_ 861 IBST_a258_standaloneEBRActive "Electric brake booster: a258 standalone EBR active";
CM_ SG_ 861 IBST_a259_EMCMain11Checksum "Electric brake booster: a259 EMC main11 checksum";
CM_ SG_ 861 IBST_a260_EMCMain11Counter "Electric brake booster: a260 EMC main11 counter";
CM_ SG_ 861 IBST_a261_EMCMain11DLC "Electric brake booster: a261 EMC main11 DLC";
CM_ SG_ 861 IBST_a262_EMCMain11Timeout "Electric brake booster: a262 EMC main11 timeout";
CM_ SG_ 861 IBST_a263_EMCMain21Checksum "Electric brake booster: a263 EMC main21 checksum";
CM_ SG_ 861 IBST_a264_EMCMain21Counter "Electric brake booster: a264 EMC main21 counter";
CM_ SG_ 861 IBST_a265_EMCMain21DLC "Electric brake booster: a265 EMC main21 DLC";
CM_ SG_ 861 IBST_a266_EMCMain21Timeout "Electric brake booster: a266 EMC main21 timeout";
CM_ BO_ 813 "Electric brake booster message: info";
CM_ SG_ 813 IBST_infoIndex "Electric brake booster: info index";
CM_ SG_ 813 IBST_infoBuildType "Electric brake booster: info build type";
CM_ SG_ 813 IBST_infoComponentID "Electric brake booster: info component ID";
CM_ SG_ 813 IBST_infoPcbaID "Electric brake booster: info pcba ID";
CM_ SG_ 813 IBST_infoAssemblyID "Electric brake booster: info assembly ID";
CM_ SG_ 813 IBST_infoUsageID "Electric brake booster: info usage ID";
CM_ SG_ 813 IBST_infoSubUsageID "Electric brake booster: info sub usage ID";
CM_ SG_ 813 IBST_infoApplicationCRC "Indicating the Application CRC value of firmware running in system.";
CM_ SG_ 813 IBST_infoBootUdsProtoVersion "Electric brake booster: info boot uds proto version";
CM_ SG_ 813 IBST_infoBootloaderCRC "Electric brake booster: info bootloader CRC";
CM_ SG_ 813 IBST_infoVariantCRC "Indicating the Calibration CRC value of firmware running in system.";
CM_ BO_ 925 "Electric brake booster message: status";
CM_ SG_ 925 IBST_statusChecksum "Electric brake booster: status checksum";
CM_ SG_ 925 IBST_statusCounter "Electric brake booster: status counter";
CM_ SG_ 925 IBST_iBoosterStatus "Indication of iBooster functional state";
CM_ SG_ 925 IBST_driverBrakeApply "Indicates when the driver applies the brake pedal.";
CM_ SG_ 925 IBST_internalState "Indication of iBooster internal state";
CM_ SG_ 925 IBST_sInputRodDriver "IBST estimated input rod stroke";
CM_ SG_ 925 IBST_LVPowerModeState "Electric brake booster: LV power mode state";
CM_ BO_ 1629 "Electric brake booster message: uds response";
CM_ SG_ 1629 IBST_udsResponseData "Electric brake booster: uds response data";
CM_ BO_ 1208 "ICR ECU message: alert log";
CM_ SG_ 1208 ICR_alertID "ICR ECU: alert ID";
CM_ SG_ 1208 ICR_alertState "ICR ECU: alert state";
CM_ SG_ 1208 ICR_a001_watchdogTaskAppDPM "ICR ECU: a001 watchdog task app DPM";
CM_ SG_ 1208 ICR_a001_watchdogTaskMMWControl "ICR ECU: a001 watchdog task MMW control";
CM_ SG_ 1208 ICR_a001_watchdogTaskSentinelInt "ICR ECU: a001 watchdog task sentinel interface";
CM_ SG_ 1208 ICR_a001_watchdogTaskSentinelMod "ICR ECU: a001 watchdog task sentinel mode change";
CM_ SG_ 1208 ICR_a001_watchdogTaskComTXRAD "ICR ECU: a001 watchdog task com TXRAD";
CM_ SG_ 1208 ICR_a001_watchdogTaskComRX "ICR ECU: a001 watchdog task com RX";
CM_ SG_ 1208 ICR_a001_watchdogTaskComTXVEH "ICR ECU: a001 watchdog task com TXVEH";
CM_ SG_ 1208 ICR_a001_watchdogTaskComUDS "ICR ECU: a001 watchdog task com UDS";
CM_ SG_ 1208 ICR_a001_watchdogTaskCommonError "ICR ECU: a001 watchdog task common error";
CM_ SG_ 1208 ICR_a001_watchdogTaskUARTLog "ICR ECU: a001 watchdog task UART log";
CM_ SG_ 1208 ICR_a001_watchdogTaskDataDump "ICR ECU: a001 watchdog task data dump";
CM_ SG_ 1208 ICR_a001_watchdogRTOSAppRun10MS "ICR ECU: a001 watchdog RTOS app run10 MS";
CM_ SG_ 1208 ICR_a001_watchdogRTOSAppRun1MS "ICR ECU: a001 watchdog RTOS app run1 MS";
CM_ SG_ 1208 ICR_a001_InternalWatchdog "ICR ECU: a001 internal watchdog";
CM_ SG_ 1208 ICR_a015_NVMMMemOverflow "ICR ECU: a015 NVMM mem overflow";
CM_ SG_ 1208 ICR_a015_NVMMFilesystemError "ICR ECU: a015 NVMM filesystem error";
CM_ SG_ 1208 ICR_a015_NVMMRecordIDError "ICR ECU: a015 NVMM record ID error";
CM_ SG_ 1208 ICR_a059_voltageDrop "ICR ECU: a059 voltage drop";
CM_ SG_ 1208 ICR_a059_resistanceEstimate "ICR ECU: a059 resistance estimate";
CM_ SG_ 1208 ICR_a059_current "ICR ECU: a059 current";
CM_ SG_ 1208 ICR_a063_switchChannel "ICR ECU: a063 switch channel";
CM_ SG_ 1208 ICR_a063_switchType "ICR ECU: a063 switch type";
CM_ SG_ 1208 ICR_a063_ADCVoltage "ICR ECU: a063 ADC voltage";
CM_ SG_ 1208 ICR_a063_disconnected "ICR ECU: a063 disconnected";
CM_ SG_ 1208 ICR_a063_indeterminate "ICR ECU: a063 indeterminate";
CM_ SG_ 1208 ICR_a063_stuckActive "ICR ECU: a063 stuck active";
CM_ SG_ 1208 ICR_a063_faulted "ICR ECU: a063 faulted";
CM_ SG_ 1208 ICR_a133_nearClutter "ICR ECU: a133 near clutter";
CM_ SG_ 1208 ICR_a133_farClutter "ICR ECU: a133 far clutter";
CM_ SG_ 1208 ICR_a137_nearClutter "ICR ECU: a137 near clutter";
CM_ SG_ 1208 ICR_a137_farClutter "ICR ECU: a137 far clutter";
CM_ SG_ 1208 ICR_a139_nearClutter "ICR ECU: a139 near clutter";
CM_ SG_ 1208 ICR_a139_farClutter "ICR ECU: a139 far clutter";
CM_ SG_ 1208 ICR_a141_pmicQualityExcursion "ICR ECU: a141 pmic quality excursion";
CM_ SG_ 1208 ICR_a141_calDataNotCalibratedOrP "ICR ECU: a141 cal data not calibrated or processing";
CM_ SG_ 1208 ICR_a141_calDataValRXPhaseAboveM "ICR ECU: a141 cal data val RX phase above max";
CM_ SG_ 1208 ICR_a141_calDataValRXPhaseMissin "ICR ECU: a141 cal data val RX phase missing unit mag";
CM_ SG_ 1208 ICR_a141_calDataValRangeBiasAbov "ICR ECU: a141 cal data val range bias above max";
CM_ BO_ 2028 "ICR ECU message: alert matrix";
CM_ SG_ 2028 ICR_matrixIndex "ICR ECU: matrix index";
CM_ SG_ 2028 ICR_a001_WatchdogReset "ICR ECU: a001 watchdog reset";
CM_ SG_ 2028 ICR_a002_PowerLossReset "ICR ECU: a002 power loss reset";
CM_ SG_ 2028 ICR_a003_SWAssertion "ICR ECU: a003 SW assertion";
CM_ SG_ 2028 ICR_a005_CANTXError "ICR ECU: a005 CANTX error";
CM_ SG_ 2028 ICR_a006_CANTX_cyclicError "ICR ECU: a006 CANTX cyclic error";
CM_ SG_ 2028 ICR_a012_CPUReset "ICR ECU: a012 CPU reset";
CM_ SG_ 2028 ICR_a013_AlertManagerFault "ICR ECU: a013 alert manager fault";
CM_ SG_ 2028 ICR_a015_NVMMError "ICR ECU: a015 NVMM error";
CM_ SG_ 2028 ICR_a016_NVMMRecordError "ICR ECU: a016 NVMM record error";
CM_ SG_ 2028 ICR_a021_TaskSchedulerError "ICR ECU: a021 task scheduler error";
CM_ SG_ 2028 ICR_a022_TaskInitError "ICR ECU: a022 task init error";
CM_ SG_ 2028 ICR_a029_CoreDump "ICR ECU: a029 core dump";
CM_ SG_ 2028 ICR_a030_ECULogUploadRequest "ICR ECU: a030 ECU log upload request";
CM_ SG_ 2028 ICR_a031_UDSActive "ICR ECU: a031 UDS active";
CM_ SG_ 2028 ICR_a041_HighCPULoad "ICR ECU: a041 high CPU load";
CM_ SG_ 2028 ICR_a042_HighStackUsage "ICR ECU: a042 high stack usage";
CM_ SG_ 2028 ICR_a043_Task1msError "ICR ECU: a043 task1ms error";
CM_ SG_ 2028 ICR_a044_Task10msError "ICR ECU: a044 task10ms error";
CM_ SG_ 2028 ICR_a045_Task100msError "ICR ECU: a045 task100ms error";
CM_ SG_ 2028 ICR_a046_Task1000msError "ICR ECU: a046 task1000ms error";
CM_ SG_ 2028 ICR_a058_inputRHighSyncDebug "ICR ECU: a058 input r high sync debug";
CM_ SG_ 2028 ICR_a059_inputResistanceHigh "ICR ECU: a059 input resistance high";
CM_ SG_ 2028 ICR_a060_engineeringBuild "ICR ECU: a060 engineering build";
CM_ SG_ 2028 ICR_a061_XCPConnected "ICR ECU: a061 XCP connected";
CM_ SG_ 2028 ICR_a062_XCPWasConnected "ICR ECU: a062 XCP was connected";
CM_ SG_ 2028 ICR_a063_SwitchFault "ICR ECU: a063 switch fault";
CM_ SG_ 2028 ICR_a064_busSleepReqTimeout "ICR ECU: a064 bus sleep req timeout";
CM_ SG_ 2028 ICR_a133_radarBlocked "ICR ECU: a133 radar blocked";
CM_ SG_ 2028 ICR_a134_radarPgood "ICR ECU: a134 radar pgood";
CM_ SG_ 2028 ICR_a135_radarTxBallBreak "ICR ECU: a135 radar tx ball break";
CM_ SG_ 2028 ICR_a136_radarHighTemperature "ICR ECU: a136 radar high temperature";
CM_ SG_ 2028 ICR_a137_radarBlocked "ICR ECU: a137 radar blocked";
CM_ SG_ 2028 ICR_a138_DriverSideMismatch "ICR ECU: a138 driver side mismatch";
CM_ SG_ 2028 ICR_a139_AbnormalBlockageDetecte "ICR ECU: a139 abnormal blockage detected";
CM_ SG_ 2028 ICR_a140_OccupancyExceptionEncou "ICR ECU: a140 occupancy exception encountered";
CM_ SG_ 2028 ICR_a141_RequiresReplacement "ICR ECU: a141 requires replacement";
CM_ SG_ 2028 ICR_a142_ModeOverrideActive "ICR ECU: a142 mode override active";
CM_ SG_ 2028 ICR_a143_DSPCoreSkipped "ICR ECU: a143 DSP core skipped";
CM_ SG_ 2028 ICR_a144_OccupancyNotificationAl "ICR ECU: a144 occupancy notification alert";
CM_ BO_ 941 "ICR ECU message: info";
CM_ SG_ 941 ICR_infoIndex "ICR ECU: info index";
CM_ SG_ 941 ICR_infoBuildType "ICR ECU: info build type";
CM_ SG_ 941 ICR_infoPcbaId "ICR ECU: info pcba id";
CM_ SG_ 941 ICR_infoAssemblyId "ICR ECU: info assembly id";
CM_ SG_ 941 ICR_infoUsageId "ICR ECU: info usage id";
CM_ SG_ 941 ICR_infoAppCrc "ICR ECU: info app crc";
CM_ SG_ 941 ICR_infoBoardPartNumber17 "ICR ECU: info board part number17";
CM_ SG_ 941 ICR_infoBoardPartNumber814 "ICR ECU: info board part number814";
CM_ SG_ 941 ICR_infoBoardPartNumber1520 "ICR ECU: info board part number1520";
CM_ BO_ 667 "ICR ECU message: non localized occupancy";
CM_ SG_ 667 ICR_lifePresenceMLOutput "ICR ECU: life presence ML output; raw 255 = signal not available (SNA)";
CM_ SG_ 667 ICR_largeOccupantPresenceMLOutpu "ICR ECU: large occupant presence ML output; raw 255 = signal not available (SNA)";
CM_ SG_ 667 ICR_lifePresenceRaw "ICR ECU: life presence raw; raw 0 = signal not available (SNA)";
CM_ SG_ 667 ICR_lifePresenceFilt "ICR ECU: life presence filt; raw 0 = signal not available (SNA)";
CM_ SG_ 667 ICR_largeOccupantPresenceRaw "ICR ECU: large occupant presence raw; raw 3 = signal not available (SNA)";
CM_ SG_ 667 ICR_largeOccupantPresenceFilt "Indicates the filtered detection status of the Large Occupant Presence Detection feature; raw 3 = signal not available (SNA)";
CM_ SG_ 667 ICR_childPresenceFunctionality "The functionality of the child presence detection app on ICR; raw 2 = signal not available (SNA)";
CM_ SG_ 667 ICR_userPresenceFunctionality "ICR ECU: user presence functionality; raw 2 = signal not available (SNA)";
CM_ SG_ 667 ICR_userPresenceMLOutput "ICR ECU: user presence ML output; raw 255 = signal not available (SNA)";
CM_ SG_ 667 ICR_userPresenceRaw "ICR ECU: user presence raw; raw 3 = signal not available (SNA)";
CM_ SG_ 667 ICR_userPresenceFilt "Detection status of User Presence Detection feature; raw 3 = signal not available (SNA)";
CM_ BO_ 2027 "ICR ECU message: occupancy";
CM_ SG_ 2027 ICR_occupancy1LRaw "(Non-Functional Interface) Occupancy detection status of First Row left seat; raw 3 = signal not available (SNA)";
CM_ SG_ 2027 ICR_occupancy1RRaw "(Non-Functional Interface) Occupancy detection status of First Row right seat; raw 3 = signal not available (SNA)";
CM_ SG_ 2027 ICR_occupancy1LVoteCnt "ICR ECU: occupancy1 l vote cnt";
CM_ SG_ 2027 ICR_occupancy1RVoteCnt "ICR ECU: occupancy1 r vote cnt";
CM_ SG_ 2027 ICR_occupancy1LFilt "(Non-Functional Interface) Occupancy detection status of First Row left seat; raw 3 = signal not available (SNA)";
CM_ SG_ 2027 ICR_occupancy1RFilt "(Non-Functional Interface) Occupancy detection status of First Row right seat; raw 3 = signal not available (SNA)";
CM_ SG_ 2027 ICR_occupancy2LFilt "ICR ECU: occupancy2 l filt; raw 3 = signal not available (SNA)";
CM_ SG_ 2027 ICR_occupancy2CFilt "ICR ECU: occupancy2 c filt; raw 3 = signal not available (SNA)";
CM_ SG_ 2027 ICR_occupancy2RFilt "ICR ECU: occupancy2 r filt; raw 3 = signal not available (SNA)";
CM_ SG_ 2027 ICR_occupancy1RFiltExp "ICR ECU: occupancy1 r filt exp; raw 3 = signal not available (SNA)";
CM_ SG_ 2027 ICR_occupancyCounter "ICR ECU: occupancy counter";
CM_ SG_ 2027 ICR_occupancyChecksum "ICR ECU: occupancy checksum";
CM_ BO_ 670 "ICR ECU message: occupancy2";
CM_ SG_ 670 ICR_classification1RFilt "Occupant classification status of First Row Right seat; raw 0 = signal not available (SNA)";
CM_ SG_ 670 ICR_classification1LRaw "ICR ECU: classification1 l raw; raw 0 = signal not available (SNA)";
CM_ SG_ 670 ICR_classification1RRaw "ICR ECU: classification1 r raw; raw 0 = signal not available (SNA)";
CM_ SG_ 670 ICR_classification1LMLOutput "ICR ECU: classification1 LML output; raw 255 = signal not available (SNA)";
CM_ SG_ 670 ICR_classification1RMLOutput "ICR ECU: classification1 RML output; raw 255 = signal not available (SNA)";
CM_ SG_ 670 ICR_classification1LqF "ICR ECU: classification1 lq f";
CM_ SG_ 670 ICR_blockageClutterFar "The far clutter output of the blockage algorithm; raw 16 = signal not available (SNA)";
CM_ SG_ 670 ICR_blockageClutterNear "The near clutter output of the blockage algorithm; raw 16 = signal not available (SNA)";
CM_ SG_ 670 ICR_classification1LFilt "ICR ECU: classification1 l filt; raw 0 = signal not available (SNA)";
CM_ SG_ 670 ICR_classification1RqF "ICR ECU: classification1 rq f";
CM_ SG_ 670 ICR_classification1LLatched "ICR ECU: classification1 l latched; raw 0 = signal not available (SNA)";
CM_ SG_ 670 ICR_classification1RLatched "ICR ECU: classification1 r latched; raw 0 = signal not available (SNA)";
CM_ SG_ 670 ICR_classification1LIsLatched "ICR ECU: classification1 l is latched";
CM_ SG_ 670 ICR_classification1RIsLatched "ICR ECU: classification1 r is latched";
CM_ SG_ 670 ICR_occupancy2Counter "ICR ECU: occupancy2 counter";
CM_ SG_ 670 ICR_occupancy2Checksum "ICR ECU: occupancy2 checksum";
CM_ BO_ 2025 "ICR ECU message: status";
CM_ SG_ 2025 ICR_sensorMode "ICR ECU: sensor mode";
CM_ SG_ 2025 ICR_blocked "Indicates if sensor is blocked or not; raw 0 = signal not available (SNA)";
CM_ SG_ 2025 ICR_booted "Indicates if ICR has rebooted";
CM_ SG_ 2025 ICR_rdMapDumpCompleted "ICR ECU: rd map dump completed";
CM_ SG_ 2025 ICR_algoVersion "ICR ECU: algo version";
CM_ SG_ 2025 ICR_l2HeapUsage "ICR ECU: l2 heap usage";
CM_ SG_ 2025 ICR_intrusionStatus "ICR ECU: intrusion status";
CM_ SG_ 2025 ICR_blockageScaledMLOutput "Indicates a scaled blockage ML Output";
CM_ BO_ 1624 "ICR ECU message: uds response";
CM_ SG_ 1624 ICR_udsResponseData "ICR ECU: uds response data";
BA_DEF_ BO_ "GenMsgCycleTime" INT 0 3600000;
BA_DEF_ BO_ "GenMsgSendType" ENUM "Cyclic","NotUsed","NotUsed","NotUsed","NotUsed","NotUsed","NotUsed","IfActive","NoMsgSendType","NotUsed";
BA_DEF_ BO_ "VFrameFormat" ENUM "StandardCAN","ExtendedCAN","reserved","J1939PG","reserved","reserved","reserved","reserved","reserved","reserved","reserved","reserved","reserved","reserved","StandardCAN_FD","ExtendedCAN_FD";
BA_DEF_ BO_ "CANFD_BRS" ENUM "0","1";
BA_DEF_ SG_ "GenSigSNA" STRING;
BA_DEF_ SG_ "SystemSignalLongSymbol" STRING;
BA_DEF_ SG_ "Confidence" ENUM "validated","plausible","layout-only","contradicted";
BA_DEF_DEF_ "GenMsgCycleTime" 0;
BA_DEF_DEF_ "GenMsgSendType" "NoMsgSendType";
BA_DEF_DEF_ "VFrameFormat" "StandardCAN";
BA_DEF_DEF_ "CANFD_BRS" "1";
BA_DEF_DEF_ "GenSigSNA" "";
BA_DEF_DEF_ "SystemSignalLongSymbol" "";
BA_DEF_DEF_ "Confidence" "layout-only";
BA_ "GenMsgCycleTime" BO_ 938 1000;
BA_ "GenMsgSendType" BO_ 938 0;
BA_ "GenMsgCycleTime" BO_ 522 1000;
BA_ "GenMsgSendType" BO_ 522 0;
BA_ "GenMsgCycleTime" BO_ 1962 1000;
BA_ "GenMsgSendType" BO_ 1962 0;
BA_ "GenMsgCycleTime" BO_ 1666 100;
BA_ "GenMsgSendType" BO_ 1666 0;
BA_ "GenMsgCycleTime" BO_ 554 100;
BA_ "GenMsgSendType" BO_ 554 0;
BA_ "GenMsgCycleTime" BO_ 2029 10000;
BA_ "GenMsgSendType" BO_ 2029 0;
BA_ "GenMsgCycleTime" BO_ 1914 1000;
BA_ "GenMsgSendType" BO_ 1914 0;
BA_ "GenMsgCycleTime" BO_ 861 1000;
BA_ "GenMsgSendType" BO_ 861 0;
BA_ "GenMsgCycleTime" BO_ 813 10000;
BA_ "GenMsgSendType" BO_ 813 0;
BA_ "GenMsgCycleTime" BO_ 925 40;
BA_ "GenMsgSendType" BO_ 925 0;
BA_ "GenMsgCycleTime" BO_ 2028 100;
BA_ "GenMsgSendType" BO_ 2028 0;
BA_ "GenMsgCycleTime" BO_ 941 10000;
BA_ "GenMsgSendType" BO_ 941 0;
BA_ "GenMsgCycleTime" BO_ 667 100;
BA_ "GenMsgSendType" BO_ 667 0;
BA_ "GenMsgCycleTime" BO_ 2027 100;
BA_ "GenMsgSendType" BO_ 2027 0;
BA_ "GenMsgCycleTime" BO_ 670 100;
BA_ "GenMsgSendType" BO_ 670 0;
BA_ "GenMsgCycleTime" BO_ 2025 100;
BA_ "GenMsgSendType" BO_ 2025 0;
BA_ "Confidence" SG_ 1290 HVP_alertID 1;
BA_ "Confidence" SG_ 1290 HVP_alertSet 1;
BA_ "Confidence" SG_ 1290 HVP_a005_current 1;
BA_ "Confidence" SG_ 1290 HVP_a006_current 1;
BA_ "Confidence" SG_ 1290 HVP_a007_current 1;
BA_ "Confidence" SG_ 1290 HVP_a008_temperature 1;
BA_ "Confidence" SG_ 1290 HVP_a009_brickVoltage 1;
BA_ "Confidence" SG_ 1290 HVP_a010_brickVoltage 1;
BA_ "Confidence" SG_ 1290 HVP_a012_bmbCommStatusTypeA 1;
BA_ "Confidence" SG_ 1290 HVP_a012_bmbCommStatusTypeB 1;
BA_ "Confidence" SG_ 1290 HVP_a013_bmbCommStatusTypeA 1;
BA_ "Confidence" SG_ 1290 HVP_a013_bmbCommStatusTypeB 1;
BA_ "Confidence" SG_ 1290 HVP_a013_bmbChainBreakType 1;
BA_ "Confidence" SG_ 1290 HVP_a018_dcLinkVoltage 1;
BA_ "Confidence" SG_ 1290 HVP_a018_battery12V 1;
BA_ "SystemSignalLongSymbol" SG_ 1290 HVP_a018_remainingPcsPowerCycles "HVP_a018_remainingPcsPowerCyclesAllowed";
BA_ "SystemSignalLongSymbol" SG_ 1290 HVP_a018_remainingPcsRecoveriesA "HVP_a018_remainingPcsRecoveriesAllowed";
BA_ "SystemSignalLongSymbol" SG_ 1290 HVP_a018_hvcHardwareSupportsCycl "HVP_a018_hvcHardwareSupportsCycling";
BA_ "SystemSignalLongSymbol" SG_ 1290 HVP_a018_pcsHardwareOkToBePowerC "HVP_a018_pcsHardwareOkToBePowerCycled";
BA_ "Confidence" SG_ 1290 HVP_a020_energyReserveV 1;
BA_ "GenSigSNA" SG_ 1290 HVP_a020_energyReserveV "65535";
BA_ "Confidence" SG_ 1290 HVP_a020_shuntCurrentAux 1;
BA_ "GenSigSNA" SG_ 1290 HVP_a020_shuntCurrentAux "32768";
BA_ "Confidence" SG_ 1290 HVP_a020_shuntTemperature 1;
BA_ "GenSigSNA" SG_ 1290 HVP_a020_shuntTemperature "32768";
BA_ "Confidence" SG_ 1290 HVP_a021_pyroStatus 1;
BA_ "SystemSignalLongSymbol" SG_ 1290 HVP_a021_HighSideSwitchTestFaile "HVP_a021_HighSideSwitchTestFailed";
BA_ "Confidence" SG_ 1290 HVP_a021_SquibResistance 1;
BA_ "GenSigSNA" SG_ 1290 HVP_a021_SquibResistance "65535";
BA_ "Confidence" SG_ 1290 HVP_a021_Aout 1;
BA_ "GenSigSNA" SG_ 1290 HVP_a021_Aout "16383";
BA_ "Confidence" SG_ 1290 HVP_a022_pyroStatus 1;
BA_ "Confidence" SG_ 1290 HVP_a022_Aout 1;
BA_ "GenSigSNA" SG_ 1290 HVP_a022_Aout "16383";
BA_ "Confidence" SG_ 1290 HVP_a022_SquibResistance 1;
BA_ "GenSigSNA" SG_ 1290 HVP_a022_SquibResistance "65535";
BA_ "Confidence" SG_ 1290 HVP_a024_voltage 1;
BA_ "Confidence" SG_ 1290 HVP_a025_voltage1 1;
BA_ "Confidence" SG_ 1290 HVP_a025_voltage2 1;
BA_ "Confidence" SG_ 1290 HVP_a025_packVoltage 1;
BA_ "Confidence" SG_ 1290 HVP_a026_hvilStatus 1;
BA_ "GenSigSNA" SG_ 1290 HVP_a026_hvilStatus "14";
BA_ "Confidence" SG_ 1290 HVP_a026_inputVoltage 1;
BA_ "Confidence" SG_ 1290 HVP_a026_outputVoltage 1;
BA_ "Confidence" SG_ 1290 HVP_a026_internalVoltage 1;
BA_ "GenSigSNA" SG_ 1290 HVP_a026_internalVoltage "255";
BA_ "Confidence" SG_ 1290 HVP_a026_dirVoltage 1;
BA_ "GenSigSNA" SG_ 1290 HVP_a026_dirVoltage "255";
BA_ "Confidence" SG_ 1290 HVP_a026_difVoltage 1;
BA_ "GenSigSNA" SG_ 1290 HVP_a026_difVoltage "255";
BA_ "Confidence" SG_ 1290 HVP_a028_packVoltage 1;
BA_ "Confidence" SG_ 1290 HVP_a028_sumOfBrickV 1;
BA_ "Confidence" SG_ 1290 HVP_a030_packPositiveLinkV 1;
BA_ "Confidence" SG_ 1290 HVP_a030_dcPositiveLinkV 1;
BA_ "Confidence" SG_ 1290 HVP_a031_packNegativeLinkV 1;
BA_ "Confidence" SG_ 1290 HVP_a031_dcNegativeLinkV 1;
BA_ "Confidence" SG_ 1290 HVP_a033_contactorPowerV 1;
BA_ "Confidence" SG_ 1290 HVP_a033_coilCurrent 1;
BA_ "Confidence" SG_ 1290 HVP_a033_pwmDutyCylePositive 1;
BA_ "Confidence" SG_ 1290 HVP_a033_pwmDutyCyleNegative 1;
BA_ "Confidence" SG_ 1290 HVP_a035_contactorPowerV 1;
BA_ "Confidence" SG_ 1290 HVP_a035_coilCurrent 1;
BA_ "Confidence" SG_ 1290 HVP_a035_pwmDutyCylePositive 1;
BA_ "Confidence" SG_ 1290 HVP_a035_pwmDutyCyleNegative 1;
BA_ "Confidence" SG_ 1290 HVP_a036_pyroFiringHandle 1;
BA_ "Confidence" SG_ 1290 HVP_a037_pyroFiringHandle 1;
BA_ "Confidence" SG_ 1290 HVP_a040_powerVoltage 1;
BA_ "Confidence" SG_ 1290 HVP_a040_coilCurrent 1;
BA_ "Confidence" SG_ 1290 HVP_a040_posCtrVoltageDrop 1;
BA_ "Confidence" SG_ 1290 HVP_a040_negCtrVoltageDrop 1;
BA_ "Confidence" SG_ 1290 HVP_a045_dcLinkVoltage 1;
BA_ "Confidence" SG_ 1290 HVP_a046_shuntCurrent 1;
BA_ "Confidence" SG_ 1290 HVP_a046_shuntTemperature 1;
BA_ "Confidence" SG_ 1290 HVP_a046_asicTemperature 1;
BA_ "Confidence" SG_ 1290 HVP_a047_shuntCurrent 1;
BA_ "Confidence" SG_ 1290 HVP_a047_auxCurrent 1;
BA_ "Confidence" SG_ 1290 HVP_a049_contactorPowerV 1;
BA_ "Confidence" SG_ 1290 HVP_a049_coilCurrent 1;
BA_ "Confidence" SG_ 1290 HVP_a049_posCtrState 1;
BA_ "GenSigSNA" SG_ 1290 HVP_a049_posCtrState "0";
BA_ "Confidence" SG_ 1290 HVP_a049_negCtrState 1;
BA_ "GenSigSNA" SG_ 1290 HVP_a049_negCtrState "0";
BA_ "Confidence" SG_ 1290 HVP_a050_contactorPowerV 1;
BA_ "Confidence" SG_ 1290 HVP_a050_coilCurrent 1;
BA_ "Confidence" SG_ 1290 HVP_a050_posCtrState 1;
BA_ "GenSigSNA" SG_ 1290 HVP_a050_posCtrState "0";
BA_ "Confidence" SG_ 1290 HVP_a050_negCtrState 1;
BA_ "GenSigSNA" SG_ 1290 HVP_a050_negCtrState "0";
BA_ "Confidence" SG_ 1290 HVP_a051_shuntTemperature 1;
BA_ "GenSigSNA" SG_ 1290 HVP_a051_shuntTemperature "32768";
BA_ "Confidence" SG_ 1290 HVP_a051_shuntCurrent 1;
BA_ "GenSigSNA" SG_ 1290 HVP_a051_shuntCurrent "32768";
BA_ "Confidence" SG_ 1290 HVP_a051_energyReserveV 1;
BA_ "GenSigSNA" SG_ 1290 HVP_a051_energyReserveV "65535";
BA_ "Confidence" SG_ 1290 HVP_a053_packVoltage 1;
BA_ "Confidence" SG_ 1290 HVP_a053_dcLinkVoltage 1;
BA_ "Confidence" SG_ 1290 HVP_a056_diagnosis 1;
BA_ "GenSigSNA" SG_ 1290 HVP_a056_diagnosis "0";
BA_ "Confidence" SG_ 1290 HVP_a056_shuntCurrent 1;
BA_ "Confidence" SG_ 1290 HVP_a056_posPackContactorState 1;
BA_ "GenSigSNA" SG_ 1290 HVP_a056_posPackContactorState "0";
BA_ "Confidence" SG_ 1290 HVP_a056_negPackContactorState 1;
BA_ "GenSigSNA" SG_ 1290 HVP_a056_negPackContactorState "0";
BA_ "Confidence" SG_ 1290 HVP_a056_posFcContactorState 1;
BA_ "GenSigSNA" SG_ 1290 HVP_a056_posFcContactorState "0";
BA_ "Confidence" SG_ 1290 HVP_a056_negFcContactorState 1;
BA_ "GenSigSNA" SG_ 1290 HVP_a056_negFcContactorState "0";
BA_ "Confidence" SG_ 1290 HVP_a058_VrefSample 1;
BA_ "Confidence" SG_ 1290 HVP_a058_VrefStatus 1;
BA_ "Confidence" SG_ 1290 HVP_a058_VrefType 1;
BA_ "Confidence" SG_ 1290 HVP_a060_stackVoltage 1;
BA_ "Confidence" SG_ 1290 HVP_a060_sumBrickVoltage 1;
BA_ "Confidence" SG_ 1290 HVP_a067_hvilTypeFromHvp 1;
BA_ "Confidence" SG_ 1290 HVP_a067_hvilTypeFromGateway 1;
BA_ "Confidence" SG_ 1290 HVP_a068_shuntTemperature 1;
BA_ "GenSigSNA" SG_ 1290 HVP_a068_shuntTemperature "32768";
BA_ "Confidence" SG_ 1290 HVP_a068_shuntCurrent 1;
BA_ "GenSigSNA" SG_ 1290 HVP_a068_shuntCurrent "32768";
BA_ "Confidence" SG_ 1290 HVP_a068_energyReserveV 1;
BA_ "GenSigSNA" SG_ 1290 HVP_a068_energyReserveV "65535";
BA_ "Confidence" SG_ 938 HVP_matrixIndex 1;
BA_ "Confidence" SG_ 938 HVP_w001_WatchdogReset 1;
BA_ "Confidence" SG_ 938 HVP_w002_UnusedAlert2 1;
BA_ "Confidence" SG_ 938 HVP_w003_SwAssertion 1;
BA_ "Confidence" SG_ 938 HVP_w004_CrashEvent 1;
BA_ "Confidence" SG_ 938 HVP_w005_OverDchgCurrentFault 1;
BA_ "Confidence" SG_ 938 HVP_w006_OverChargeCurrentFault 1;
BA_ "Confidence" SG_ 938 HVP_w007_OverCurrentFault 1;
BA_ "Confidence" SG_ 938 HVP_w008_OverTemperatureFault 1;
BA_ "Confidence" SG_ 938 HVP_w009_OverVoltageFault 1;
BA_ "Confidence" SG_ 938 HVP_w010_UnderVoltageFault 1;
BA_ "Confidence" SG_ 938 HVP_w011_PrimaryBmbMiaFault 1;
BA_ "Confidence" SG_ 938 HVP_w012_BmbDataIntegrityLoss 1;
BA_ "Confidence" SG_ 938 HVP_w013_BmbCommunication 1;
BA_ "Confidence" SG_ 938 HVP_w014_BmsMiaOnHviFault 1;
BA_ "Confidence" SG_ 938 HVP_w015_CpMiaFault 1;
BA_ "Confidence" SG_ 938 HVP_w016_PcsMiaFault 1;
BA_ "Confidence" SG_ 938 HVP_w017_GtwMiaFault 1;
BA_ "Confidence" SG_ 938 HVP_w018_powerCyclingPcs 1;
BA_ "Confidence" SG_ 938 HVP_w019_CpFault 1;
BA_ "Confidence" SG_ 938 HVP_w020_ShuntHwMiaFault 1;
BA_ "Confidence" SG_ 938 HVP_w021_PyroMiaFault 1;
BA_ "Confidence" SG_ 938 HVP_w022_PyroMiaWarning 1;
BA_ "Confidence" SG_ 938 HVP_w023_BmbResetRecovery 1;
BA_ "Confidence" SG_ 938 HVP_w024_Supply12vFault 1;
BA_ "Confidence" SG_ 938 HVP_w025_VerSupplyFault 1;
BA_ "Confidence" SG_ 938 HVP_w026_HvilFault 1;
BA_ "Confidence" SG_ 938 HVP_w027_BmsMiaOnHvsFault 1;
BA_ "Confidence" SG_ 938 HVP_w028_PackVoltMismatchFault 1;
BA_ "Confidence" SG_ 938 HVP_w029_EnsMiaFault 1;
BA_ "Confidence" SG_ 938 HVP_w030_PackPosCtrArcFault 1;
BA_ "Confidence" SG_ 938 HVP_w031_packNegCtrArcFault 1;
BA_ "Confidence" SG_ 938 HVP_w032_ShuntHwAndBmsMiaFault 1;
BA_ "Confidence" SG_ 938 HVP_w033_fcContHwFault 1;
BA_ "Confidence" SG_ 938 HVP_w034_cpMismatchFault 1;
BA_ "Confidence" SG_ 938 HVP_w035_packContHwFault 1;
BA_ "Confidence" SG_ 938 HVP_w036_pyroFuseBlown 1;
BA_ "Confidence" SG_ 938 HVP_w037_pyroFuseFailedToBlow 1;
BA_ "Confidence" SG_ 938 HVP_w038_CpilFault 1;
BA_ "Confidence" SG_ 938 HVP_w039_PackContactorFellOpen 1;
BA_ "Confidence" SG_ 938 HVP_w040_FcContactorFellOpen 1;
BA_ "Confidence" SG_ 938 HVP_w041_packCtrCloseBlocked 1;
BA_ "Confidence" SG_ 938 HVP_w042_fcCtrCloseBlocked 1;
BA_ "Confidence" SG_ 938 HVP_w043_packContactorForceOpen 1;
BA_ "Confidence" SG_ 938 HVP_w044_fcContactorForceOpen 1;
BA_ "Confidence" SG_ 938 HVP_w045_dcLinkOverVoltage 1;
BA_ "Confidence" SG_ 938 HVP_w046_shuntOverTemperature 1;
BA_ "Confidence" SG_ 938 HVP_w047_passivePyroDeploy 1;
BA_ "Confidence" SG_ 938 HVP_w048_swUnsupportedBmbAsicTyp 1;
BA_ "SystemSignalLongSymbol" SG_ 938 HVP_w048_swUnsupportedBmbAsicTyp "HVP_w048_swUnsupportedBmbAsicType";
BA_ "Confidence" SG_ 938 HVP_w049_packCtrCloseFailed 1;
BA_ "Confidence" SG_ 938 HVP_w050_fcCtrCloseFailed 1;
BA_ "Confidence" SG_ 938 HVP_w051_shuntThermistorMia 1;
BA_ "Confidence" SG_ 938 HVP_w052_BmbStatusRegError 1;
BA_ "Confidence" SG_ 938 HVP_w053_hvVoltageSensorRational 1;
BA_ "SystemSignalLongSymbol" SG_ 938 HVP_w053_hvVoltageSensorRational "HVP_w053_hvVoltageSensorRationality";
BA_ "Confidence" SG_ 938 HVP_w054_swMissingConfigBlock 1;
BA_ "Confidence" SG_ 938 HVP_w055_swMissingPartNumber 1;
BA_ "Confidence" SG_ 938 HVP_w056_contactorFailedToOpen 1;
BA_ "Confidence" SG_ 938 HVP_w057_BatmanDiagnosticsError 1;
BA_ "Confidence" SG_ 938 HVP_w058_BmbVrefBad 1;
BA_ "Confidence" SG_ 938 HVP_w059_BmbVrefWarning 1;
BA_ "Confidence" SG_ 938 HVP_w060_StackVoltageSense 1;
BA_ "Confidence" SG_ 938 HVP_w061_ShuntCurrentRationality 1;
BA_ "Confidence" SG_ 938 HVP_w062_BmbOtpConfigError 1;
BA_ "Confidence" SG_ 938 HVP_w063_BmbBrickVRationality 1;
BA_ "Confidence" SG_ 938 HVP_w064_BmbAuxVRationality 1;
BA_ "Confidence" SG_ 938 HVP_w065_FastOpenVshDetected 1;
BA_ "Confidence" SG_ 938 HVP_w067_HvilCalNodeMismatch 1;
BA_ "Confidence" SG_ 938 HVP_w068_shuntUnexpectedThermist 1;
BA_ "SystemSignalLongSymbol" SG_ 938 HVP_w068_shuntUnexpectedThermist "HVP_w068_shuntUnexpectedThermistor";
BA_ "Confidence" SG_ 938 HVP_w069_hviCanFrameRxDropped 1;
BA_ "Confidence" SG_ 938 HVP_w070_hvsCanFrameRxDropped 1;
BA_ "Confidence" SG_ 938 HVP_w071_PassivePyroVrefRational 1;
BA_ "SystemSignalLongSymbol" SG_ 938 HVP_w071_PassivePyroVrefRational "HVP_w071_PassivePyroVrefRationality";
BA_ "Confidence" SG_ 522 HVP_packContNegativeState 0;
BA_ "GenSigSNA" SG_ 522 HVP_packContNegativeState "0";
BA_ "Confidence" SG_ 522 HVP_packContPositiveState 0;
BA_ "GenSigSNA" SG_ 522 HVP_packContPositiveState "0";
BA_ "Confidence" SG_ 522 HVP_fcContPositiveAuxOpen 0;
BA_ "Confidence" SG_ 522 HVP_fcContNegativeAuxOpen 0;
BA_ "Confidence" SG_ 522 HVP_packContactorSetState 0;
BA_ "GenSigSNA" SG_ 522 HVP_packContactorSetState "0";
BA_ "Confidence" SG_ 522 HVP_fcContNegativeState 0;
BA_ "GenSigSNA" SG_ 522 HVP_fcContNegativeState "0";
BA_ "Confidence" SG_ 522 HVP_contactorsBlocked 0;
BA_ "Confidence" SG_ 522 HVP_fcContPositiveState 0;
BA_ "GenSigSNA" SG_ 522 HVP_fcContPositiveState "0";
BA_ "Confidence" SG_ 522 HVP_fcContactorSetState 0;
BA_ "GenSigSNA" SG_ 522 HVP_fcContactorSetState "0";
BA_ "Confidence" SG_ 522 HVP_fcCtrsRequestStatus 0;
BA_ "Confidence" SG_ 522 HVP_fcCtrsResetRequestRequired 0;
BA_ "Confidence" SG_ 522 HVP_fcCtrsOpenNowRequested 0;
BA_ "Confidence" SG_ 522 HVP_fcCtrsOpenRequested 0;
BA_ "Confidence" SG_ 522 HVP_fcCtrsClosingAllowed 0;
BA_ "Confidence" SG_ 522 HVP_packCtrsRequestStatus 0;
BA_ "Confidence" SG_ 522 HVP_packCtrsResetRequestRequired 0;
BA_ "Confidence" SG_ 522 HVP_packCtrsOpenNowRequested 0;
BA_ "Confidence" SG_ 522 HVP_packCtrsOpenRequested 0;
BA_ "Confidence" SG_ 522 HVP_packCtrsClosingAllowed 0;
BA_ "Confidence" SG_ 522 HVP_dcLinkAllowedToEnergize 0;
BA_ "Confidence" SG_ 522 HVP_pyroTestInProgress 0;
BA_ "Confidence" SG_ 522 HVP_hvilDiag 0;
BA_ "GenSigSNA" SG_ 522 HVP_hvilDiag "14";
BA_ "Confidence" SG_ 522 HVP_fcLinkAllowedToEnergize 0;
BA_ "Confidence" SG_ 1962 HVP_debugMessageMultiplexer 1;
BA_ "Confidence" SG_ 1962 HVP_ecuLogUploadRequest 0;
BA_ "Confidence" SG_ 1962 HVP_dcLinkVoltage 0;
BA_ "Confidence" SG_ 1962 HVP_packVoltage 0;
BA_ "Confidence" SG_ 1962 HVP_fcLinkVoltage 0;
BA_ "Confidence" SG_ 1962 HVP_10HzTask_stackUsage 0;
BA_ "Confidence" SG_ 1962 HVP_packContVoltage 0;
BA_ "Confidence" SG_ 1962 HVP_packNegativeV 0;
BA_ "Confidence" SG_ 1962 HVP_packPositiveV 0;
BA_ "Confidence" SG_ 1962 HVP_pyroAnalog 3;
BA_ "Confidence" SG_ 1962 HVP_shuntSetTCRCoeffA 0;
BA_ "Confidence" SG_ 1962 HVP_shuntSetTCRCoeffB 0;
BA_ "Confidence" SG_ 1962 HVP_shuntSetTCRCoeffC 0;
BA_ "Confidence" SG_ 1962 HVP_shuntSetTCRCoeffD 0;
BA_ "Confidence" SG_ 1962 HVP_fcContCoilCurrent 0;
BA_ "Confidence" SG_ 1962 HVP_fcContVoltage 0;
BA_ "Confidence" SG_ 1962 HVP_hvilInVoltage 0;
BA_ "Confidence" SG_ 1962 HVP_hvilOutVoltage 0;
BA_ "Confidence" SG_ 1962 HVP_shuntGainInvalidCountDbg 0;
BA_ "Confidence" SG_ 1962 HVP_passivePyroRefVoltageMax 0;
BA_ "GenSigSNA" SG_ 1962 HVP_passivePyroRefVoltageMax "1023";
BA_ "Confidence" SG_ 1962 HVP_passivePyroRefVoltageMin 0;
BA_ "GenSigSNA" SG_ 1962 HVP_passivePyroRefVoltageMin "1023";
BA_ "Confidence" SG_ 1962 HVP_packContCoilCurrent 0;
BA_ "Confidence" SG_ 1962 HVP_battery12V 0;
BA_ "Confidence" SG_ 1962 HVP_fcLinkPositiveV 0;
BA_ "Confidence" SG_ 1666 HVP_packContactorHwFault 1;
BA_ "Confidence" SG_ 1666 HVP_fcContactorHwFault 1;
BA_ "Confidence" SG_ 1666 HVP_hvilStatus 1;
BA_ "Confidence" SG_ 554 HVP_dcLinkVoltageRequest 0;
BA_ "Confidence" SG_ 554 HVP_pcsControlRequest 0;
BA_ "Confidence" SG_ 554 HVP_pcsChargeHwEnabled 0;
BA_ "Confidence" SG_ 554 HVP_pcsDcdcHwEnabled 0;
BA_ "Confidence" SG_ 554 HVP_dcLinkVoltageFiltered 0;
BA_ "GenSigSNA" SG_ 554 HVP_dcLinkVoltageFiltered "1498";
BA_ "Confidence" SG_ 2029 HVP_infoIndex 1;
BA_ "Confidence" SG_ 2029 HVP_buildType 0;
BA_ "Confidence" SG_ 2029 HVP_buildConfigId 0;
BA_ "Confidence" SG_ 2029 HVP_hardwareId 0;
BA_ "Confidence" SG_ 2029 HVP_componentId 0;
BA_ "Confidence" SG_ 2029 HVP_pcbaId 0;
BA_ "Confidence" SG_ 2029 HVP_assemblyId 0;
BA_ "Confidence" SG_ 2029 HVP_usageId 0;
BA_ "Confidence" SG_ 2029 HVP_subUsageId 0;
BA_ "Confidence" SG_ 2029 HVP_platformType 0;
BA_ "Confidence" SG_ 2029 HVP_appCrc 0;
BA_ "Confidence" SG_ 2029 HVP_appGitHash 0;
BA_ "Confidence" SG_ 2029 HVP_bootGitHash 0;
BA_ "Confidence" SG_ 2029 HVP_bootUdsProtoVersion 0;
BA_ "Confidence" SG_ 2029 HVP_bootCrc 0;
BA_ "Confidence" SG_ 1914 HVP_log1HzIndex 1;
BA_ "Confidence" SG_ 1914 HVP_bmbAsicType 0;
BA_ "Confidence" SG_ 1914 HVP_shuntCurrentAuxLog 0;
BA_ "Confidence" SG_ 1914 HVP_pyroSquibResistance 0;
BA_ "GenSigSNA" SG_ 1914 HVP_pyroSquibResistance "65535";
BA_ "Confidence" SG_ 1914 HVP_shuntAsicChipXCoordinate 0;
BA_ "Confidence" SG_ 1914 HVP_shuntAsicChipYCoordinate 0;
BA_ "Confidence" SG_ 1914 HVP_hvilCalType 0;
BA_ "Confidence" SG_ 1914 HVP_gpioPcsDcdcPwmEnable 0;
BA_ "Confidence" SG_ 1914 HVP_gpioPcsChargePwmEnable 0;
BA_ "Confidence" SG_ 1914 HVP_gpioPcsEnable 0;
BA_ "Confidence" SG_ 1914 HVP_shuntAsicChipWaferNumber 0;
BA_ "Confidence" SG_ 1914 HVP_energyReserveMin 0;
BA_ "Confidence" SG_ 1914 HVP_energyReserveMax 0;
BA_ "Confidence" SG_ 1914 HVP_energyReserveAvg 0;
BA_ "Confidence" SG_ 1553 HVP_udsResponseData 1;
BA_ "Confidence" SG_ 861 IBST_matrixIndex 1;
BA_ "SystemSignalLongSymbol" SG_ 861 IBST_a182_DIchassisControlTimeou "IBST_a182_DIchassisControlTimeout";
BA_ "SystemSignalLongSymbol" SG_ 861 IBST_a183_DIchassisControlChecks "IBST_a183_DIchassisControlChecksum";
BA_ "SystemSignalLongSymbol" SG_ 861 IBST_a184_DIchassisControlCounte "IBST_a184_DIchassisControlCounter";
BA_ "SystemSignalLongSymbol" SG_ 861 IBST_a189_rightVCLVPowerStateTim "IBST_a189_rightVCLVPowerStateTimeout";
BA_ "SystemSignalLongSymbol" SG_ 861 IBST_a191_rightVCLVPowerStateChe "IBST_a191_rightVCLVPowerStateChecksum";
BA_ "SystemSignalLongSymbol" SG_ 861 IBST_a192_rightVCLVPowerStateCou "IBST_a192_rightVCLVPowerStateCounter";
BA_ "SystemSignalLongSymbol" SG_ 861 IBST_a193_leftVCLVPowerStateTime "IBST_a193_leftVCLVPowerStateTimeout";
BA_ "SystemSignalLongSymbol" SG_ 861 IBST_a194_leftVCLVPowerStateChec "IBST_a194_leftVCLVPowerStateChecksum";
BA_ "SystemSignalLongSymbol" SG_ 861 IBST_a196_leftVCLVPowerStateCoun "IBST_a196_leftVCLVPowerStateCounter";
BA_ "SystemSignalLongSymbol" SG_ 861 IBST_a197_brakeLatencyReductionA "IBST_a197_brakeLatencyReductionActive";
BA_ "SystemSignalLongSymbol" SG_ 861 IBST_a201_EGGREAR1wheelSpeedsRea "IBST_a201_EGGREAR1wheelSpeedsRearTimeOut";
BA_ "SystemSignalLongSymbol" SG_ 861 IBST_a202_EGGREAR1wheelSpeedsRea "IBST_a202_EGGREAR1wheelSpeedsRearChecksum";
BA_ "SystemSignalLongSymbol" SG_ 861 IBST_a203_EGGREAR1wheelSpeedsRea "IBST_a203_EGGREAR1wheelSpeedsRearDLC";
BA_ "SystemSignalLongSymbol" SG_ 861 IBST_a204_EGGREAR1wheelSpeedsRea "IBST_a204_EGGREAR1wheelSpeedsRearCounter";
BA_ "SystemSignalLongSymbol" SG_ 861 IBST_a205_EGGRIGHT1wheelSpeedsFr "IBST_a205_EGGRIGHT1wheelSpeedsFrontTimeOut";
BA_ "SystemSignalLongSymbol" SG_ 861 IBST_a206_EGGRIGHT1wheelSpeedsFr "IBST_a206_EGGRIGHT1wheelSpeedsFrontChecksum";
BA_ "SystemSignalLongSymbol" SG_ 861 IBST_a207_EGGRIGHT1wheelSpeedsFr "IBST_a207_EGGRIGHT1wheelSpeedsFrontDLC";
BA_ "SystemSignalLongSymbol" SG_ 861 IBST_a208_EGGRIGHT1wheelSpeedsFr "IBST_a208_EGGRIGHT1wheelSpeedsFrontCounter";
BA_ "SystemSignalLongSymbol" SG_ 861 IBST_a209_reducedBrakePowerActiv "IBST_a209_reducedBrakePowerActive";
BA_ "SystemSignalLongSymbol" SG_ 861 IBST_a210_reducedBrakePowerNotAv "IBST_a210_reducedBrakePowerNotAvailable";
BA_ "SystemSignalLongSymbol" SG_ 861 IBST_a212_infoFailureWrongCUBASH "IBST_a212_infoFailureWrongCUBASHandlingDetected";
BA_ "SystemSignalLongSymbol" SG_ 861 IBST_a213_PDURouterinitializatio "IBST_a213_PDURouterinitializationFailed";
BA_ "SystemSignalLongSymbol" SG_ 861 IBST_a214_LossOfPDUInstanceDetec "IBST_a214_LossOfPDUInstanceDetected";
BA_ "SystemSignalLongSymbol" SG_ 861 IBST_a215_UnsupportedSeriesHWDet "IBST_a215_UnsupportedSeriesHWDetected";
BA_ "SystemSignalLongSymbol" SG_ 861 IBST_a216_AsicMalfunctionDetecte "IBST_a216_AsicMalfunctionDetected";
BA_ "SystemSignalLongSymbol" SG_ 861 IBST_a217_AsicTrimmingNotComplet "IBST_a217_AsicTrimmingNotCompleted";
BA_ "SystemSignalLongSymbol" SG_ 861 IBST_a218_uCSafetyNotificationGR "IBST_a218_uCSafetyNotificationGRAM";
BA_ "SystemSignalLongSymbol" SG_ 861 IBST_a220_ASICOvercurrentOnGPIO2 "IBST_a220_ASICOvercurrentOnGPIO250_2";
BA_ "SystemSignalLongSymbol" SG_ 861 IBST_a221_ASICOvercurrentOnGPIO2 "IBST_a221_ASICOvercurrentOnGPIO250_1";
BA_ "SystemSignalLongSymbol" SG_ 861 IBST_a222_ASICOvercurrentOnGPIO5 "IBST_a222_ASICOvercurrentOnGPIO50_4";
BA_ "SystemSignalLongSymbol" SG_ 861 IBST_a223_ASICOvercurrentOnGPIO5 "IBST_a223_ASICOvercurrentOnGPIO50_3";
BA_ "SystemSignalLongSymbol" SG_ 861 IBST_a224_ASICOvercurrentOnGPIO5 "IBST_a224_ASICOvercurrentOnGPIO50_2";
BA_ "SystemSignalLongSymbol" SG_ 861 IBST_a225_ASICOvercurrentOnGPIO5 "IBST_a225_ASICOvercurrentOnGPIO50_1";
BA_ "SystemSignalLongSymbol" SG_ 861 IBST_a227_wakeRequestMismatchDet "IBST_a227_wakeRequestMismatchDetected";
BA_ "SystemSignalLongSymbol" SG_ 861 IBST_a228_BlockedPedalDetectedDu "IBST_a228_BlockedPedalDetectedDuringHAD";
BA_ "SystemSignalLongSymbol" SG_ 861 IBST_a232_PostAssemblyRoutineFai "IBST_a232_PostAssemblyRoutineFailed";
BA_ "SystemSignalLongSymbol" SG_ 861 IBST_a233_ReferenceRunAbortByECU "IBST_a233_ReferenceRunAbortByECUReset";
BA_ "SystemSignalLongSymbol" SG_ 861 IBST_a246_DASredundantBrakingCon "IBST_a246_DASredundantBrakingControlPartyChecksum";
BA_ "SystemSignalLongSymbol" SG_ 861 IBST_a247_DASredundantBrakingCon "IBST_a247_DASredundantBrakingControlPartyCounter";
BA_ "SystemSignalLongSymbol" SG_ 861 IBST_a248_DASredundantBrakingCon "IBST_a248_DASredundantBrakingControlPartyDLC";
BA_ "SystemSignalLongSymbol" SG_ 861 IBST_a249_DASredundantBrakingCon "IBST_a249_DASredundantBrakingControlPartyTimeout";
BA_ "SystemSignalLongSymbol" SG_ 861 IBST_a250_DASredundantBrakingCon "IBST_a250_DASredundantBrakingControlChassisChecksum";
BA_ "SystemSignalLongSymbol" SG_ 861 IBST_a251_DASredundantBrakingCon "IBST_a251_DASredundantBrakingControlChassisCounter";
BA_ "SystemSignalLongSymbol" SG_ 861 IBST_a252_DASredundantBrakingCon "IBST_a252_DASredundantBrakingControlChassisDLC";
BA_ "SystemSignalLongSymbol" SG_ 861 IBST_a253_DASredundantBrakingCon "IBST_a253_DASredundantBrakingControlChassisTimeout";
BA_ "Confidence" SG_ 813 IBST_infoIndex 1;
BA_ "Confidence" SG_ 813 IBST_infoBuildType 0;
BA_ "Confidence" SG_ 813 IBST_infoPcbaID 0;
BA_ "Confidence" SG_ 813 IBST_infoAssemblyID 0;
BA_ "Confidence" SG_ 813 IBST_infoUsageID 0;
BA_ "Confidence" SG_ 813 IBST_infoSubUsageID 0;
BA_ "Confidence" SG_ 813 IBST_infoApplicationCRC 0;
BA_ "Confidence" SG_ 813 IBST_infoBootUdsProtoVersion 0;
BA_ "Confidence" SG_ 813 IBST_infoBootloaderCRC 0;
BA_ "Confidence" SG_ 813 IBST_infoVariantCRC 0;
BA_ "Confidence" SG_ 925 IBST_statusChecksum 0;
BA_ "Confidence" SG_ 925 IBST_statusCounter 0;
BA_ "Confidence" SG_ 925 IBST_iBoosterStatus 0;
BA_ "Confidence" SG_ 925 IBST_driverBrakeApply 0;
BA_ "Confidence" SG_ 925 IBST_internalState 0;
BA_ "Confidence" SG_ 925 IBST_sInputRodDriver 0;
BA_ "Confidence" SG_ 925 IBST_LVPowerModeState 0;
BA_ "Confidence" SG_ 1629 IBST_udsResponseData 1;
BA_ "Confidence" SG_ 1208 ICR_alertID 1;
BA_ "Confidence" SG_ 1208 ICR_alertState 1;
BA_ "SystemSignalLongSymbol" SG_ 1208 ICR_a001_watchdogTaskSentinelInt "ICR_a001_watchdogTaskSentinelInterface";
BA_ "SystemSignalLongSymbol" SG_ 1208 ICR_a001_watchdogTaskSentinelMod "ICR_a001_watchdogTaskSentinelModeChange";
BA_ "Confidence" SG_ 1208 ICR_a059_voltageDrop 1;
BA_ "Confidence" SG_ 1208 ICR_a059_resistanceEstimate 1;
BA_ "Confidence" SG_ 1208 ICR_a059_current 1;
BA_ "Confidence" SG_ 1208 ICR_a063_ADCVoltage 1;
BA_ "Confidence" SG_ 1208 ICR_a133_nearClutter 1;
BA_ "Confidence" SG_ 1208 ICR_a133_farClutter 1;
BA_ "Confidence" SG_ 1208 ICR_a137_nearClutter 1;
BA_ "Confidence" SG_ 1208 ICR_a137_farClutter 1;
BA_ "Confidence" SG_ 1208 ICR_a139_nearClutter 1;
BA_ "Confidence" SG_ 1208 ICR_a139_farClutter 1;
BA_ "SystemSignalLongSymbol" SG_ 1208 ICR_a141_calDataNotCalibratedOrP "ICR_a141_calDataNotCalibratedOrProcessing";
BA_ "SystemSignalLongSymbol" SG_ 1208 ICR_a141_calDataValRXPhaseAboveM "ICR_a141_calDataValRXPhaseAboveMax";
BA_ "SystemSignalLongSymbol" SG_ 1208 ICR_a141_calDataValRXPhaseMissin "ICR_a141_calDataValRXPhaseMissingUnitMag";
BA_ "SystemSignalLongSymbol" SG_ 1208 ICR_a141_calDataValRangeBiasAbov "ICR_a141_calDataValRangeBiasAboveMax";
BA_ "Confidence" SG_ 2028 ICR_matrixIndex 1;
BA_ "SystemSignalLongSymbol" SG_ 2028 ICR_a139_AbnormalBlockageDetecte "ICR_a139_AbnormalBlockageDetected";
BA_ "SystemSignalLongSymbol" SG_ 2028 ICR_a140_OccupancyExceptionEncou "ICR_a140_OccupancyExceptionEncountered";
BA_ "SystemSignalLongSymbol" SG_ 2028 ICR_a144_OccupancyNotificationAl "ICR_a144_OccupancyNotificationAlert";
BA_ "Confidence" SG_ 941 ICR_infoIndex 1;
BA_ "Confidence" SG_ 941 ICR_infoBuildType 0;
BA_ "Confidence" SG_ 941 ICR_infoPcbaId 0;
BA_ "Confidence" SG_ 941 ICR_infoAssemblyId 0;
BA_ "Confidence" SG_ 941 ICR_infoUsageId 0;
BA_ "Confidence" SG_ 941 ICR_infoAppCrc 0;
BA_ "Confidence" SG_ 941 ICR_infoBoardPartNumber17 0;
BA_ "Confidence" SG_ 941 ICR_infoBoardPartNumber814 0;
BA_ "Confidence" SG_ 941 ICR_infoBoardPartNumber1520 0;
BA_ "Confidence" SG_ 667 ICR_lifePresenceMLOutput 0;
BA_ "GenSigSNA" SG_ 667 ICR_lifePresenceMLOutput "255";
BA_ "Confidence" SG_ 667 ICR_largeOccupantPresenceMLOutpu 0;
BA_ "GenSigSNA" SG_ 667 ICR_largeOccupantPresenceMLOutpu "255";
BA_ "SystemSignalLongSymbol" SG_ 667 ICR_largeOccupantPresenceMLOutpu "ICR_largeOccupantPresenceMLOutput";
BA_ "Confidence" SG_ 667 ICR_lifePresenceRaw 0;
BA_ "GenSigSNA" SG_ 667 ICR_lifePresenceRaw "0";
BA_ "Confidence" SG_ 667 ICR_lifePresenceFilt 0;
BA_ "GenSigSNA" SG_ 667 ICR_lifePresenceFilt "0";
BA_ "Confidence" SG_ 667 ICR_largeOccupantPresenceRaw 0;
BA_ "GenSigSNA" SG_ 667 ICR_largeOccupantPresenceRaw "3";
BA_ "Confidence" SG_ 667 ICR_largeOccupantPresenceFilt 0;
BA_ "GenSigSNA" SG_ 667 ICR_largeOccupantPresenceFilt "3";
BA_ "Confidence" SG_ 667 ICR_childPresenceFunctionality 0;
BA_ "GenSigSNA" SG_ 667 ICR_childPresenceFunctionality "2";
BA_ "Confidence" SG_ 667 ICR_userPresenceFunctionality 0;
BA_ "GenSigSNA" SG_ 667 ICR_userPresenceFunctionality "2";
BA_ "Confidence" SG_ 667 ICR_userPresenceMLOutput 0;
BA_ "GenSigSNA" SG_ 667 ICR_userPresenceMLOutput "255";
BA_ "Confidence" SG_ 667 ICR_userPresenceRaw 0;
BA_ "GenSigSNA" SG_ 667 ICR_userPresenceRaw "3";
BA_ "Confidence" SG_ 667 ICR_userPresenceFilt 0;
BA_ "GenSigSNA" SG_ 667 ICR_userPresenceFilt "3";
BA_ "Confidence" SG_ 2027 ICR_occupancy1LRaw 0;
BA_ "GenSigSNA" SG_ 2027 ICR_occupancy1LRaw "3";
BA_ "Confidence" SG_ 2027 ICR_occupancy1RRaw 0;
BA_ "GenSigSNA" SG_ 2027 ICR_occupancy1RRaw "3";
BA_ "Confidence" SG_ 2027 ICR_occupancy1LVoteCnt 0;
BA_ "Confidence" SG_ 2027 ICR_occupancy1RVoteCnt 0;
BA_ "Confidence" SG_ 2027 ICR_occupancy1LFilt 0;
BA_ "GenSigSNA" SG_ 2027 ICR_occupancy1LFilt "3";
BA_ "Confidence" SG_ 2027 ICR_occupancy1RFilt 0;
BA_ "GenSigSNA" SG_ 2027 ICR_occupancy1RFilt "3";
BA_ "Confidence" SG_ 2027 ICR_occupancy2LFilt 0;
BA_ "GenSigSNA" SG_ 2027 ICR_occupancy2LFilt "3";
BA_ "Confidence" SG_ 2027 ICR_occupancy2CFilt 0;
BA_ "GenSigSNA" SG_ 2027 ICR_occupancy2CFilt "3";
BA_ "Confidence" SG_ 2027 ICR_occupancy2RFilt 0;
BA_ "GenSigSNA" SG_ 2027 ICR_occupancy2RFilt "3";
BA_ "Confidence" SG_ 2027 ICR_occupancy1RFiltExp 0;
BA_ "GenSigSNA" SG_ 2027 ICR_occupancy1RFiltExp "3";
BA_ "Confidence" SG_ 2027 ICR_occupancyCounter 0;
BA_ "Confidence" SG_ 2027 ICR_occupancyChecksum 0;
BA_ "Confidence" SG_ 670 ICR_classification1RFilt 0;
BA_ "GenSigSNA" SG_ 670 ICR_classification1RFilt "0";
BA_ "Confidence" SG_ 670 ICR_classification1LRaw 0;
BA_ "GenSigSNA" SG_ 670 ICR_classification1LRaw "0";
BA_ "Confidence" SG_ 670 ICR_classification1RRaw 0;
BA_ "GenSigSNA" SG_ 670 ICR_classification1RRaw "0";
BA_ "Confidence" SG_ 670 ICR_classification1LMLOutput 0;
BA_ "GenSigSNA" SG_ 670 ICR_classification1LMLOutput "255";
BA_ "Confidence" SG_ 670 ICR_classification1RMLOutput 0;
BA_ "GenSigSNA" SG_ 670 ICR_classification1RMLOutput "255";
BA_ "Confidence" SG_ 670 ICR_classification1LqF 0;
BA_ "Confidence" SG_ 670 ICR_blockageClutterFar 0;
BA_ "GenSigSNA" SG_ 670 ICR_blockageClutterFar "16";
BA_ "Confidence" SG_ 670 ICR_blockageClutterNear 0;
BA_ "GenSigSNA" SG_ 670 ICR_blockageClutterNear "16";
BA_ "Confidence" SG_ 670 ICR_classification1LFilt 0;
BA_ "GenSigSNA" SG_ 670 ICR_classification1LFilt "0";
BA_ "Confidence" SG_ 670 ICR_classification1RqF 0;
BA_ "Confidence" SG_ 670 ICR_classification1LLatched 0;
BA_ "GenSigSNA" SG_ 670 ICR_classification1LLatched "0";
BA_ "Confidence" SG_ 670 ICR_classification1RLatched 0;
BA_ "GenSigSNA" SG_ 670 ICR_classification1RLatched "0";
BA_ "Confidence" SG_ 670 ICR_classification1LIsLatched 0;
BA_ "Confidence" SG_ 670 ICR_classification1RIsLatched 0;
BA_ "Confidence" SG_ 670 ICR_occupancy2Counter 0;
BA_ "Confidence" SG_ 670 ICR_occupancy2Checksum 0;
BA_ "Confidence" SG_ 2025 ICR_sensorMode 0;
BA_ "Confidence" SG_ 2025 ICR_blocked 0;
BA_ "GenSigSNA" SG_ 2025 ICR_blocked "0";
BA_ "Confidence" SG_ 2025 ICR_booted 0;
BA_ "Confidence" SG_ 2025 ICR_rdMapDumpCompleted 0;
BA_ "Confidence" SG_ 2025 ICR_algoVersion 0;
BA_ "Confidence" SG_ 2025 ICR_l2HeapUsage 0;
BA_ "Confidence" SG_ 2025 ICR_intrusionStatus 0;
BA_ "Confidence" SG_ 2025 ICR_blockageScaledMLOutput 0;
BA_ "Confidence" SG_ 1624 ICR_udsResponseData 1;
VAL_ 1290 HVP_alertID 71 "a071_PassivePyroVrefRationality" 70 "a070_hvsCanFrameRxDropped" 69 "a069_hviCanFrameRxDropped" 68 "a068_shuntUnexpectedThermistor" 67 "a067_HvilCalNodeMismatch" 65 "a065_FastOpenVshDetected" 64 "a064_BmbAuxVRationality" 63 "a063_BmbBrickVRationality" 62 "a062_BmbOtpConfigError" 61 "a061_ShuntCurrentRationality" 60 "a060_StackVoltageSense" 59 "a059_BmbVrefWarning" 58 "a058_BmbVrefBad" 57 "a057_BatmanDiagnosticsError" 56 "a056_contactorFailedToOpen" 55 "a055_swMissingPartNumber" 54 "a054_swMissingConfigBlock" 53 "a053_hvVoltageSensorRationality" 52 "a052_BmbStatusRegError" 51 "a051_shuntThermistorMia" 50 "a050_fcCtrCloseFailed" 49 "a049_packCtrCloseFailed" 48 "a048_swUnsupportedBmbAsicType" 47 "a047_passivePyroDeploy" 46 "a046_shuntOverTemperature" 45 "a045_dcLinkOverVoltage" 44 "a044_fcContactorForceOpen" 43 "a043_packContactorForceOpen" 42 "a042_fcCtrCloseBlocked" 41 "a041_packCtrCloseBlocked" 40 "a040_FcContactorFellOpen" 39 "a039_PackContactorFellOpen" 38 "a038_CpilFault" 37 "a037_pyroFuseFailedToBlow" 36 "a036_pyroFuseBlown" 35 "a035_packContHwFault" 34 "a034_cpMismatchFault" 33 "a033_fcContHwFault" 32 "a032_ShuntHwAndBmsMiaFault" 31 "a031_packNegCtrArcFault" 30 "a030_PackPosCtrArcFault" 29 "a029_EnsMiaFault" 28 "a028_PackVoltMismatchFault" 27 "a027_BmsMiaOnHvsFault" 26 "a026_HvilFault" 25 "a025_VerSupplyFault" 24 "a024_Supply12vFault" 23 "a023_BmbResetRecovery" 22 "a022_PyroMiaWarning" 21 "a021_PyroMiaFault" 20 "a020_ShuntHwMiaFault" 19 "a019_CpFault" 18 "a018_powerCyclingPcs" 17 "a017_GtwMiaFault" 16 "a016_PcsMiaFault" 15 "a015_CpMiaFault" 14 "a014_BmsMiaOnHviFault" 13 "a013_BmbCommunication" 12 "a012_BmbDataIntegrityLoss" 11 "a011_PrimaryBmbMiaFault" 10 "a010_UnderVoltageFault" 9 "a009_OverVoltageFault" 8 "a008_OverTemperatureFault" 7 "a007_OverCurrentFault" 6 "a006_OverChargeCurrentFault" 5 "a005_OverDchgCurrentFault" 4 "a004_CrashEvent" 3 "a003_SwAssertion" 2 "a002_UnusedAlert2" 1 "a001_WatchdogReset" 0 "ALERT_DO_NOT_USE_ZERO" ;
VAL_ 1290 HVP_alertSet 1 "SET" 0 "CLEARED" ;
VAL_ 1290 HVP_a012_bmbCommStatusTypeA 3 "BYPASSED" 2 "NOMINAL" 1 "BAD" 0 "MISSING" ;
VAL_ 1290 HVP_a012_bmbCommStatusTypeB 3 "BYPASSED" 2 "NOMINAL" 1 "BAD" 0 "MISSING" ;
VAL_ 1290 HVP_a013_bmbCommStatusTypeA 3 "BYPASSED" 2 "NOMINAL" 1 "BAD" 0 "MISSING" ;
VAL_ 1290 HVP_a013_bmbCommStatusTypeB 3 "BYPASSED" 2 "NOMINAL" 1 "BAD" 0 "MISSING" ;
VAL_ 1290 HVP_a013_bmbChainBreakType 5 "TAIL_BREAK" 4 "HEAD_BREAK" 3 "INVALID_BREAK" 2 "DOUBLE_BREAK" 1 "SINGLE_BREAK" 0 "NONE" ;
VAL_ 1290 HVP_a020_energyReserveV 65535 "SNA" ;
VAL_ 1290 HVP_a020_shuntCurrentAux -32768 "SNA" ;
VAL_ 1290 HVP_a020_shuntTemperature -32768 "SNA" ;
VAL_ 1290 HVP_a021_pyroStatus 3 "ACTIVATED" 2 "FAULT" 1 "OK" 0 "UNKNOWN" ;
VAL_ 1290 HVP_a021_SquibResistance 65535 "SNA" ;
VAL_ 1290 HVP_a021_Aout 16383 "SNA" ;
VAL_ 1290 HVP_a022_pyroStatus 3 "ACTIVATED" 2 "FAULT" 1 "OK" 0 "UNKNOWN" ;
VAL_ 1290 HVP_a022_Aout 16383 "SNA" ;
VAL_ 1290 HVP_a022_SquibResistance 65535 "SNA" ;
VAL_ 1290 HVP_a026_hvilStatus 14 "SNA" 13 "PM_OPEN_FAULT" 12 "DI_OPEN_FAULT" 11 "PM_STATUS_MISSING_FAULT" 10 "DI_STATUS_MISSING_FAULT" 9 "VEHICLE_OR_PENTHOUSE_LID_OPEN_FAULT" 8 "NO_12V_SUPPLY" 7 "VEHICLE_NODE_FAULT" 6 "UNKNOWN_LOCATION_OPEN_FAULT" 5 "PENTHOUSE_LID_OPEN_FAULT" 4 "VEHICLE_OPEN_FAULT" 3 "INTERNAL_OPEN_FAULT" 2 "CURRENT_SOURCE_OR_GROUND_LEAK_FAULT" 1 "OK" 0 "UNKNOWN" ;
VAL_ 1290 HVP_a026_internalVoltage 255 "SNA" ;
VAL_ 1290 HVP_a026_dirVoltage 255 "SNA" ;
VAL_ 1290 HVP_a026_difVoltage 255 "SNA" ;
VAL_ 1290 HVP_a036_pyroFiringHandle 12 "PACK_NEGATIVE_CTR_ARC" 11 "PACK_POSITIVE_CTR_ARC" 10 "ENS_CRASH" 9 "SHUNT_MIA" 8 "OPEN_IMMEDIATELY" 7 "TEMPERATURE" 6 "UNDER_VOLTAGE" 5 "OVER_VOLTAGE" 4 "OVER_CURRENT" 3 "OVER_CHARGE_CURRENT" 2 "OVER_DISCHARGE_CURRENT" 1 "HVP" ;
VAL_ 1290 HVP_a037_pyroFiringHandle 12 "PACK_NEGATIVE_CTR_ARC" 11 "PACK_POSITIVE_CTR_ARC" 10 "ENS_CRASH" 9 "SHUNT_MIA" 8 "OPEN_IMMEDIATELY" 7 "TEMPERATURE" 6 "UNDER_VOLTAGE" 5 "OVER_VOLTAGE" 4 "OVER_CURRENT" 3 "OVER_CHARGE_CURRENT" 2 "OVER_DISCHARGE_CURRENT" 1 "HVP" ;
VAL_ 1290 HVP_a049_posCtrState 7 "WELDED" 6 "ECONOMIZED" 5 "OPENING" 4 "PULLED_IN" 3 "BLOCKED" 2 "PRECHARGE" 1 "OPEN" 0 "SNA" ;
VAL_ 1290 HVP_a049_negCtrState 7 "WELDED" 6 "ECONOMIZED" 5 "OPENING" 4 "PULLED_IN" 3 "BLOCKED" 2 "PRECHARGE" 1 "OPEN" 0 "SNA" ;
VAL_ 1290 HVP_a050_posCtrState 7 "WELDED" 6 "ECONOMIZED" 5 "OPENING" 4 "PULLED_IN" 3 "BLOCKED" 2 "PRECHARGE" 1 "OPEN" 0 "SNA" ;
VAL_ 1290 HVP_a050_negCtrState 7 "WELDED" 6 "ECONOMIZED" 5 "OPENING" 4 "PULLED_IN" 3 "BLOCKED" 2 "PRECHARGE" 1 "OPEN" 0 "SNA" ;
VAL_ 1290 HVP_a051_shuntTemperature -32768 "SNA" ;
VAL_ 1290 HVP_a051_shuntCurrent -32768 "SNA" ;
VAL_ 1290 HVP_a051_energyReserveV 65535 "SNA" ;
VAL_ 1290 HVP_a056_diagnosis 2 "PACK_CONTACTOR_WELDED" 1 "HIGH_SHUNT_CURRENT" 0 "SHUNT_CURRENT_SNA" ;
VAL_ 1290 HVP_a056_posPackContactorState 7 "WELDED" 6 "ECONOMIZED" 5 "OPENING" 4 "PULLED_IN" 3 "BLOCKED" 2 "PRECHARGE" 1 "OPEN" 0 "SNA" ;
VAL_ 1290 HVP_a056_negPackContactorState 7 "WELDED" 6 "ECONOMIZED" 5 "OPENING" 4 "PULLED_IN" 3 "BLOCKED" 2 "PRECHARGE" 1 "OPEN" 0 "SNA" ;
VAL_ 1290 HVP_a056_posFcContactorState 7 "WELDED" 6 "ECONOMIZED" 5 "OPENING" 4 "PULLED_IN" 3 "BLOCKED" 2 "PRECHARGE" 1 "OPEN" 0 "SNA" ;
VAL_ 1290 HVP_a056_negFcContactorState 7 "WELDED" 6 "ECONOMIZED" 5 "OPENING" 4 "PULLED_IN" 3 "BLOCKED" 2 "PRECHARGE" 1 "OPEN" 0 "SNA" ;
VAL_ 1290 HVP_a058_VrefStatus 3 "BYPASSED" 2 "NOMINAL" 1 "BAD" 0 "MISSING" ;
VAL_ 1290 HVP_a058_VrefType 2 "REF2" 1 "V3" 0 "V5" ;
VAL_ 1290 HVP_a067_hvilTypeFromHvp 2 "CAN" 1 "LV" 0 "UNKNOWN" ;
VAL_ 1290 HVP_a067_hvilTypeFromGateway 2 "CAN" 1 "LV" 0 "UNKNOWN" ;
VAL_ 1290 HVP_a068_shuntTemperature -32768 "SNA" ;
VAL_ 1290 HVP_a068_shuntCurrent -32768 "SNA" ;
VAL_ 1290 HVP_a068_energyReserveV 65535 "SNA" ;
VAL_ 938 HVP_matrixIndex 1 "AlertMatrix1" 0 "AlertMatrix0" ;
VAL_ 522 HVP_packContNegativeState 7 "CONTACTOR_STATE_WELDED" 6 "CONTACTOR_STATE_ECONOMIZED" 5 "CONTACTOR_STATE_OPENING" 4 "CONTACTOR_STATE_PULLED_IN" 3 "CONTACTOR_STATE_BLOCKED" 2 "CONTACTOR_STATE_PRECHARGE" 1 "CONTACTOR_STATE_OPEN" 0 "CONTACTOR_STATE_SNA" ;
VAL_ 522 HVP_packContPositiveState 7 "CONTACTOR_STATE_WELDED" 6 "CONTACTOR_STATE_ECONOMIZED" 5 "CONTACTOR_STATE_OPENING" 4 "CONTACTOR_STATE_PULLED_IN" 3 "CONTACTOR_STATE_BLOCKED" 2 "CONTACTOR_STATE_PRECHARGE" 1 "CONTACTOR_STATE_OPEN" 0 "CONTACTOR_STATE_SNA" ;
VAL_ 522 HVP_packContactorSetState 9 "CONTACTOR_SET_STATE_NEGATIVE_CLOSED" 8 "CONTACTOR_SET_STATE_POSITIVE_CLOSED" 7 "CONTACTOR_SET_STATE_WELDED" 6 "CONTACTOR_SET_STATE_PARTIAL_WELD" 5 "CONTACTOR_SET_STATE_CLOSED" 4 "CONTACTOR_SET_STATE_OPENING" 3 "CONTACTOR_SET_STATE_BLOCKED" 2 "CONTACTOR_SET_STATE_CLOSING" 1 "CONTACTOR_SET_STATE_OPEN" 0 "CONTACTOR_SET_STATE_SNA" ;
VAL_ 522 HVP_fcContNegativeState 7 "CONTACTOR_STATE_WELDED" 6 "CONTACTOR_STATE_ECONOMIZED" 5 "CONTACTOR_STATE_OPENING" 4 "CONTACTOR_STATE_PULLED_IN" 3 "CONTACTOR_STATE_BLOCKED" 2 "CONTACTOR_STATE_PRECHARGE" 1 "CONTACTOR_STATE_OPEN" 0 "CONTACTOR_STATE_SNA" ;
VAL_ 522 HVP_fcContPositiveState 7 "CONTACTOR_STATE_WELDED" 6 "CONTACTOR_STATE_ECONOMIZED" 5 "CONTACTOR_STATE_OPENING" 4 "CONTACTOR_STATE_PULLED_IN" 3 "CONTACTOR_STATE_BLOCKED" 2 "CONTACTOR_STATE_PRECHARGE" 1 "CONTACTOR_STATE_OPEN" 0 "CONTACTOR_STATE_SNA" ;
VAL_ 522 HVP_fcContactorSetState 9 "CONTACTOR_SET_STATE_NEGATIVE_CLOSED" 8 "CONTACTOR_SET_STATE_POSITIVE_CLOSED" 7 "CONTACTOR_SET_STATE_WELDED" 6 "CONTACTOR_SET_STATE_PARTIAL_WELD" 5 "CONTACTOR_SET_STATE_CLOSED" 4 "CONTACTOR_SET_STATE_OPENING" 3 "CONTACTOR_SET_STATE_BLOCKED" 2 "CONTACTOR_SET_STATE_CLOSING" 1 "CONTACTOR_SET_STATE_OPEN" 0 "CONTACTOR_SET_STATE_SNA" ;
VAL_ 522 HVP_fcCtrsRequestStatus 2 "REQUEST_COMPLETED" 1 "REQUEST_ACTIVE" 0 "REQUEST_NOT_ACTIVE" ;
VAL_ 522 HVP_packCtrsRequestStatus 2 "REQUEST_COMPLETED" 1 "REQUEST_ACTIVE" 0 "REQUEST_NOT_ACTIVE" ;
VAL_ 522 HVP_hvilDiag 14 "SNA" 13 "PM_OPEN_FAULT" 12 "DI_OPEN_FAULT" 11 "PM_STATUS_MISSING_FAULT" 10 "DI_STATUS_MISSING_FAULT" 9 "VEHICLE_OR_PENTHOUSE_LID_OPEN_FAULT" 8 "NO_12V_SUPPLY" 7 "VEHICLE_NODE_FAULT" 6 "UNKNOWN_LOCATION_OPEN_FAULT" 5 "PENTHOUSE_LID_OPEN_FAULT" 4 "VEHICLE_OPEN_FAULT" 3 "INTERNAL_OPEN_FAULT" 2 "CURRENT_SOURCE_OR_GROUND_LEAK_FAULT" 1 "OK" 0 "UNKNOWN" ;
VAL_ 522 HVP_fcLinkAllowedToEnergize 2 "FC_LINK_ENERGY_DC" 1 "FC_LINK_ENERGY_AC" 0 "FC_LINK_ENERGY_NONE" ;
VAL_ 1962 HVP_debugMessageMultiplexer 12 "Mux12" 11 "Mux11" 10 "Mux10" 9 "Mux9" 8 "Mux8" 7 "Mux7" 6 "Mux6" 5 "Mux5" 4 "Mux4" 3 "Mux3" 2 "Mux2" 1 "Mux1" 0 "Mux0" ;
VAL_ 1962 HVP_ecuLogUploadRequest 3 "REQUEST_PRIORITY_3" 2 "REQUEST_PRIORITY_2" 1 "REQUEST_PRIORITY_1" 0 "REQUEST_PRIORITY_NONE" ;
VAL_ 1962 HVP_passivePyroRefVoltageMax 1023 "SNA" ;
VAL_ 1962 HVP_passivePyroRefVoltageMin 1023 "SNA" ;
VAL_ 1666 HVP_hvilStatus 2 "FAULT" 1 "OK" 0 "UNKNOWN" ;
VAL_ 554 HVP_pcsControlRequest 3 "DISCHARGE" 2 "PRECHARGE" 1 "SUPPORT" 0 "SHUTDOWN" ;
VAL_ 554 HVP_dcLinkVoltageFiltered -550 "SNA" ;
VAL_ 2029 HVP_infoIndex 255 "END" 31 "SUBCOMPONENT_GITHASH" 30 "PACKAGE_SN_8_14" 29 "PACKAGE_SN_1_7" 27 "PACKAGE_PN_15_20" 26 "PACKAGE_PN_8_14" 25 "PACKAGE_PN_1_7" 23 "SUBCOMPONENT2" 22 "VARIANTCRC" 20 "UDS_PROTOCOL_BOOTCRC" 19 "VERSION_DEPRECATED" 18 "BOOTLOADER_GITHASH" 17 "APP_GITHASH" 16 "SUBCOMPONENT" 15 "BOOTLOADER_CRC" 14 "BOOTLOADER_SVN" 13 "APP_CRC" 11 "PCBAID_ASSYID_USAGEID" 10 "BUILD_HWID_COMPONENTID" 9 "DEPRECATED_9" 8 "DEPRECATED_8" 7 "DEPRECATED_7" 6 "DEPRECATED_6" 5 "DEPRECATED_5" 4 "DEPRECATED_4" 3 "DEPRECATED_3" 2 "DEPRECATED_2" 1 "DEPRECATED_1" 0 "DEPRECATED_0" ;
VAL_ 2029 HVP_buildType 4 "INFO_MFG_BUILD" 3 "INFO_TRACEABLE_CI_BUILD" 2 "INFO_LOCAL_BUILD" 1 "INFO_PLATFORM_BUILD" 0 "INFO_UNKNOWN_BUILD" ;
VAL_ 1914 HVP_log1HzIndex 1 "Mux1" 0 "Mux0" ;
VAL_ 1914 HVP_bmbAsicType 3 "BQ796xx" 2 "ADBMS6830" 1 "LTC831" 0 "UNKNOWN" ;
VAL_ 1914 HVP_shuntCurrentAuxLog 8388000 "PACK_CURRENT_SNA" ;
VAL_ 1914 HVP_pyroSquibResistance 65535 "SNA" ;
VAL_ 1914 HVP_hvilCalType 2 "CAN" 1 "LV" 0 "UNKNOWN" ;
VAL_ 861 IBST_matrixIndex 4 "AlertMatrix4" 3 "AlertMatrix3" 2 "AlertMatrix2" 1 "AlertMatrix1" 0 "AlertMatrix0" ;
VAL_ 813 IBST_infoIndex 255 "END" 31 "SUBCOMPONENT_GITHASH" 30 "PACKAGE_SN_8_14" 29 "PACKAGE_SN_1_7" 27 "PACKAGE_PN_15_20" 26 "PACKAGE_PN_8_14" 25 "PACKAGE_PN_1_7" 23 "SUBCOMPONENT2" 22 "VARIANTCRC" 20 "UDS_PROTOCOL_BOOTCRC" 19 "VERSION_DEPRECATED" 18 "BOOTLOADER_GITHASH" 17 "APP_GITHASH" 16 "SUBCOMPONENT" 15 "BOOTLOADER_CRC" 14 "BOOTLOADER_SVN" 13 "APP_CRC" 11 "PCBAID_ASSYID_USAGEID" 10 "BUILD_HWID_COMPONENTID" 9 "DEPRECATED_9" 8 "DEPRECATED_8" 7 "DEPRECATED_7" 6 "DEPRECATED_6" 5 "DEPRECATED_5" 4 "DEPRECATED_4" 3 "DEPRECATED_3" 2 "DEPRECATED_2" 1 "DEPRECATED_1" 0 "DEPRECATED_0" ;
VAL_ 813 IBST_infoBuildType 4 "INFO_MFG_BUILD" 3 "INFO_TRACEABLE_CI_BUILD" 2 "INFO_LOCAL_BUILD" 1 "INFO_PLATFORM_BUILD" 0 "INFO_UNKNOWN_BUILD" ;
VAL_ 925 IBST_iBoosterStatus 6 "IBOOSTER_ACTUATION" 5 "IBOOSTER_READY" 4 "IBOOSTER_ACTIVE_GOOD_CHECK" 3 "IBOOSTER_DIAGNOSTIC" 2 "IBOOSTER_FAILURE" 1 "IBOOSTER_INIT" 0 "IBOOSTER_OFF" ;
VAL_ 925 IBST_driverBrakeApply 3 "FAULT" 2 "DRIVER_APPLYING_BRAKES" 1 "BRAKES_NOT_APPLIED" 0 "NOT_INIT_OR_OFF" ;
VAL_ 925 IBST_internalState 6 "POST_DRIVE_CHECK" 5 "TRANSITION_TO_IDLE" 4 "DIAGNOSTIC" 3 "EXTERNAL_BRAKE_REQUEST" 2 "LOCAL_BRAKE_REQUEST" 1 "PRE_DRIVE_CHECK" 0 "NO_MODE_ACTIVE" ;
VAL_ 925 IBST_LVPowerModeState 3 "PEAK_POWER_REDUCTION_RESERVED" 2 "PEAK_POWER_REDUCTION_ACTIVE_MAX600W_NOMINAL350W" 1 "PEAK_POWER_REDUCTION_AVAILABLE" 0 "PEAK_POWER_REDUCTION_NOT_SUPPORTED" ;
VAL_ 1208 ICR_alertID 144 "a144_OccupancyNotificationAlert" 143 "a143_DSPCoreSkipped" 142 "a142_ModeOverrideActive" 141 "a141_RequiresReplacement" 140 "a140_OccupancyExceptionEncountered" 139 "a139_AbnormalBlockageDetected" 138 "a138_DriverSideMismatch" 137 "a137_radarBlocked" 136 "a136_radarHighTemperature" 135 "a135_radarTxBallBreak" 134 "a134_radarPgood" 133 "a133_radarBlocked" 64 "a064_busSleepReqTimeout" 63 "a063_SwitchFault" 62 "a062_XCPWasConnected" 61 "a061_XCPConnected" 60 "a060_engineeringBuild" 59 "a059_inputResistanceHigh" 58 "a058_inputRHighSyncDebug" 46 "a046_Task1000msError" 45 "a045_Task100msError" 44 "a044_Task10msError" 43 "a043_Task1msError" 42 "a042_HighStackUsage" 41 "a041_HighCPULoad" 31 "a031_UDSActive" 30 "a030_ECULogUploadRequest" 29 "a029_CoreDump" 22 "a022_TaskInitError" 21 "a021_TaskSchedulerError" 16 "a016_NVMMRecordError" 15 "a015_NVMMError" 13 "a013_AlertManagerFault" 12 "a012_CPUReset" 6 "a006_CANTX_cyclicError" 5 "a005_CANTXError" 3 "a003_SWAssertion" 2 "a002_PowerLossReset" 1 "a001_WatchdogReset" 0 "ALERT_DO_NOT_USE_ZERO" ;
VAL_ 1208 ICR_alertState 1 "SET" 0 "CLEARED" ;
VAL_ 2028 ICR_matrixIndex 2 "AlertMatrix2" 1 "AlertMatrix1" 0 "AlertMatrix0" ;
VAL_ 941 ICR_infoIndex 255 "END" 31 "SUBCOMPONENT_GITHASH" 30 "PACKAGE_SN_8_14" 29 "PACKAGE_SN_1_7" 27 "PACKAGE_PN_15_20" 26 "PACKAGE_PN_8_14" 25 "PACKAGE_PN_1_7" 23 "SUBCOMPONENT2" 22 "VARIANTCRC" 20 "UDS_PROTOCOL_BOOTCRC" 19 "VERSION_DEPRECATED" 18 "BOOTLOADER_GITHASH" 17 "APP_GITHASH" 16 "SUBCOMPONENT" 15 "BOOTLOADER_CRC" 14 "BOOTLOADER_SVN" 13 "APP_CRC" 11 "PCBAID_ASSYID_USAGEID" 10 "BUILD_HWID_COMPONENTID" 9 "DEPRECATED_9" 8 "DEPRECATED_8" 7 "DEPRECATED_7" 6 "DEPRECATED_6" 5 "DEPRECATED_5" 4 "DEPRECATED_4" 3 "DEPRECATED_3" 2 "DEPRECATED_2" 1 "DEPRECATED_1" 0 "DEPRECATED_0" ;
VAL_ 941 ICR_infoBuildType 4 "INFO_MFG_BUILD" 3 "INFO_TRACEABLE_CI_BUILD" 2 "INFO_LOCAL_BUILD" 1 "INFO_PLATFORM_BUILD" 0 "INFO_UNKNOWN_BUILD" ;
VAL_ 667 ICR_lifePresenceMLOutput 255 "SNA" ;
VAL_ 667 ICR_largeOccupantPresenceMLOutpu 255 "SNA" ;
VAL_ 667 ICR_lifePresenceRaw 2 "LIFE_DETECTED" 1 "LIFE_NOT_DETECTED" 0 "LIFE_DETECTED_SNA" ;
VAL_ 667 ICR_lifePresenceFilt 2 "LIFE_DETECTED" 1 "LIFE_NOT_DETECTED" 0 "LIFE_DETECTED_SNA" ;
VAL_ 667 ICR_largeOccupantPresenceRaw 3 "SBRStatus_SEAT_SNA" 2 "SBRStatus_SEAT_FAULTED" 1 "SBRStatus_SEAT_OCCUPIED" 0 "SBRStatus_SEAT_UNOCCUPIED" ;
VAL_ 667 ICR_largeOccupantPresenceFilt 3 "SBRStatus_SEAT_SNA" 2 "SBRStatus_SEAT_FAULTED" 1 "SBRStatus_SEAT_OCCUPIED" 0 "SBRStatus_SEAT_UNOCCUPIED" ;
VAL_ 667 ICR_childPresenceFunctionality 2 "CHILD_PRESENCE_SNA" 1 "CHILD_PRESENCE_ENABLED" 0 "CHILD_PRESENCE_DISABLED" ;
VAL_ 667 ICR_userPresenceFunctionality 2 "CHILD_PRESENCE_SNA" 1 "CHILD_PRESENCE_ENABLED" 0 "CHILD_PRESENCE_DISABLED" ;
VAL_ 667 ICR_userPresenceMLOutput 255 "SNA" ;
VAL_ 667 ICR_userPresenceRaw 3 "SBRStatus_SEAT_SNA" 2 "SBRStatus_SEAT_FAULTED" 1 "SBRStatus_SEAT_OCCUPIED" 0 "SBRStatus_SEAT_UNOCCUPIED" ;
VAL_ 667 ICR_userPresenceFilt 3 "SBRStatus_SEAT_SNA" 2 "SBRStatus_SEAT_FAULTED" 1 "SBRStatus_SEAT_OCCUPIED" 0 "SBRStatus_SEAT_UNOCCUPIED" ;
VAL_ 2027 ICR_occupancy1LRaw 3 "SBRStatus_SEAT_SNA" 2 "SBRStatus_SEAT_FAULTED" 1 "SBRStatus_SEAT_OCCUPIED" 0 "SBRStatus_SEAT_UNOCCUPIED" ;
VAL_ 2027 ICR_occupancy1RRaw 3 "SBRStatus_SEAT_SNA" 2 "SBRStatus_SEAT_FAULTED" 1 "SBRStatus_SEAT_OCCUPIED" 0 "SBRStatus_SEAT_UNOCCUPIED" ;
VAL_ 2027 ICR_occupancy1LFilt 3 "SBRStatus_SEAT_SNA" 2 "SBRStatus_SEAT_FAULTED" 1 "SBRStatus_SEAT_OCCUPIED" 0 "SBRStatus_SEAT_UNOCCUPIED" ;
VAL_ 2027 ICR_occupancy1RFilt 3 "SBRStatus_SEAT_SNA" 2 "SBRStatus_SEAT_FAULTED" 1 "SBRStatus_SEAT_OCCUPIED" 0 "SBRStatus_SEAT_UNOCCUPIED" ;
VAL_ 2027 ICR_occupancy2LFilt 3 "SBRStatus_SEAT_SNA" 2 "SBRStatus_SEAT_FAULTED" 1 "SBRStatus_SEAT_OCCUPIED" 0 "SBRStatus_SEAT_UNOCCUPIED" ;
VAL_ 2027 ICR_occupancy2CFilt 3 "SBRStatus_SEAT_SNA" 2 "SBRStatus_SEAT_FAULTED" 1 "SBRStatus_SEAT_OCCUPIED" 0 "SBRStatus_SEAT_UNOCCUPIED" ;
VAL_ 2027 ICR_occupancy2RFilt 3 "SBRStatus_SEAT_SNA" 2 "SBRStatus_SEAT_FAULTED" 1 "SBRStatus_SEAT_OCCUPIED" 0 "SBRStatus_SEAT_UNOCCUPIED" ;
VAL_ 2027 ICR_occupancy1RFiltExp 3 "SBRStatus_SEAT_SNA" 2 "SBRStatus_SEAT_FAULTED" 1 "SBRStatus_SEAT_OCCUPIED" 0 "SBRStatus_SEAT_UNOCCUPIED" ;
VAL_ 670 ICR_classification1RFilt 4 "OCCUPANT_CLASSIFICATION_OCCUPIED_ALLOW" 3 "OCCUPANT_CLASSIFICATION_OCCUPIED_INHIBIT" 2 "OCCUPANT_CLASSIFICATION_EMPTY" 1 "OCCUPANT_CLASSIFICATION_INIT" 0 "OCCUPANT_CLASSIFICATION_SNA" ;
VAL_ 670 ICR_classification1LRaw 4 "OCCUPANT_CLASSIFICATION_OCCUPIED_ALLOW" 3 "OCCUPANT_CLASSIFICATION_OCCUPIED_INHIBIT" 2 "OCCUPANT_CLASSIFICATION_EMPTY" 1 "OCCUPANT_CLASSIFICATION_INIT" 0 "OCCUPANT_CLASSIFICATION_SNA" ;
VAL_ 670 ICR_classification1RRaw 4 "OCCUPANT_CLASSIFICATION_OCCUPIED_ALLOW" 3 "OCCUPANT_CLASSIFICATION_OCCUPIED_INHIBIT" 2 "OCCUPANT_CLASSIFICATION_EMPTY" 1 "OCCUPANT_CLASSIFICATION_INIT" 0 "OCCUPANT_CLASSIFICATION_SNA" ;
VAL_ 670 ICR_classification1LMLOutput 255 "SNA" ;
VAL_ 670 ICR_classification1RMLOutput 255 "SNA" ;
VAL_ 670 ICR_classification1LqF 1 "OCCUPANT_CLASSIFICATION_NOT_FAULTED" 0 "OCCUPANT_CLASSIFICATION_FAULTED" ;
VAL_ 670 ICR_blockageClutterFar -16 "SNA" ;
VAL_ 670 ICR_blockageClutterNear -16 "SNA" ;
VAL_ 670 ICR_classification1LFilt 4 "OCCUPANT_CLASSIFICATION_OCCUPIED_ALLOW" 3 "OCCUPANT_CLASSIFICATION_OCCUPIED_INHIBIT" 2 "OCCUPANT_CLASSIFICATION_EMPTY" 1 "OCCUPANT_CLASSIFICATION_INIT" 0 "OCCUPANT_CLASSIFICATION_SNA" ;
VAL_ 670 ICR_classification1RqF 1 "OCCUPANT_CLASSIFICATION_NOT_FAULTED" 0 "OCCUPANT_CLASSIFICATION_FAULTED" ;
VAL_ 670 ICR_classification1LLatched 4 "OCCUPANT_CLASSIFICATION_OCCUPIED_ALLOW" 3 "OCCUPANT_CLASSIFICATION_OCCUPIED_INHIBIT" 2 "OCCUPANT_CLASSIFICATION_EMPTY" 1 "OCCUPANT_CLASSIFICATION_INIT" 0 "OCCUPANT_CLASSIFICATION_SNA" ;
VAL_ 670 ICR_classification1RLatched 4 "OCCUPANT_CLASSIFICATION_OCCUPIED_ALLOW" 3 "OCCUPANT_CLASSIFICATION_OCCUPIED_INHIBIT" 2 "OCCUPANT_CLASSIFICATION_EMPTY" 1 "OCCUPANT_CLASSIFICATION_INIT" 0 "OCCUPANT_CLASSIFICATION_SNA" ;
VAL_ 2025 ICR_sensorMode 15 "ICR_SENSOR_INTERFACE_MODE_ERROR" 7 "ICR_SENSOR_INTERFACE_MODE_LPM_TEST" 6 "ICR_SENSOR_INTERFACE_MODE_OCCUPANCY_DETECTION" 5 "ICR_SENSOR_INTERFACE_MODE_HPM_TEST" 4 "ICR_SENSOR_INTERFACE_MODE_CALIBRATION" 3 "ICR_SENSOR_INTERFACE_MODE_CW" 2 "ICR_SENSOR_MODE_END_OF_LINE_TEST" 1 "ICR_SENSOR_MODE_INTRUSTION" 0 "ICR_SENSOR_MODE_SENSOR_STOPPED" ;
VAL_ 2025 ICR_blocked 2 "ICR_BLOCKED_TRUE" 1 "ICR_BLOCKED_FALSE" 0 "ICR_BLOCKED_SNA" ;
VAL_ 2025 ICR_algoVersion 37 "ICR_ALGO_VERSION_FUTURE_RELEASE_37" 36 "ICR_ALGO_VERSION_v06112025" 35 "ICR_ALGO_VERSION_v04232025" 34 "ICR_ALGO_VERSION_v03192025" 33 "ICR_ALGO_VERSION_v02142025" 32 "ICR_ALGO_VERSION_v01222025" 31 "ICR_ALGO_VERSION_v10072024" 30 "ICR_ALGO_VERSION_v08282024" 29 "ICR_ALGO_VERSION_v07172024" 28 "ICR_ALGO_VERSION_v06122024" 27 "ICR_ALGO_VERSION_v04242024" 26 "ICR_ALGO_VERSION_v03142024" 25 "ICR_ALGO_VERSION_v01312024" 24 "ICR_ALGO_VERSION_v12192023" 23 "ICR_ALGO_VERSION_v10252023" 22 "ICR_ALGO_VERSION_v10112023" 21 "ICR_ALGO_VERSION_v09222023" 20 "ICR_ALGO_VERSION_V08302023" 19 "ICR_ALGO_VERSION_V07172023" 18 "ICR_ALGO_VERSION_V06152023" 17 "ICR_ALGO_VERSION_V06072023" 16 "ICR_ALGO_VERSION_V05192023" 15 "ICR_ALGO_VERSION_V04262023" 14 "ICR_ALGO_VERSION_V1222" 13 "ICR_ALGO_VERSION_V1125" 12 "ICR_ALGO_VERSION_V1118" 11 "ICR_ALGO_VERSION_V1103" 10 "ICR_ALGO_VERSION_V1013" 9 "ICR_ALGO_VERSION_V1006" 8 "ICR_ALGO_VERSION_V927" 7 "ICR_ALGO_VERSION_V902" 6 "ICR_ALGO_VERSION_V826" 5 "ICR_ALGO_VERSION_V803" 4 "ICR_ALGO_VERSION_V715" 3 "ICR_ALGO_VERSION_V711" 2 "ICR_ALGO_VERSION_V204" 1 "ICR_ALGO_VERSION_EXPERIMENTAL" 0 "ICR_ALGO_VERSION_NONE" ;
VAL_ 2025 ICR_intrusionStatus 2 "INSTRUSION_STATUS_INTRUSION_DETECTED" 1 "INSTRUSION_STATUS_NONE" 0 "INSTRUSION_STATUS_UNKNOWN" ;
